VERSION ""

NS_ :

BS_:
BU_: Turbocharger OnBoardDataLogger OffBoardDiagnosticTool2 OffBoardDiagnosticTool1 FileServer ParkingBrakeController SeatControl2 FanDriveController SteeringColumnUnit CommunicationUnitRadio CommunicationUnitSatellite CommunicationUnitCellular PropulsionBatteryCharger ChassisController2 ChassisController1 EngineValveControl AuxiliaryHeater2 AuxiliaryHeater1 ClutchUnit RampControl InformationSystem1 SuspensionSystemController2 OilSensor VehicleDynamicStability ExhaustEmissionController TransmissionDisplay2 TransmissionDisplay1 ClimateControl2 WaterPumpController RearAxleSteeringController LightingOperatorControl SeatController1 IgnitionController2 IgnitionController1 TirePressureController CabController2 CabController1 PneumaticSystemController SuspensionSystemController1 HydraulicPumpController EnduranceBrakingSystem RetarderExhaustEngine2 OnBoardDiagnosticUnit HeadwayController RetarderExhaustEngine1 CabDisplay1 ManagementComputer VirtualTerminal OffVehicleGateway PowerTakeOffFront HitchControl AuxiliaryValveControl BodyController TractorTrailerBridge1 StarterSystem ElectricalSystem VehicleSecurity VehicleNavigation AerodynamicControl ElectricalChargingSystem ClimateControl1 TripRecorder InstrumentCluster SuspensionDriveAxle2 SuspensionDriveAxle1 SuspensionSteerAxle SteeringController FuelSystem CruiseControl RetarderDriveline RetarderEngine BrakesDriveAxle2 BrakesDriveAxle1 BrakesSystemController BrakesSteerAxle AxleDrive2 AxleDrive1 AxleSteering PowerTakeOff ShiftConsoleSecondary ShiftConsolePrimary Transmission2 Transmission1 Engine2 Engine1 Guidance Unnamed9933

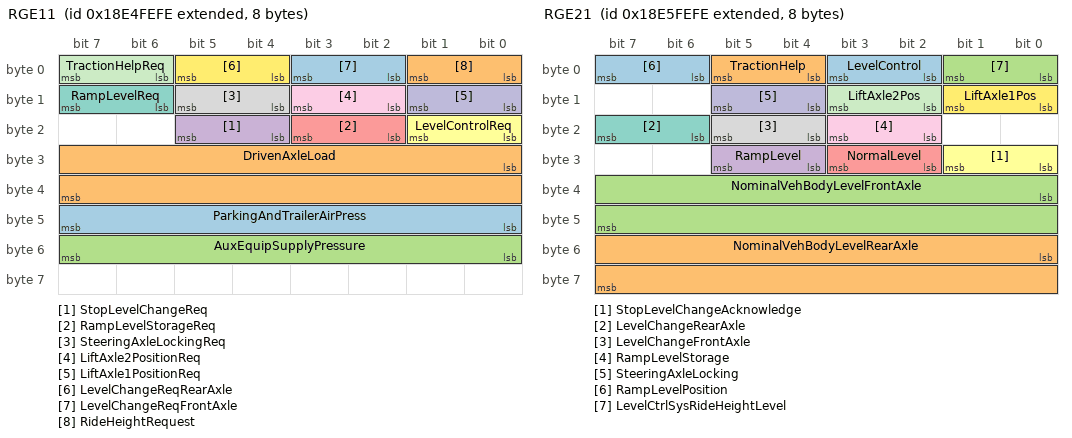
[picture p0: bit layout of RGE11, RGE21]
BO_ 2565144318 RGE11: 8 Vector__XXX
   SG_ ParkingAndTrailerAirPress : 40|8@1+ (8,0) [0|2000] "kPa" Vector__XXX
   SG_ DrivenAxleLoad : 24|16@1+ (2,0) [0|128510] "kg" Vector__XXX
   SG_ AuxEquipSupplyPressure : 48|8@1+ (8,0) [0|2000] "kPa" Vector__XXX
   SG_ StopLevelChangeReq : 20|2@1+ (1,0) [0|3] "" Vector__XXX
   SG_ RampLevelStorageReq : 18|2@1+ (1,0) [0|3] "" Vector__XXX
   SG_ LevelControlReq : 16|2@1+ (1,0) [0|3] "" Vector__XXX
   SG_ RampLevelReq : 14|2@1+ (1,0) [0|3] "" Vector__XXX
   SG_ SteeringAxleLockingReq : 12|2@1+ (1,0) [0|3] "" Vector__XXX
   SG_ LiftAxle2PositionReq : 10|2@1+ (1,0) [0|3] "" Vector__XXX
   SG_ LiftAxle1PositionReq : 8|2@1+ (1,0) [0|3] "" Vector__XXX
   SG_ TractionHelpReq : 6|2@1+ (1,0) [0|3] "" Vector__XXX
   SG_ LevelChangeReqRearAxle : 4|2@1+ (1,0) [0|3] "" Vector__XXX
   SG_ LevelChangeReqFrontAxle : 2|2@1+ (1,0) [0|3] "" Vector__XXX
   SG_ RideHeightRequest : 0|2@1+ (1,0) [0|3] "" Vector__XXX

BO_ 2565209854 RGE21: 8 Vector__XXX
   SG_ LevelControl : 2|2@1+ (1,0) [0|1] "" Vector__XXX
   SG_ NominalVehBodyLevelRearAxle : 48|16@1+ (1,0) [0|64255] "mm" Vector__XXX
   SG_ NominalVehBodyLevelFrontAxle : 32|16@1+ (1,0) [0|64255] "mm" Vector__XXX
   SG_ RampLevel : 28|2@1+ (1,0) [0|1] "" Vector__XXX
   SG_ NormalLevel : 26|2@1+ (1,0) [0|3] "" Vector__XXX
   SG_ StopLevelChangeAcknowledge : 24|2@1+ (1,0) [0|1] "" Vector__XXX
   SG_ LevelChangeRearAxle : 22|2@1+ (1,0) [0|1] "" Vector__XXX
   SG_ LevelChangeFrontAxle : 20|2@1+ (1,0) [0|1] "" Vector__XXX
   SG_ RampLevelStorage : 18|2@1+ (1,0) [0|1] "" Vector__XXX
   SG_ SteeringAxleLocking : 12|2@1+ (1,0) [0|3] "" Vector__XXX
   SG_ LiftAxle2Pos : 10|2@1+ (1,0) [0|3] "" Vector__XXX
   SG_ LiftAxle1Pos : 8|2@1+ (1,0) [0|3] "" Vector__XXX
   SG_ RampLevelPosition : 6|2@1+ (1,0) [0|3] "" Vector__XXX
   SG_ TractionHelp : 4|2@1+ (1,0) [0|1] "" Vector__XXX
   SG_ LevelCtrlSysRideHeightLevel : 0|2@1+ (1,0) [0|1] "" Vector__XXX

BO_ 2566806782 RGE22: 8 Vector__XXX
   SG_ RelVehBodyLevelRearAxle : 16|16@1+ (1,0) [0|64255] "mm" Vector__XXX
   SG_ RelVehBodyLevelFrontAxle : 0|16@1+ (1,-32000) [-32000|32255] "mm" Vector__XXX

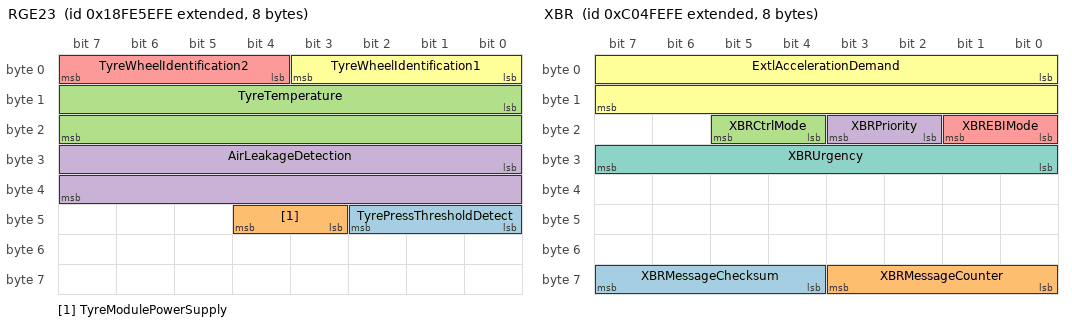
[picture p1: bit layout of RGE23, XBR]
BO_ 2566807294 RGE23: 8 Vector__XXX
   SG_ TyrePressThresholdDetect : 40|3@1+ (1,0) [0|7] "" Vector__XXX
   SG_ TyreModulePowerSupply : 43|2@1+ (1,0) [0|1] "" Vector__XXX
   SG_ TyreTemperature : 8|16@1+ (0.03125,-273) [-273|1735] "deg C" Vector__XXX
   SG_ AirLeakageDetection : 24|16@1+ (0.1,0) [0|6425.5] "Pa/s" Vector__XXX
   SG_ TyreWheelIdentification2 : 4|4@1+ (1,0) [0|15] "" Vector__XXX
   SG_ TyreWheelIdentification1 : 0|4@1+ (1,0) [0|15] "" Vector__XXX

BO_ 2566764798 DM26: 8 Vector__XXX
   SG_ NMHCConvertingCatalystCompleted : 60|1@1+ (1,0) [0|1] "" Vector__XXX
   SG_ NMHCConvertingCatalystEnabled : 44|1@1+ (1,0) [0|1] "" Vector__XXX
   SG_ NOxConvertingCatalystAdsorberCom : 59|1@1+ (1,0) [0|1] "" Vector__XXX
   SG_ NOxConvertingCatalystAdsorberEna : 43|1@1+ (1,0) [0|1] "" Vector__XXX
   SG_ DieselParticulateFilterCompleted : 58|1@1+ (1,0) [0|1] "" Vector__XXX
   SG_ DieselParticulateFilterEnabled : 42|1@1+ (1,0) [0|1] "" Vector__XXX
   SG_ BoostPressureControlSystemComple : 57|1@1+ (1,0) [0|1] "" Vector__XXX
   SG_ BoostPressureCtrlSystemEnabled : 41|1@1+ (1,0) [0|1] "" Vector__XXX
   SG_ MisfireMonitoringComplete : 28|1@1+ (1,0) [0|1] "" Vector__XXX
   SG_ MisfireMonitoringEnabled : 24|1@1+ (1,0) [0|0] "" Vector__XXX
   SG_ FuelSystemMonitoringEnabled : 25|1@1+ (1,0) [0|1] "" Vector__XXX
   SG_ ComprehensiveComptMonComplete : 30|1@1+ (1,0) [0|1] "" Vector__XXX
   SG_ ComprehensiveCompMonEnabled : 26|1@1+ (1,0) [0|1] "" Vector__XXX
   SG_ SecondAirSystemMonComplete : 51|1@1+ (1,0) [0|1] "" Vector__XXX
   SG_ SecondAirSystemMonEnabled : 35|1@1+ (1,0) [0|1] "" Vector__XXX
   SG_ OxygenSensorMonComplete : 53|1@1+ (1,0) [0|1] "" Vector__XXX
   SG_ OxygenSensorMonEnabled : 37|1@1+ (1,0) [0|1] "" Vector__XXX
   SG_ OxygenSensorHeaterMonComplete : 54|1@1+ (1,0) [0|1] "" Vector__XXX
   SG_ OxygenSensorHeaterMonEnabled : 38|1@1+ (1,0) [0|1] "" Vector__XXX
   SG_ HeatedCatalystMonComplete : 49|1@1+ (1,0) [0|1] "" Vector__XXX
   SG_ HeatedCatalystMonEnabled : 33|1@1+ (1,0) [0|1] "" Vector__XXX
   SG_ EvaporativeSystemMonComplete : 50|1@1+ (1,0) [0|1] "" Vector__XXX
   SG_ EvaporativeSystemMonEnabled : 34|1@1+ (1,0) [0|1] "" Vector__XXX
   SG_ EGRSystemMonitoringComplete : 55|1@1+ (1,0) [0|1] "" Vector__XXX
   SG_ EGRSystemMonitoringEnabled : 39|1@1+ (1,0) [0|1] "" Vector__XXX
   SG_ ColdStartAidSystemMonComplete : 56|1@1+ (1,0) [0|1] "" Vector__XXX
   SG_ ColdStartAidSystemMonEnabled : 40|1@1+ (1,0) [0|1] "" Vector__XXX
   SG_ CatalystMonComplete : 48|1@1+ (1,0) [0|1] "" Vector__XXX
   SG_ CatalystMonEnabled : 32|1@1+ (1,0) [0|1] "" Vector__XXX
   SG_ ACSystemRefrigerantMonComplete : 52|1@1+ (1,0) [0|1] "" Vector__XXX
   SG_ ACSystemRefrigerantMonEnabled : 36|1@1+ (1,0) [0|1] "" Vector__XXX
   SG_ FuelSystemMonitoringComplete : 29|1@1+ (1,0) [0|1] "" Vector__XXX
   SG_ NumOfWarmUpsSinceDTCsCleared : 16|8@1+ (1,0) [0|250] "" Vector__XXX
   SG_ TimeSinceEngineStart : 0|16@1+ (1,0) [0|64255] "sec" Vector__XXX

BO_ 2564095742 DM18: 8 Vector__XXX
   SG_ SecurityEntityLengthHigh : 12|4@1+ (1,0) [0|255] "Byte" Vector__XXX
   SG_ SecurityEntityType : 8|4@1+ (1,0) [0|15] "" Vector__XXX
   SG_ SecurityEntityLength : 0|8@1+ (1,0) [0|1785] "Byte" Vector__XXX

BO_ 2349137662 XBR: 8 Vector__XXX
   SG_ XBRMessageChecksum : 60|4@1+ (1,0) [0|15] "" Vector__XXX
   SG_ XBRMessageCounter : 56|4@1+ (1,0) [0|15] "" Vector__XXX
   SG_ XBRCtrlMode : 20|2@1+ (1,0) [0|3] "" Vector__XXX
   SG_ XBRPriority : 18|2@1+ (1,0) [0|3] "" Vector__XXX
   SG_ XBREBIMode : 16|2@1+ (1,0) [0|3] "" Vector__XXX
   SG_ ExtlAccelerationDemand : 0|16@1+ (0.000488281,-15.687) [-15.687|15.687] "m/s/s" Vector__XXX
   SG_ XBRUrgency : 24|8@1+ (0.4,0) [0|100] "%" Vector__XXX

BO_ 2566848510 WFI: 8 Vector__XXX
   SG_ WaterInFuelIndicator : 0|2@1+ (1,0) [0|3] "" Vector__XXX

BO_ 2566843134 VW: 8 Vector__XXX
   SG_ AxleLocation M : 0|8@1+ (1,0) [0|255] "" Vector__XXX
   SG_ CargoWeight_30 m48 : 40|16@1+ (2,0) [0|128510] "kg" Vector__XXX
   SG_ CargoWeight_20 m32 : 40|16@1+ (2,0) [0|128510] "kg" Vector__XXX
   SG_ CargoWeight_10 m16 : 40|16@1+ (2,0) [0|128510] "kg" Vector__XXX
   SG_ CargoWeight_00 m0 : 40|16@1+ (2,0) [0|128510] "kg" Vector__XXX
   SG_ TrailerWeight_30 m48 : 24|16@1+ (2,0) [0|128510] "kg" Vector__XXX
   SG_ TrailerWeight_20 m32 : 24|16@1+ (2,0) [0|128510] "kg" Vector__XXX
   SG_ TrailerWeight_10 m16 : 24|16@1+ (2,0) [0|128510] "kg" Vector__XXX
   SG_ TrailerWeight_00 m0 : 24|16@1+ (2,0) [0|128510] "kg" Vector__XXX
   SG_ AxleWeight_30 m48 : 8|16@1+ (0.5,0) [0|32127.5] "kg" Vector__XXX
   SG_ AxleWeight_20 m32 : 8|16@1+ (0.5,0) [0|32127.5] "kg" Vector__XXX
   SG_ AxleWeight_10 m16 : 8|16@1+ (0.5,0) [0|32127.5] "kg" Vector__XXX
   SG_ AxleWeight_00 m0 : 8|16@1+ (0.5,0) [0|32127.5] "kg" Vector__XXX

BO_ 2566804222 VEP3: 8 Vector__XXX
   SG_ NetBatteryCurrentHiRes : 16|16@1+ (0.05,-1600) [-1600|1612.75] "A" Vector__XXX
   SG_ AltCurrentHiRes : 0|16@1+ (0.05,-1600) [-1600|1676.75] "A" Vector__XXX

BO_ 2633928190 VEP2: 8 Vector__XXX
   SG_ ECUPowerOutputSupplyVoltage3 : 48|16@1+ (0.05,0) [0|3212.75] "V" Vector__XXX
   SG_ ECUPowerOutputSupplyVoltage2 : 32|16@1+ (0.05,0) [0|3212.75] "V" Vector__XXX
   SG_ ECUPowerOutputSupplyVoltage1 : 16|16@1+ (0.05,0) [0|3212.75] "V" Vector__XXX
   SG_ BatteryPotential_PowerInput2 : 0|16@1+ (0.05,0) [0|3212.75] "V" Vector__XXX

BO_ 2566845438 VP: 8 Vector__XXX
   SG_ Longitude : 32|32@1+ (10,-210) [-210|211.101] "deg" Vector__XXX
   SG_ Latitude : 0|32@1+ (10,-210) [-210|211.101] "deg" Vector__XXX

BO_ 2566843646 VI: 8 Vector__XXX
   SG_ VehicleIdentificationNumber : 0|8@1+ (1,0) [0|255] "" Vector__XXX

BO_ 2566842366 VH: 8 Vector__XXX
   SG_ TotalPowerTakeoffHours : 32|32@1+ (0.05,0) [0|2.10554e+08] "hr" Vector__XXX
   SG_ TotalVehicleHours : 0|32@1+ (0.05,0) [0|2.10554e+08] "hr" Vector__XXX

BO_ 2566809854 VF: 8 Vector__XXX
   SG_ WinchOilPressSwitch : 10|2@1+ (1,0) [0|3] "" Vector__XXX
   SG_ HydOilLevel : 16|8@1+ (0.4,0) [0|100] "%" Vector__XXX
   SG_ HydOilFilterRestrictionSwitch : 8|2@1+ (1,0) [0|3] "" Vector__XXX
   SG_ HydTemp : 0|8@1+ (1,-40) [-40|210] "deg C" Vector__XXX

BO_ 2566842622 VDS: 8 Vector__XXX
   SG_ Altitude : 48|16@1+ (0.125,-2500) [-2500|5531.88] "m" Vector__XXX
   SG_ Pitch : 32|16@1+ (0.0078125,-200) [-200|301.99] "deg" Vector__XXX
   SG_ NavigationBasedVehicleSpeed : 16|16@1+ (0.00390625,0) [0|250.996] "km/h" Vector__XXX
   SG_ CompassBearing : 0|16@1+ (0.0078125,0) [0|501.99] "deg" Vector__XXX

BO_ 2566832638 VDHR: 8 Vector__XXX
   SG_ HighResolutionTripDistance : 32|32@1+ (5,0) [0|2.10554e+07] "km" Vector__XXX
   SG_ HghRslutionTotalVehicleDistance : 0|32@1+ (5,0) [0|2.10554e+07] "km" Vector__XXX

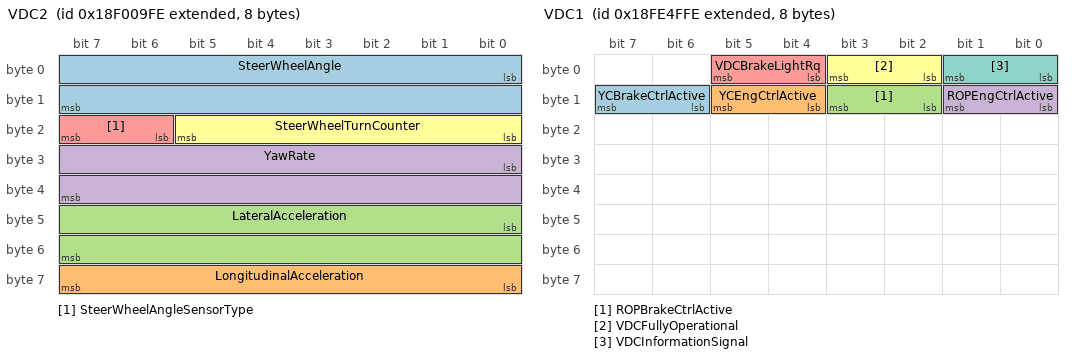
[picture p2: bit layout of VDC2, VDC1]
BO_ 2565868030 VDC2: 8 Vector__XXX
   SG_ SteerWheelAngle : 0|16@1+ (0.000976563,-31.374) [-31.374|31.374] "rad" Vector__XXX
   SG_ LongitudinalAcceleration : 56|8@1+ (0.1,-12.5) [-12.5|12.5] "m/s/s" Vector__XXX
   SG_ LateralAcceleration : 40|16@1+ (0.000488281,-15.687) [-15.687|15.687] "m/s/s" Vector__XXX
   SG_ YawRate : 24|16@1+ (0.00012207,-3.92) [-3.92|3.92] "rad/s" Vector__XXX
   SG_ SteerWheelAngleSensorType : 22|2@1+ (1,0) [0|3] "" Vector__XXX
   SG_ SteerWheelTurnCounter : 16|6@1+ (1,-32) [-32|29] "turns" Vector__XXX

BO_ 2566803454 VDC1: 8 Vector__XXX
   SG_ YCBrakeCtrlActive : 14|2@1+ (1,0) [0|3] "" Vector__XXX
   SG_ YCEngCtrlActive : 12|2@1+ (1,0) [0|3] "" Vector__XXX
   SG_ ROPBrakeCtrlActive : 10|2@1+ (1,0) [0|3] "" Vector__XXX
   SG_ ROPEngCtrlActive : 8|2@1+ (1,0) [0|3] "" Vector__XXX
   SG_ VDCBrakeLightRq : 4|2@1+ (1,0) [0|3] "" Vector__XXX
   SG_ VDCFullyOperational : 2|2@1+ (1,0) [0|3] "" Vector__XXX
   SG_ VDCInformationSignal : 0|2@1+ (1,0) [0|3] "" Vector__XXX

BO_ 2566840574 VD: 8 Vector__XXX
   SG_ TotalVehicleDistance : 32|32@1+ (0.125,0) [0|5.26385e+08] "km" Vector__XXX
   SG_ TripDistance : 0|32@1+ (0.125,0) [0|5.26385e+08] "km" Vector__XXX

BO_ 2633938686 TVI: 8 Vector__XXX
   SG_ TripCruiseDistance : 16|32@1+ (0.125,0) [0|5.26385e+08] "km" Vector__XXX
   SG_ TripMaxVehicleSpeed : 0|16@1+ (0.00390625,0) [0|250.996] "km/h" Vector__XXX

BO_ 2633937150 TTI2: 20 Vector__XXX
   SG_ TripAirCompressorOnTime : 128|32@1+ (0.05,0) [0|2.10554e+08] "hr" Vector__XXX
   SG_ TripIdleTime : 96|32@1+ (0.05,0) [0|2.10554e+08] "hr" Vector__XXX
   SG_ TripEngRunningTime : 64|32@1+ (0.05,0) [0|2.10554e+08] "hr" Vector__XXX
   SG_ TripCruiseTime : 0|32@1+ (0.05,0) [0|2.10554e+08] "hr" Vector__XXX
   SG_ TripPTOGovernorTime : 32|32@1+ (0.05,0) [0|2.10554e+08] "hr" Vector__XXX

BO_ 2633938174 TTI1: 16 Vector__XXX
   SG_ TripTimeInDerateByEng : 96|32@1+ (0.05,0) [0|2.10554e+08] "hr" Vector__XXX
   SG_ TripTimeInGearDown : 64|32@1+ (0.05,0) [0|2.10554e+08] "hr" Vector__XXX
   SG_ TripTimeInTopGear : 32|32@1+ (0.05,0) [0|2.10554e+08] "hr" Vector__XXX
   SG_ TripTimeInVSL : 0|32@1+ (0.05,0) [0|2.10554e+08] "hr" Vector__XXX

BO_ 2633938430 TSI: 8 Vector__XXX
   SG_ TripSuddenDecelerations : 48|16@1+ (1,0) [0|64255] "counts" Vector__XXX
   SG_ TrpNmberOfIdleShutdownOverrides : 32|16@1+ (1,0) [0|64255] "counts" Vector__XXX
   SG_ TripNumberOfIdleShutdowns : 16|16@1+ (1,0) [0|64255] "counts" Vector__XXX
   SG_ TripNumberOfHotShutdowns : 0|16@1+ (1,0) [0|64255] "counts" Vector__XXX

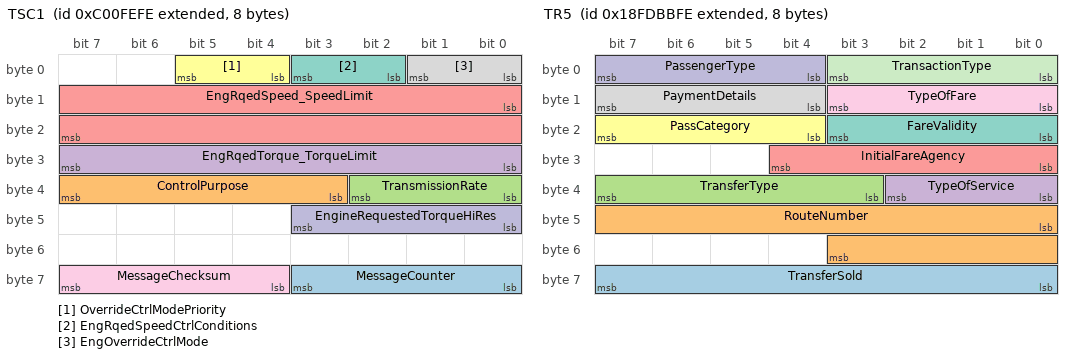
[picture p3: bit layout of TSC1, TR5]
BO_ 2348875518 TSC1: 8 Vector__XXX
   SG_ MessageCounter : 56|4@1+ (1,0) [0|15] "" Vector__XXX
   SG_ ControlPurpose : 35|5@1+ (1,0) [0|31] "" Vector__XXX
   SG_ TransmissionRate : 32|3@1+ (1,0) [0|7] "" Vector__XXX
   SG_ EngRqedTorque_TorqueLimit : 24|8@1+ (1,-125) [-125|125] "%" Vector__XXX
   SG_ EngRqedSpeed_SpeedLimit : 8|16@1+ (0.125,0) [0|8031.88] "rpm" Vector__XXX
   SG_ OverrideCtrlModePriority : 4|2@1+ (1,0) [0|3] "" Vector__XXX
   SG_ EngRqedSpeedCtrlConditions : 2|2@1+ (1,0) [0|3] "" Vector__XXX
   SG_ EngOverrideCtrlMode : 0|2@1+ (1,0) [0|3] "" Vector__XXX
   SG_ MessageChecksum : 60|4@1+ (1,0) [0|15] "" Vector__XXX
   SG_ EngineRequestedTorqueHiRes : 40|4@1+ (0.125,0) [0|0.875] "%" Vector__XXX

BO_ 2566766846 TR7: 8 Vector__XXX
   SG_ TransitRunStatus : 20|2@1+ (1,0) [0|3] "" Vector__XXX
   SG_ VehicleUseStatus : 18|2@1+ (1,0) [0|3] "" Vector__XXX
   SG_ SilentAlarmStatus : 16|2@1+ (1,0) [0|3] "" Vector__XXX
   SG_ PatronCount : 8|8@1+ (1,0) [0|250] "" Vector__XXX
   SG_ TypeOfPassengerCount : 0|8@1+ (1,0) [0|255] "" Vector__XXX

BO_ 2566765310 TR6: 8 Vector__XXX
   SG_ FareboxAlarmIdentifier : 8|7@1+ (1,0) [0|127] "" Vector__XXX
   SG_ FareboxEmergencyStatus : 0|2@1+ (1,0) [0|3] "" Vector__XXX

BO_ 2566765566 TR5: 8 Vector__XXX
   SG_ TransferSold : 56|8@1+ (1,0) [0|255] "" Vector__XXX
   SG_ RouteNumber : 40|12@1+ (1,0) [0|4095] "" Vector__XXX
   SG_ TransferType : 35|5@1+ (1,0) [0|31] "" Vector__XXX
   SG_ TypeOfService : 32|3@1+ (1,0) [0|7] "" Vector__XXX
   SG_ InitialFareAgency : 24|5@1+ (1,0) [0|31] "" Vector__XXX
   SG_ PassCategory : 20|4@1+ (1,0) [0|15] "" Vector__XXX
   SG_ FareValidity : 16|4@1+ (1,0) [0|15] "" Vector__XXX
   SG_ PaymentDetails : 12|4@1+ (1,0) [0|15] "" Vector__XXX
   SG_ TypeOfFare : 8|4@1+ (1,0) [0|15] "" Vector__XXX
   SG_ PassengerType : 4|4@1+ (1,0) [0|15] "" Vector__XXX
   SG_ TransactionType : 0|4@1+ (1,0) [0|15] "" Vector__XXX

BO_ 2566765822 TR4: 15 Vector__XXX
   SG_ DriversFareboxSecurityCode : 104|16@1+ (1,0) [0|65535] "counts" Vector__XXX
   SG_ AssignedBlock : 88|16@1+ (1,0) [0|65535] "counts" Vector__XXX
   SG_ AssignedRun : 72|16@1+ (1,0) [0|65535] "counts" Vector__XXX
   SG_ AssignedRoute : 56|16@1+ (1,0) [0|65535] "counts" Vector__XXX
   SG_ PatternNumber : 40|16@1+ (1,0) [0|65535] "counts" Vector__XXX
   SG_ TripNumber : 24|16@1+ (1,0) [0|65535] "counts" Vector__XXX
   SG_ FarePresets : 16|8@1+ (1,0) [0|255] "" Vector__XXX
   SG_ TripDirection : 8|4@1+ (1,0) [0|15] "" Vector__XXX
   SG_ TripStatus : 2|3@1+ (1,0) [0|7] "" Vector__XXX
   SG_ FareboxServiceStatus : 0|2@1+ (1,0) [0|3] "" Vector__XXX

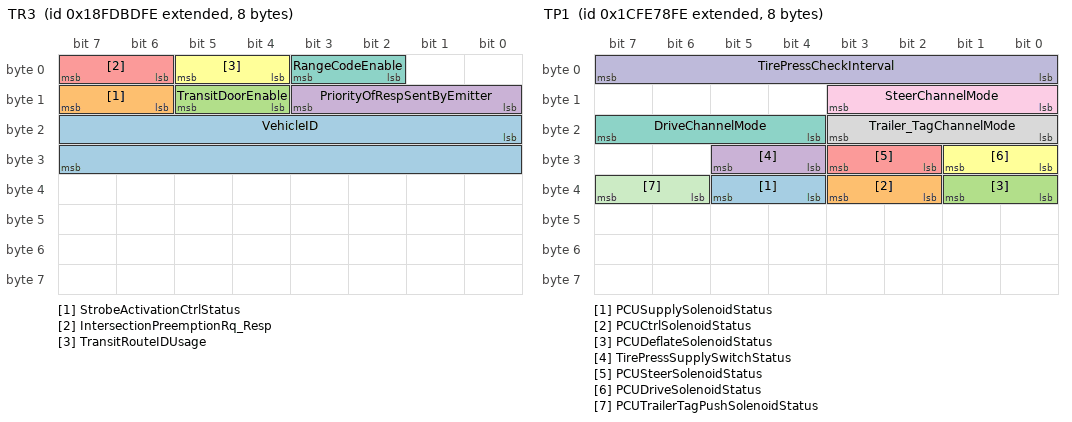
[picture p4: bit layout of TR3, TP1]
BO_ 2566766078 TR3: 8 Vector__XXX
   SG_ VehicleID : 16|16@1+ (1,0) [0|65535] "counts" Vector__XXX
   SG_ StrobeActivationCtrlStatus : 14|2@1+ (1,0) [0|3] "" Vector__XXX
   SG_ TransitDoorEnable : 12|2@1+ (1,0) [0|3] "" Vector__XXX
   SG_ PriorityOfRespSentByEmitter : 8|4@1+ (1,0) [0|15] "" Vector__XXX
   SG_ IntersectionPreemptionRq_Resp : 6|2@1+ (1,0) [0|3] "" Vector__XXX
   SG_ TransitRouteIDUsage : 4|2@1+ (1,0) [0|3] "" Vector__XXX
   SG_ RangeCodeEnable : 2|2@1+ (1,0) [0|3] "" Vector__XXX

BO_ 2566766590 TR2: 8 Vector__XXX
   SG_ NmbrOfBytsInMlpstIdentification : 0|8@1+ (1,0) [0|250] "" Vector__XXX

BO_ 2566766334 TR1: 4 Vector__XXX
   SG_ Agency : 0|8@1+ (1,0) [0|255] "" Vector__XXX
   SG_ NmbrOfBytsInTrnstAssgndBlckIdntt : 24|8@1+ (1,0) [0|250] "" Vector__XXX
   SG_ NmbrOfBytsInTrnstAssgndRnIdntty : 16|8@1+ (1,0) [0|250] "" Vector__XXX
   SG_ NmbrOfBytsInTrnstAssgndRtIdntty : 8|8@1+ (1,0) [0|250] "" Vector__XXX

BO_ 2561605374 TPRS: 8 Vector__XXX
   SG_ ReferenceTirePressSetting_33 m51 : 8|8@1+ (8,0) [0|2000] "kPa" Vector__XXX
   SG_ ReferenceTirePressSetting_32 m50 : 8|8@1+ (8,0) [0|2000] "kPa" Vector__XXX
   SG_ ReferenceTirePressSetting_31 m49 : 8|8@1+ (8,0) [0|2000] "kPa" Vector__XXX
   SG_ ReferenceTirePressSetting_30 m48 : 8|8@1+ (8,0) [0|2000] "kPa" Vector__XXX
   SG_ ReferenceTirePressSetting_23 m35 : 8|8@1+ (8,0) [0|2000] "kPa" Vector__XXX
   SG_ ReferenceTirePressSetting_22 m34 : 8|8@1+ (8,0) [0|2000] "kPa" Vector__XXX
   SG_ ReferenceTirePressSetting_21 m33 : 8|8@1+ (8,0) [0|2000] "kPa" Vector__XXX
   SG_ ReferenceTirePressSetting_20 m32 : 8|8@1+ (8,0) [0|2000] "kPa" Vector__XXX
   SG_ ReferenceTirePressSetting_13 m19 : 8|8@1+ (8,0) [0|2000] "kPa" Vector__XXX
   SG_ ReferenceTirePressSetting_12 m18 : 8|8@1+ (8,0) [0|2000] "kPa" Vector__XXX
   SG_ ReferenceTirePressSetting_11 m17 : 8|8@1+ (8,0) [0|2000] "kPa" Vector__XXX
   SG_ ReferenceTirePressSetting_10 m16 : 8|8@1+ (8,0) [0|2000] "kPa" Vector__XXX
   SG_ ReferenceTirePressSetting_01 m1 : 8|8@1+ (8,0) [0|2000] "kPa" Vector__XXX
   SG_ ReferenceTirePressSetting_00 m0 : 8|8@1+ (8,0) [0|2000] "kPa" Vector__XXX
   SG_ TireLocation M : 0|8@1+ (1,0) [0|255] "" Vector__XXX

BO_ 2566765054 TPRI: 8 Vector__XXX
   SG_ ReferenceTirePress_33 m51 : 8|8@1+ (8,0) [0|2000] "kPa" Vector__XXX
   SG_ ReferenceTirePress_32 m50 : 8|8@1+ (8,0) [0|2000] "kPa" Vector__XXX
   SG_ ReferenceTirePress_31 m49 : 8|8@1+ (8,0) [0|2000] "kPa" Vector__XXX
   SG_ ReferenceTirePress_30 m48 : 8|8@1+ (8,0) [0|2000] "kPa" Vector__XXX
   SG_ ReferenceTirePress_23 m35 : 8|8@1+ (8,0) [0|2000] "kPa" Vector__XXX
   SG_ ReferenceTirePress_22 m34 : 8|8@1+ (8,0) [0|2000] "kPa" Vector__XXX
   SG_ ReferenceTirePress_21 m33 : 8|8@1+ (8,0) [0|2000] "kPa" Vector__XXX
   SG_ ReferenceTirePress_20 m32 : 8|8@1+ (8,0) [0|2000] "kPa" Vector__XXX
   SG_ ReferenceTirePress_13 m19 : 8|8@1+ (8,0) [0|2000] "kPa" Vector__XXX
   SG_ ReferenceTirePress_12 m18 : 8|8@1+ (8,0) [0|2000] "kPa" Vector__XXX
   SG_ ReferenceTirePress_11 m17 : 8|8@1+ (8,0) [0|2000] "kPa" Vector__XXX
   SG_ ReferenceTirePress_10 m16 : 8|8@1+ (8,0) [0|2000] "kPa" Vector__XXX
   SG_ ReferenceTirePress_01 m1 : 8|8@1+ (8,0) [0|2000] "kPa" Vector__XXX
   SG_ ReferenceTirePress_00 m0 : 8|8@1+ (8,0) [0|2000] "kPa" Vector__XXX
   SG_ TireLocation M : 0|8@1+ (1,0) [0|255] "" Vector__XXX

BO_ 2633923326 TP3: 8 Vector__XXX
   SG_ SteerChannelTirePress : 32|16@1+ (0.5,0) [0|32127.5] "kPa" Vector__XXX
   SG_ DriveChannelTirePress : 16|16@1+ (0.5,0) [0|32127.5] "kPa" Vector__XXX
   SG_ TrailerTagPushChannelTirePress : 0|16@1+ (0.5,0) [0|32127.5] "kPa" Vector__XXX

BO_ 2633923070 TP2: 8 Vector__XXX
   SG_ SteerChannelTirePressTarget : 32|16@1+ (0.5,0) [0|32127.5] "kPa" Vector__XXX
   SG_ DriveChannelTirePressTarget : 16|16@1+ (0.5,0) [0|32127.5] "kPa" Vector__XXX
   SG_ TrlrTgPshChannelTirePressTarget : 0|16@1+ (0.5,0) [0|32127.5] "kPa" Vector__XXX

BO_ 2633922814 TP1: 8 Vector__XXX
   SG_ PCUSupplySolenoidStatus : 36|2@1+ (1,0) [0|3] "" Vector__XXX
   SG_ PCUCtrlSolenoidStatus : 34|2@1+ (1,0) [0|3] "" Vector__XXX
   SG_ PCUDeflateSolenoidStatus : 32|2@1+ (1,0) [0|3] "" Vector__XXX
   SG_ TirePressSupplySwitchStatus : 28|2@1+ (1,0) [0|3] "" Vector__XXX
   SG_ PCUSteerSolenoidStatus : 26|2@1+ (1,0) [0|3] "" Vector__XXX
   SG_ PCUDriveSolenoidStatus : 24|2@1+ (1,0) [0|3] "" Vector__XXX
   SG_ DriveChannelMode : 20|4@1+ (1,0) [0|15] "" Vector__XXX
   SG_ Trailer_TagChannelMode : 16|4@1+ (1,0) [0|15] "" Vector__XXX
   SG_ SteerChannelMode : 8|4@1+ (1,0) [0|15] "" Vector__XXX
   SG_ TirePressCheckInterval : 0|8@1+ (1,0) [0|250] "mins" Vector__XXX
   SG_ PCUTrailerTagPushSolenoidStatus : 38|2@1+ (1,0) [0|3] "" Vector__XXX

BO_ 2566845694 TIRE: 8 Vector__XXX
   SG_ TirePressThresholdDetection_13 m19 : 61|3@1+ (1,0) [0|7] "" Vector__XXX
   SG_ TirePressThresholdDetection_12 m18 : 61|3@1+ (1,0) [0|7] "" Vector__XXX
   SG_ TirePressThresholdDetection_11 m17 : 61|3@1+ (1,0) [0|7] "" Vector__XXX
   SG_ TirePressThresholdDetection_10 m16 : 61|3@1+ (1,0) [0|7] "" Vector__XXX
   SG_ TirePressThresholdDetection_01 m1 : 61|3@1+ (1,0) [0|7] "" Vector__XXX
   SG_ TirePress_33 m51 : 8|8@1+ (4,0) [0|1000] "kPa" Vector__XXX
   SG_ TirePress_32 m50 : 8|8@1+ (4,0) [0|1000] "kPa" Vector__XXX
   SG_ TirePress_31 m49 : 8|8@1+ (4,0) [0|1000] "kPa" Vector__XXX
   SG_ TirePress_30 m48 : 8|8@1+ (4,0) [0|1000] "kPa" Vector__XXX
   SG_ TirePress_23 m35 : 8|8@1+ (4,0) [0|1000] "kPa" Vector__XXX
   SG_ TirePress_22 m34 : 8|8@1+ (4,0) [0|1000] "kPa" Vector__XXX
   SG_ TirePress_21 m33 : 8|8@1+ (4,0) [0|1000] "kPa" Vector__XXX
   SG_ TirePress_20 m32 : 8|8@1+ (4,0) [0|1000] "kPa" Vector__XXX
   SG_ TirePress_13 m19 : 8|8@1+ (4,0) [0|1000] "kPa" Vector__XXX
   SG_ TirePress_12 m18 : 8|8@1+ (4,0) [0|1000] "kPa" Vector__XXX
   SG_ TirePress_11 m17 : 8|8@1+ (4,0) [0|1000] "kPa" Vector__XXX
   SG_ TirePress_10 m16 : 8|8@1+ (4,0) [0|1000] "kPa" Vector__XXX
   SG_ TireAirLeakageRate_33 m51 : 40|16@1+ (0.1,0) [0|6425.5] "Pa/s" Vector__XXX
   SG_ TireAirLeakageRate_32 m50 : 40|16@1+ (0.1,0) [0|6425.5] "Pa/s" Vector__XXX
   SG_ TireAirLeakageRate_31 m49 : 40|16@1+ (0.1,0) [0|6425.5] "Pa/s" Vector__XXX
   SG_ TireAirLeakageRate_30 m48 : 40|16@1+ (0.1,0) [0|6425.5] "Pa/s" Vector__XXX
   SG_ TireAirLeakageRate_23 m35 : 40|16@1+ (0.1,0) [0|6425.5] "Pa/s" Vector__XXX
   SG_ TireAirLeakageRate_22 m34 : 40|16@1+ (0.1,0) [0|6425.5] "Pa/s" Vector__XXX
   SG_ TireAirLeakageRate_21 m33 : 40|16@1+ (0.1,0) [0|6425.5] "Pa/s" Vector__XXX
   SG_ TireAirLeakageRate_20 m32 : 40|16@1+ (0.1,0) [0|6425.5] "Pa/s" Vector__XXX
   SG_ TireAirLeakageRate_13 m19 : 40|16@1+ (0.1,0) [0|6425.5] "Pa/s" Vector__XXX
   SG_ TireAirLeakageRate_12 m18 : 40|16@1+ (0.1,0) [0|6425.5] "Pa/s" Vector__XXX
   SG_ TireAirLeakageRate_11 m17 : 40|16@1+ (0.1,0) [0|6425.5] "Pa/s" Vector__XXX
   SG_ TireAirLeakageRate_10 m16 : 40|16@1+ (0.1,0) [0|6425.5] "Pa/s" Vector__XXX
   SG_ TireAirLeakageRate_01 m1 : 40|16@1+ (0.1,0) [0|6425.5] "Pa/s" Vector__XXX
   SG_ TireAirLeakageRate_00 m0 : 40|16@1+ (0.1,0) [0|6425.5] "Pa/s" Vector__XXX
   SG_ CTIWheelSensorStatus_33 m51 : 32|2@1+ (1,0) [0|3] "" Vector__XXX
   SG_ CTIWheelSensorStatus_32 m50 : 32|2@1+ (1,0) [0|3] "" Vector__XXX
   SG_ CTIWheelSensorStatus_31 m49 : 32|2@1+ (1,0) [0|3] "" Vector__XXX
   SG_ CTIWheelSensorStatus_30 m48 : 32|2@1+ (1,0) [0|3] "" Vector__XXX
   SG_ CTIWheelSensorStatus_23 m35 : 32|2@1+ (1,0) [0|3] "" Vector__XXX
   SG_ CTIWheelSensorStatus_22 m34 : 32|2@1+ (1,0) [0|3] "" Vector__XXX
   SG_ CTIWheelSensorStatus_21 m33 : 32|2@1+ (1,0) [0|3] "" Vector__XXX
   SG_ CTIWheelSensorStatus_20 m32 : 32|2@1+ (1,0) [0|3] "" Vector__XXX
   SG_ CTIWheelSensorStatus_13 m19 : 32|2@1+ (1,0) [0|3] "" Vector__XXX
   SG_ CTIWheelSensorStatus_12 m18 : 32|2@1+ (1,0) [0|3] "" Vector__XXX
   SG_ CTIWheelSensorStatus_11 m17 : 32|2@1+ (1,0) [0|3] "" Vector__XXX
   SG_ CTIWheelSensorStatus_10 m16 : 32|2@1+ (1,0) [0|3] "" Vector__XXX
   SG_ CTIWheelSensorStatus_01 m1 : 32|2@1+ (1,0) [0|3] "" Vector__XXX
   SG_ CTIWheelEndElectricalFault_33 m51 : 36|2@1+ (1,0) [0|3] "" Vector__XXX
   SG_ CTIWheelEndElectricalFault_32 m50 : 36|2@1+ (1,0) [0|3] "" Vector__XXX
   SG_ CTIWheelEndElectricalFault_31 m49 : 36|2@1+ (1,0) [0|3] "" Vector__XXX
   SG_ CTIWheelEndElectricalFault_30 m48 : 36|2@1+ (1,0) [0|3] "" Vector__XXX
   SG_ CTIWheelEndElectricalFault_23 m35 : 36|2@1+ (1,0) [0|3] "" Vector__XXX
   SG_ CTIWheelEndElectricalFault_22 m34 : 36|2@1+ (1,0) [0|3] "" Vector__XXX
   SG_ CTIWheelEndElectricalFault_21 m33 : 36|2@1+ (1,0) [0|3] "" Vector__XXX
   SG_ CTIWheelEndElectricalFault_20 m32 : 36|2@1+ (1,0) [0|3] "" Vector__XXX
   SG_ CTIWheelEndElectricalFault_13 m19 : 36|2@1+ (1,0) [0|3] "" Vector__XXX
   SG_ CTIWheelEndElectricalFault_12 m18 : 36|2@1+ (1,0) [0|3] "" Vector__XXX
   SG_ CTIWheelEndElectricalFault_11 m17 : 36|2@1+ (1,0) [0|3] "" Vector__XXX
   SG_ CTIWheelEndElectricalFault_10 m16 : 36|2@1+ (1,0) [0|3] "" Vector__XXX
   SG_ CTIWheelEndElectricalFault_01 m1 : 36|2@1+ (1,0) [0|3] "" Vector__XXX
   SG_ CTITireStatus_33 m51 : 34|2@1+ (1,0) [0|3] "" Vector__XXX
   SG_ CTITireStatus_32 m50 : 34|2@1+ (1,0) [0|3] "" Vector__XXX
   SG_ CTITireStatus_31 m49 : 34|2@1+ (1,0) [0|3] "" Vector__XXX
   SG_ CTITireStatus_30 m48 : 34|2@1+ (1,0) [0|3] "" Vector__XXX
   SG_ CTITireStatus_23 m35 : 34|2@1+ (1,0) [0|3] "" Vector__XXX
   SG_ CTITireStatus_22 m34 : 34|2@1+ (1,0) [0|3] "" Vector__XXX
   SG_ CTITireStatus_21 m33 : 34|2@1+ (1,0) [0|3] "" Vector__XXX
   SG_ CTITireStatus_20 m32 : 34|2@1+ (1,0) [0|3] "" Vector__XXX
   SG_ CTITireStatus_13 m19 : 34|2@1+ (1,0) [0|3] "" Vector__XXX
   SG_ CTITireStatus_12 m18 : 34|2@1+ (1,0) [0|3] "" Vector__XXX
   SG_ CTITireStatus_11 m17 : 34|2@1+ (1,0) [0|3] "" Vector__XXX
   SG_ CTITireStatus_10 m16 : 34|2@1+ (1,0) [0|3] "" Vector__XXX
   SG_ CTITireStatus_01 m1 : 34|2@1+ (1,0) [0|3] "" Vector__XXX
   SG_ TireTemp_11 m17 : 16|16@1+ (0.03125,-273) [-273|1735] "deg C" Vector__XXX
   SG_ TireTemp_33 m51 : 16|16@1+ (0.03125,-273) [-273|1735] "deg C" Vector__XXX
   SG_ TireTemp_32 m50 : 16|16@1+ (0.03125,-273) [-273|1735] "deg C" Vector__XXX
   SG_ TireTemp_31 m49 : 16|16@1+ (0.03125,-273) [-273|1735] "deg C" Vector__XXX
   SG_ TireTemp_30 m48 : 16|16@1+ (0.03125,-273) [-273|1735] "deg C" Vector__XXX
   SG_ TireTemp_23 m35 : 16|16@1+ (0.03125,-273) [-273|1735] "deg C" Vector__XXX
   SG_ TireTemp_22 m34 : 16|16@1+ (0.03125,-273) [-273|1735] "deg C" Vector__XXX
   SG_ TireTemp_21 m33 : 16|16@1+ (0.03125,-273) [-273|1735] "deg C" Vector__XXX
   SG_ TireTemp_20 m32 : 16|16@1+ (0.03125,-273) [-273|1735] "deg C" Vector__XXX
   SG_ TireTemp_13 m19 : 16|16@1+ (0.03125,-273) [-273|1735] "deg C" Vector__XXX
   SG_ TireTemp_12 m18 : 16|16@1+ (0.03125,-273) [-273|1735] "deg C" Vector__XXX
   SG_ TireTemp_10 m16 : 16|16@1+ (0.03125,-273) [-273|1735] "deg C" Vector__XXX
   SG_ TireTemp_01 m1 : 16|16@1+ (0.03125,-273) [-273|1735] "deg C" Vector__XXX
   SG_ TireTemp_00 m0 : 16|16@1+ (0.03125,-273) [-273|1735] "deg C" Vector__XXX
   SG_ TirePressThresholdDetection_33 m51 : 61|3@1+ (1,0) [0|7] "" Vector__XXX
   SG_ TirePressThresholdDetection_32 m50 : 61|3@1+ (1,0) [0|7] "" Vector__XXX
   SG_ TirePressThresholdDetection_31 m49 : 61|3@1+ (1,0) [0|7] "" Vector__XXX
   SG_ TirePressThresholdDetection_30 m48 : 61|3@1+ (1,0) [0|7] "" Vector__XXX
   SG_ TirePressThresholdDetection_23 m35 : 61|3@1+ (1,0) [0|7] "" Vector__XXX
   SG_ TirePressThresholdDetection_22 m34 : 61|3@1+ (1,0) [0|7] "" Vector__XXX
   SG_ TirePressThresholdDetection_21 m33 : 61|3@1+ (1,0) [0|7] "" Vector__XXX
   SG_ TirePressThresholdDetection_20 m32 : 61|3@1+ (1,0) [0|7] "" Vector__XXX
   SG_ TirePressThresholdDetection_00 m0 : 61|3@1+ (1,0) [0|7] "" Vector__XXX
   SG_ TirePress_01 m1 : 8|8@1+ (4,0) [0|1000] "kPa" Vector__XXX
   SG_ TirePress_00 m0 : 8|8@1+ (4,0) [0|1000] "kPa" Vector__XXX
   SG_ CTIWheelSensorStatus_00 m0 : 32|2@1+ (1,0) [0|3] "" Vector__XXX
   SG_ CTIWheelEndElectricalFault_00 m0 : 36|2@1+ (1,0) [0|3] "" Vector__XXX
   SG_ CTITireStatus_00 m0 : 34|2@1+ (1,0) [0|3] "" Vector__XXX
   SG_ TireLocation M : 0|8@1+ (1,0) [0|255] "" Vector__XXX

BO_ 2633939966 TFI: 16 Vector__XXX
   SG_ TripFanOnTimeDueToAManualSwitch : 64|32@1+ (0.05,0) [0|2.10554e+08] "hr" Vector__XXX
   SG_ TripFanOnTime : 0|32@1+ (0.05,0) [0|2.10554e+08] "hr" Vector__XXX
   SG_ TripFanOnTimeDueToA_CSystem : 96|32@1+ (0.05,0) [0|2.10554e+08] "hr" Vector__XXX
   SG_ TripFanOnTimeDueToEngSystem : 32|32@1+ (0.05,0) [0|2.10554e+08] "hr" Vector__XXX

BO_ 2633939710 TDI: 12 Vector__XXX
   SG_ TripDistanceInTopGear : 64|32@1+ (0.125,0) [0|5.26385e+08] "km" Vector__XXX
   SG_ TripGearDownDistance : 32|32@1+ (0.125,0) [0|5.26385e+08] "km" Vector__XXX
   SG_ TripDistanceOnVSL : 0|32@1+ (0.125,0) [0|5.26385e+08] "km" Vector__XXX

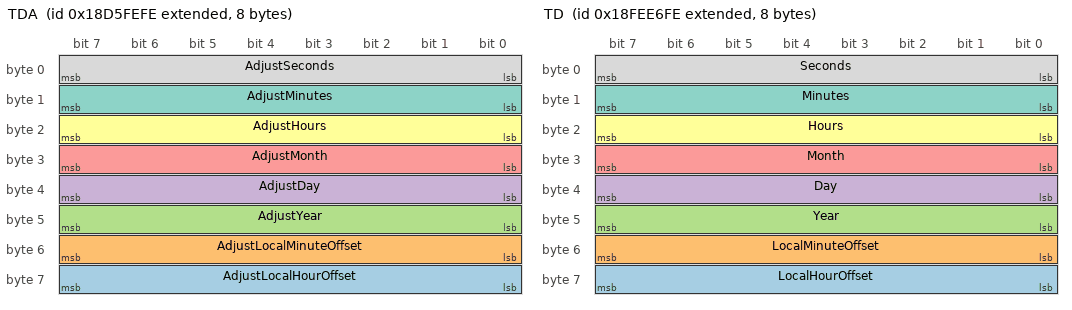
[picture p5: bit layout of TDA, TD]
BO_ 2564161278 TDA: 8 Vector__XXX
   SG_ AdjustLocalHourOffset : 56|8@1+ (1,-125) [-125|125] "hr" Vector__XXX
   SG_ AdjustLocalMinuteOffset : 48|8@1+ (1,-125) [-125|125] "mins" Vector__XXX
   SG_ AdjustYear : 40|8@1+ (1,1985) [1985|2235] "years" Vector__XXX
   SG_ AdjustDay : 32|8@1+ (0.25,0) [0|62.5] "days" Vector__XXX
   SG_ AdjustMonth : 24|8@1+ (1,0) [0|250] "months" Vector__XXX
   SG_ AdjustHours : 16|8@1+ (1,0) [0|250] "hr" Vector__XXX
   SG_ AdjustMinutes : 8|8@1+ (1,0) [0|250] "mins" Vector__XXX
   SG_ AdjustSeconds : 0|8@1+ (0.25,0) [0|62.5] "s" Vector__XXX

BO_ 2566842110 TD: 8 Vector__XXX
   SG_ LocalHourOffset : 56|8@1+ (1,-125) [-125|125] "hr" Vector__XXX
   SG_ LocalMinuteOffset : 48|8@1+ (1,-125) [-125|125] "mins" Vector__XXX
   SG_ Year : 40|8@1+ (1,1985) [1985|2235] "years" Vector__XXX
   SG_ Day : 32|8@1+ (0.25,0) [0|62.5] "days" Vector__XXX
   SG_ Month : 24|8@1+ (1,0) [0|250] "months" Vector__XXX
   SG_ Hours : 16|8@1+ (1,0) [0|250] "hr" Vector__XXX
   SG_ Minutes : 8|8@1+ (1,0) [0|250] "mins" Vector__XXX
   SG_ Seconds : 0|8@1+ (0.25,0) [0|62.5] "s" Vector__XXX

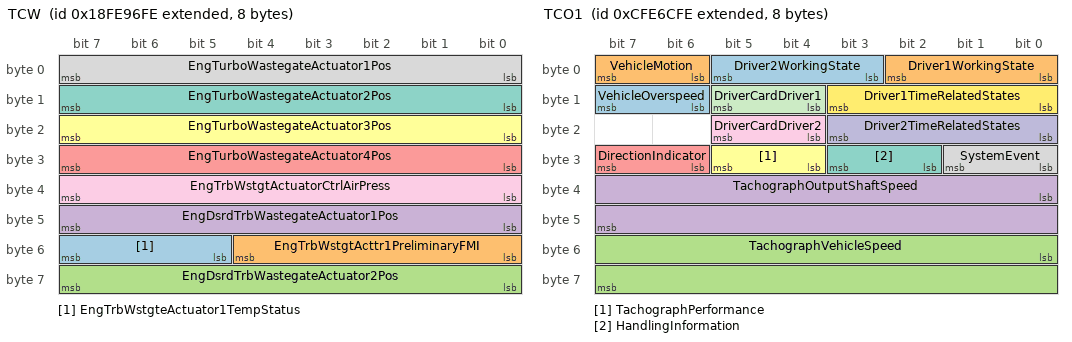
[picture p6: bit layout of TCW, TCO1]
BO_ 2566821630 TCW: 8 Vector__XXX
   SG_ EngTrbWstgteActuator1TempStatus : 53|3@1+ (1,0) [0|7] "" Vector__XXX
   SG_ EngTrbWstgtActtr1PreliminaryFMI : 48|5@1+ (1,0) [0|31] "" Vector__XXX
   SG_ EngDsrdTrbWastegateActuator2Pos : 56|8@1+ (0.4,0) [0|100] "%" Vector__XXX
   SG_ EngDsrdTrbWastegateActuator1Pos : 40|8@1+ (0.4,0) [0|100] "%" Vector__XXX
   SG_ EngTurboWastegateActuator4Pos : 24|8@1+ (0.4,0) [0|100] "%" Vector__XXX
   SG_ EngTurboWastegateActuator3Pos : 16|8@1+ (0.4,0) [0|100] "%" Vector__XXX
   SG_ EngTurboWastegateActuator2Pos : 8|8@1+ (0.4,0) [0|100] "%" Vector__XXX
   SG_ EngTurboWastegateActuator1Pos : 0|8@1+ (0.4,0) [0|100] "%" Vector__XXX
   SG_ EngTrbWstgtActuatorCtrlAirPress : 32|8@1+ (4,0) [0|1000] "kPa" Vector__XXX

BO_ 2365484286 TCO1: 8 Vector__XXX
   SG_ VehicleOverspeed : 14|2@1+ (1,0) [0|3] "" Vector__XXX
   SG_ VehicleMotion : 6|2@1+ (1,0) [0|3] "" Vector__XXX
   SG_ TachographVehicleSpeed : 48|16@1+ (0.00390625,0) [0|250.996] "km/h" Vector__XXX
   SG_ TachographOutputShaftSpeed : 32|16@1+ (0.125,0) [0|8031.88] "rpm" Vector__XXX
   SG_ DirectionIndicator : 30|2@1+ (1,0) [0|3] "" Vector__XXX
   SG_ TachographPerformance : 28|2@1+ (1,0) [0|3] "" Vector__XXX
   SG_ HandlingInformation : 26|2@1+ (1,0) [0|3] "" Vector__XXX
   SG_ SystemEvent : 24|2@1+ (1,0) [0|3] "" Vector__XXX
   SG_ DriverCardDriver2 : 20|2@1+ (1,0) [0|3] "" Vector__XXX
   SG_ Driver2TimeRelatedStates : 16|4@1+ (1,0) [0|15] "" Vector__XXX
   SG_ DriverCardDriver1 : 12|2@1+ (1,0) [0|3] "" Vector__XXX
   SG_ Driver1TimeRelatedStates : 8|4@1+ (1,0) [0|15] "" Vector__XXX
   SG_ Driver2WorkingState : 3|3@1+ (1,0) [0|7] "" Vector__XXX
   SG_ Driver1WorkingState : 0|3@1+ (1,0) [0|7] "" Vector__XXX

BO_ 2566771710 TCI6: 8 Vector__XXX
   SG_ EngTurbo4CompressorOutletTemp : 48|16@1+ (0.03125,-273) [-273|1734.97] "deg C" Vector__XXX
   SG_ EngTurbo3CompressorOutletTemp : 32|16@1+ (0.03125,-273) [-273|1734.97] "deg C" Vector__XXX
   SG_ EngTurbo2CompressorOutletTemp : 16|16@1+ (0.03125,-273) [-273|1734.97] "deg C" Vector__XXX
   SG_ EngTurbo1CompressorOutletTemp : 0|16@1+ (0.03125,-273) [-273|1734.97] "deg C" Vector__XXX

BO_ 2566821886 TCI5: 8 Vector__XXX
   SG_ EngTurbo4TurbineOutletTemp : 48|16@1+ (0.03125,-273) [-273|1734.97] "deg C" Vector__XXX
   SG_ EngTurbo3TurbineOutletTemp : 32|16@1+ (0.03125,-273) [-273|1734.97] "deg C" Vector__XXX
   SG_ EngTurbo2TurbineOutletTemp : 16|16@1+ (0.03125,-273) [-273|1734.97] "deg C" Vector__XXX
   SG_ EngTurbo1TurbineOutletTemp : 0|16@1+ (0.03125,-273) [-273|1734.97] "deg C" Vector__XXX

BO_ 2566822142 TCI4: 8 Vector__XXX
   SG_ EngTurbo4TurbineIntakeTemp : 48|16@1+ (0.03125,-273) [-273|1734.97] "deg C" Vector__XXX
   SG_ EngTurbo3TurbineIntakeTemp : 32|16@1+ (0.03125,-273) [-273|1734.97] "deg C" Vector__XXX
   SG_ EngTurbo2TurbineIntakeTemp : 16|16@1+ (0.03125,-273) [-273|1734.97] "deg C" Vector__XXX
   SG_ EngTurbo1TurbineIntakeTemp : 0|16@1+ (0.03125,-273) [-273|1734.97] "deg C" Vector__XXX

BO_ 2566822398 TCI3: 8 Vector__XXX
   SG_ EngTurbo4CompressorIntakePress : 48|16@1+ (0.0078125,-250) [-250|251.99] "kPa" Vector__XXX
   SG_ EngTurbo3CompressorIntakePress : 32|16@1+ (0.0078125,-250) [-250|251.99] "kPa" Vector__XXX
   SG_ EngTurbo2CompressorIntakePress : 16|16@1+ (0.0078125,-250) [-250|251.99] "kPa" Vector__XXX
   SG_ EngTurbo1CompressorIntakePress : 0|16@1+ (0.0078125,-250) [-250|251.99] "kPa" Vector__XXX

BO_ 2566822654 TCI2: 8 Vector__XXX
   SG_ EngTurbo4CompressorIntakeTemp : 48|16@1+ (0.03125,-273) [-273|1734.97] "deg C" Vector__XXX
   SG_ EngTurbo3CompressorIntakeTemp : 32|16@1+ (0.03125,-273) [-273|1734.97] "deg C" Vector__XXX
   SG_ EngTurbo2CompressorIntakeTemp : 16|16@1+ (0.03125,-273) [-273|1734.97] "deg C" Vector__XXX
   SG_ EngTurbo1CompressorIntakeTemp : 0|16@1+ (0.03125,-273) [-273|1734.97] "deg C" Vector__XXX

BO_ 2633931774 TCI1: 8 Vector__XXX
   SG_ EngTurbo4Speed : 40|16@1+ (4,0) [0|257020] "rpm" Vector__XXX
   SG_ EngTurbo3Speed : 24|16@1+ (4,0) [0|257020] "rpm" Vector__XXX
   SG_ EngTurbo2Speed : 8|16@1+ (4,0) [0|257020] "rpm" Vector__XXX
   SG_ EngTurboLubeOilPress2 : 0|8@1+ (4,0) [0|1000] "kPa" Vector__XXX

BO_ 2566802430 TCFG2: 8 Vector__XXX
   SG_ TransTorqueLimit : 0|16@1+ (1,0) [0|64255] "Nm" Vector__XXX

BO_ 2566841086 TCFG: 8 Vector__XXX
   SG_ TransGearRatio : 16|16@1+ (0.001,0) [0|64.255] "" Vector__XXX
   SG_ NumberOfForwardGearRatios : 8|8@1+ (1,0) [0|250] "" Vector__XXX
   SG_ NumberOfReverseGearRatios : 0|8@1+ (1,0) [0|250] "" Vector__XXX

BO_ 2348941054 TC1: 8 Vector__XXX
   SG_ TrnsShftSlctorDisplayModeSwitch : 54|2@1+ (1,0) [0|3] "" Vector__XXX
   SG_ TransMode4 : 46|2@1+ (1,0) [0|3] "" Vector__XXX
   SG_ TransMode3 : 44|2@1+ (1,0) [0|3] "" Vector__XXX
   SG_ TransMode2 : 42|2@1+ (1,0) [0|3] "" Vector__XXX
   SG_ TransMode1 : 40|2@1+ (1,0) [0|3] "" Vector__XXX
   SG_ DisengageDiffLockRqCentralRear : 36|2@1+ (1,0) [0|3] "" Vector__XXX
   SG_ DisengageDiffLockRqCentralFront : 34|2@1+ (1,0) [0|3] "" Vector__XXX
   SG_ DisengageDiffLockRqCentral : 32|2@1+ (1,0) [0|3] "" Vector__XXX
   SG_ DisengageDiffLockRqRearAxle2 : 30|2@1+ (1,0) [0|3] "" Vector__XXX
   SG_ DisengageDiffLockRqRearAxle1 : 28|2@1+ (1,0) [0|3] "" Vector__XXX
   SG_ DisengageDiffLockRqFrontAxle2 : 26|2@1+ (1,0) [0|3] "" Vector__XXX
   SG_ DisengageDiffLockRqFrontAxle1 : 24|2@1+ (1,0) [0|3] "" Vector__XXX
   SG_ TransRqedGear : 16|8@1+ (1,-125) [-125|125] "" Vector__XXX
   SG_ RqedPercentClutchSlip : 8|8@1+ (0.4,0) [0|100] "%" Vector__XXX
   SG_ DisengageDrivelineRq : 4|2@1+ (1,0) [0|3] "" Vector__XXX
   SG_ TransGearShiftInhibitRq : 0|2@1+ (1,0) [0|3] "" Vector__XXX
   SG_ TrnsTrqConverterLockupDisableRq : 2|2@1+ (1,0) [0|3] "" Vector__XXX
   SG_ TransRqedLaunchGear : 50|4@1+ (1,0) [0|15] "" Vector__XXX
   SG_ TransReverseGearShiftInhibitRq : 6|2@1+ (1,0) [0|3] "" Vector__XXX
   SG_ TransMode8 : 62|2@1+ (1,0) [0|3] "" Vector__XXX
   SG_ TransMode7 : 60|2@1+ (1,0) [0|3] "" Vector__XXX
   SG_ TransMode6 : 58|2@1+ (1,0) [0|3] "" Vector__XXX
   SG_ TransMode5 : 56|2@1+ (1,0) [0|3] "" Vector__XXX

BO_ 2566839806 TC: 8 Vector__XXX
   SG_ EngTurboOilLevelSwitch : 30|2@1+ (1,0) [0|3] "" Vector__XXX
   SG_ EngTurbo1Speed : 8|16@1+ (4,0) [0|257020] "rpm" Vector__XXX
   SG_ EngTurboLubeOilPress1 : 0|8@1+ (4,0) [0|1000] "kPa" Vector__XXX

BO_ 2633911806 TAVG: 8 Vector__XXX
   SG_ EngTotalAverageFuelEconomy : 16|16@1+ (0.00195313,0) [0|125.5] "km/L" Vector__XXX
   SG_ EngTotalAverageFuelRate : 0|16@1+ (0.05,0) [0|3212.75] "L/h" Vector__XXX

BO_ 2566775550 SPR: 8 Vector__XXX
   SG_ AirSuspensionSupplyPressRq : 40|8@1+ (8,0) [0|2000] "kPa" Vector__XXX
   SG_ AuxEquipmentSupplyPressRq : 32|8@1+ (8,0) [0|2000] "kPa" Vector__XXX
   SG_ ServiceBrakeAirPressRqCircuit2 : 24|8@1+ (8,0) [0|2000] "kPa" Vector__XXX
   SG_ ServiceBrakeAirPressRqCircuit1 : 16|8@1+ (8,0) [0|2000] "kPa" Vector__XXX
   SG_ ParkingAnd_OrTrailerAirPressRq : 8|8@1+ (8,0) [0|2000] "kPa" Vector__XXX
   SG_ PneumaticSupplyPressRq : 0|8@1+ (8,0) [0|2000] "kPa" Vector__XXX

BO_ 2566819838 SP2: 8 Vector__XXX
   SG_ EngExtlShutdownAirSupplyPress : 0|16@1+ (0.5,0) [0|32127.5] "kPa" Vector__XXX

BO_ 2566839038 SOFT: 8 Vector__XXX
   SG_ NmbrOfSftwrIdentificationFields : 0|8@1+ (1,0) [0|250] "steps" Vector__XXX
   SG_ SoftwareID3 : 24|8@1+ (1,0) [0|255] "" Vector__XXX
   SG_ SoftwareID2 : 16|8@1+ (1,0) [0|255] "" Vector__XXX
   SG_ SoftwareID1 : 8|8@1+ (1,0) [0|255] "" Vector__XXX

BO_ 2566841598 SHUTDN: 8 Vector__XXX
   SG_ EngOverspeedTest : 54|2@1+ (1,0) [0|3] "" Vector__XXX
   SG_ EngAirShutoffCmdStatus : 52|2@1+ (1,0) [0|3] "" Vector__XXX
   SG_ EngAlarmOutputCmdStatus : 50|2@1+ (1,0) [0|3] "" Vector__XXX
   SG_ EngAlarmAcknowledge : 48|2@1+ (1,0) [0|3] "" Vector__XXX
   SG_ EngProtectionSystemConfig : 46|2@1+ (1,0) [0|3] "" Vector__XXX
   SG_ EngProtectionSystemTimerState : 38|2@1+ (1,0) [0|3] "" Vector__XXX
   SG_ EngPrtectionSystemTimerOverride : 36|2@1+ (1,0) [0|3] "" Vector__XXX
   SG_ EngPrtctnSystmApprchingShutdown : 34|2@1+ (1,0) [0|3] "" Vector__XXX
   SG_ EngWaitToStartLamp : 24|2@1+ (1,0) [0|3] "" Vector__XXX
   SG_ RefrigerantHighPressSwitch : 20|2@1+ (1,0) [0|3] "" Vector__XXX
   SG_ RefrigerantLowPressSwitch : 18|2@1+ (1,0) [0|3] "" Vector__XXX
   SG_ A_CHighPressFanSwitch : 16|2@1+ (1,0) [0|3] "" Vector__XXX
   SG_ EngIdleShutdownTimerFunction : 14|2@1+ (1,0) [0|3] "" Vector__XXX
   SG_ EngIdleShutdownTimerState : 6|2@1+ (1,0) [0|3] "" Vector__XXX
   SG_ EngIdleShutdownTimerOverride : 4|2@1+ (1,0) [0|3] "" Vector__XXX
   SG_ EngIdleShutdownDriverAlertMode : 2|2@1+ (1,0) [0|3] "" Vector__XXX
   SG_ PTOShutdownHasShutdownEng : 58|2@1+ (1,0) [0|3] "" Vector__XXX
   SG_ EngPrtctnSystmHasShutdownEngine : 32|2@1+ (1,0) [0|3] "" Vector__XXX
   SG_ EngIdlShutdownHasShutdownEngine : 0|2@1+ (1,0) [0|3] "" Vector__XXX
   SG_ EngAirShutoffStatus : 56|2@1+ (1,0) [0|3] "" Vector__XXX

BO_ 2566832382 SERV: 8 Vector__XXX
   SG_ ServiceComponentIdentificationB : 24|8@1+ (1,0) [0|250] "ID" Vector__XXX
   SG_ ServiceComponentIdentificationA : 0|8@1+ (1,0) [0|250] "ID" Vector__XXX
   SG_ SrvceDelay_OperationalTimeBased : 48|16@1+ (1,-32127) [-32127|32128] "hr" Vector__XXX
   SG_ ServiceDelay_CalendarTimeBased : 32|8@1+ (1,-125) [-125|125] "weeks" Vector__XXX
   SG_ ServiceDistance : 8|16@1+ (5,-160635) [-160635|160640] "km" Vector__XXX
   SG_ ServiceComponentIdentification : 40|8@1+ (1,0) [0|250] "ID" Vector__XXX

BO_ 2633928446 S2: 8 Vector__XXX
   SG_ TimeSinceLastService : 8|16@1+ (1,-32127) [-32127|32128] "hr" Vector__XXX
   SG_ ServiceComponentIdentification : 0|8@1+ (1,0) [0|250] "ID" Vector__XXX

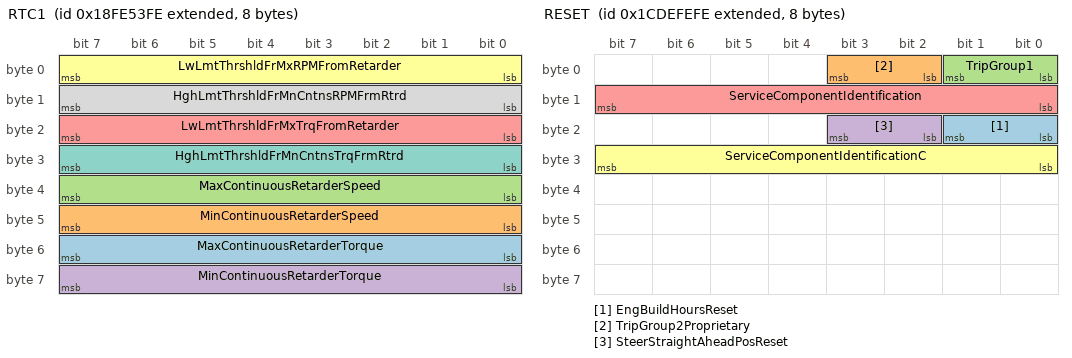
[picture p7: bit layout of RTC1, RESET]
BO_ 2566804478 RTC1: 8 Vector__XXX
   SG_ MaxContinuousRetarderTorque : 48|8@1+ (1,-125) [-125|125] "%" Vector__XXX
   SG_ MinContinuousRetarderSpeed : 40|8@1+ (32,0) [0|8000] "rpm" Vector__XXX
   SG_ MaxContinuousRetarderSpeed : 32|8@1+ (32,0) [0|8000] "rpm" Vector__XXX
   SG_ MinContinuousRetarderTorque : 56|8@1+ (1,-125) [-125|125] "%" Vector__XXX
   SG_ LwLmtThrshldFrMxTrqFromRetarder : 16|8@1+ (1,-125) [-125|125] "%" Vector__XXX
   SG_ LwLmtThrshldFrMxRPMFromRetarder : 0|8@1+ (32,0) [0|8000] "rpm" Vector__XXX
   SG_ HghLmtThrshldFrMnCntnsTrqFrmRtrd : 24|8@1+ (1,-125) [-125|125] "%" Vector__XXX
   SG_ HghLmtThrshldFrMnCntnsRPMFrmRtrd : 8|8@1+ (32,0) [0|8000] "rpm" Vector__XXX

BO_ 2566847486 RF: 8 Vector__XXX
   SG_ DrvlneRetarderOverheatIndicator : 16|2@1+ (1,0) [0|3] "" Vector__XXX
   SG_ HydRetarderOilTemp : 8|8@1+ (1,-40) [-40|210] "deg C" Vector__XXX
   SG_ HydRetarderPress : 0|8@1+ (16,0) [0|4000] "kPa" Vector__XXX

BO_ 2631859966 RESET: 8 Vector__XXX
   SG_ EngBuildHoursReset : 16|2@1+ (1,0) [0|3] "" Vector__XXX
   SG_ TripGroup2Proprietary : 2|2@1+ (1,0) [0|3] "" Vector__XXX
   SG_ TripGroup1 : 0|2@1+ (1,0) [0|3] "" Vector__XXX
   SG_ SteerStraightAheadPosReset : 18|2@1+ (1,0) [0|3] "" Vector__XXX
   SG_ ServiceComponentIdentification : 8|8@1+ (1,0) [0|250] "ID" Vector__XXX
   SG_ ServiceComponentIdentificationC : 24|8@1+ (1,0) [0|250] "ID" Vector__XXX

BO_ 2566840830 RC: 19 Vector__XXX
   SG_ PercentTorqueAtPeakTorquePoint5 : 144|8@1+ (1,-125) [-125|125] "%" Vector__XXX
   SG_ ReferenceRetarderTorque : 128|16@1+ (1,0) [0|64255] "Nm" Vector__XXX
   SG_ RetarderSpeedAtPeakTorquePoint5 : 112|16@1+ (0.125,0) [0|8031.88] "rpm" Vector__XXX
   SG_ PercentTorqueAtPoint4 : 104|8@1+ (1,-125) [-125|125] "%" Vector__XXX
   SG_ RetarderSpeedAtPoint4 : 88|16@1+ (0.125,0) [0|8031.88] "rpm" Vector__XXX
   SG_ PercentTorqueAtPoint3 : 80|8@1+ (1,-125) [-125|125] "%" Vector__XXX
   SG_ RetarderSpeedAtPoint3 : 64|16@1+ (0.125,0) [0|8031.88] "rpm" Vector__XXX
   SG_ PercentTorqueAtMaxSpeedPoint2 : 56|8@1+ (1,-125) [-125|125] "%" Vector__XXX
   SG_ MaxRetarderSpeedPoint2 : 40|16@1+ (0.125,0) [0|8031.88] "rpm" Vector__XXX
   SG_ PercentTorqueAtIdlePoint1 : 32|8@1+ (1,-125) [-125|125] "%" Vector__XXX
   SG_ RetarderSpeedAtIdlePoint1 : 16|16@1+ (0.125,0) [0|8031.88] "rpm" Vector__XXX
   SG_ RetarderCtrlMethod : 8|8@1+ (1,0) [0|250] "steps" Vector__XXX
   SG_ RetarderLocation : 4|4@1+ (1,0) [0|15] "" Vector__XXX
   SG_ RetarderType : 0|4@1+ (1,0) [0|15] "" Vector__XXX

BO_ 2633930238 RBI: 8 Vector__XXX
   SG_ EngOperationTimeSinceRebuild : 0|32@1+ (1,0) [0|4.21108e+09] "s" Vector__XXX

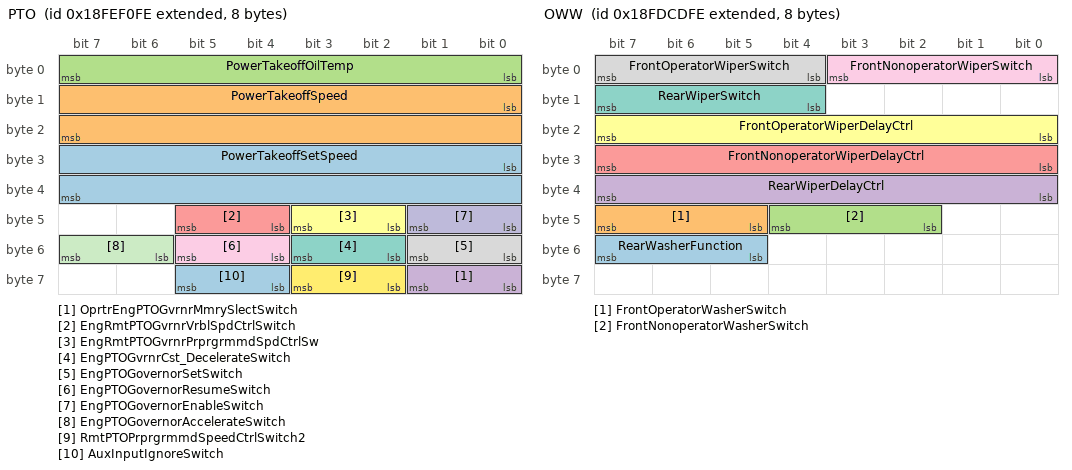
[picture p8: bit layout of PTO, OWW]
BO_ 2566844670 PTO: 8 Vector__XXX
   SG_ PowerTakeoffSetSpeed : 24|16@1+ (0.125,0) [0|8031.88] "rpm" Vector__XXX
   SG_ PowerTakeoffSpeed : 8|16@1+ (0.125,0) [0|8031.88] "rpm" Vector__XXX
   SG_ PowerTakeoffOilTemp : 0|8@1+ (1,-40) [-40|210] "deg C" Vector__XXX
   SG_ OprtrEngPTOGvrnrMmrySlectSwitch : 56|2@1+ (1,0) [0|3] "" Vector__XXX
   SG_ EngRmtPTOGvrnrVrblSpdCtrlSwitch : 44|2@1+ (1,0) [0|3] "" Vector__XXX
   SG_ EngRmtPTOGvrnrPrprgrmmdSpdCtrlSw : 42|2@1+ (1,0) [0|3] "" Vector__XXX
   SG_ EngPTOGvrnrCst_DecelerateSwitch : 50|2@1+ (1,0) [0|3] "" Vector__XXX
   SG_ EngPTOGovernorSetSwitch : 48|2@1+ (1,0) [0|3] "" Vector__XXX
   SG_ EngPTOGovernorResumeSwitch : 52|2@1+ (1,0) [0|3] "" Vector__XXX
   SG_ EngPTOGovernorEnableSwitch : 40|2@1+ (1,0) [0|3] "" Vector__XXX
   SG_ EngPTOGovernorAccelerateSwitch : 54|2@1+ (1,0) [0|3] "" Vector__XXX
   SG_ RmtPTOPrprgrmmdSpeedCtrlSwitch2 : 58|2@1+ (1,0) [0|3] "" Vector__XXX
   SG_ AuxInputIgnoreSwitch : 60|2@1+ (1,0) [0|3] "" Vector__XXX

BO_ 2566770174 OWW: 8 Vector__XXX
   SG_ RearWasherFunction : 53|3@1+ (1,0) [0|7] "" Vector__XXX
   SG_ FrontOperatorWasherSwitch : 45|3@1+ (1,0) [0|7] "" Vector__XXX
   SG_ FrontNonoperatorWasherSwitch : 42|3@1+ (1,0) [0|7] "" Vector__XXX
   SG_ RearWiperDelayCtrl : 32|8@1+ (0.4,0) [0|100] "%" Vector__XXX
   SG_ FrontNonoperatorWiperDelayCtrl : 24|8@1+ (0.4,0) [0|100] "%" Vector__XXX
   SG_ FrontOperatorWiperDelayCtrl : 16|8@1+ (0.4,0) [0|100] "%" Vector__XXX
   SG_ RearWiperSwitch : 12|4@1+ (1,0) [0|15] "" Vector__XXX
   SG_ FrontOperatorWiperSwitch : 4|4@1+ (1,0) [0|15] "" Vector__XXX
   SG_ FrontNonoperatorWiperSwitch : 0|4@1+ (1,0) [0|15] "" Vector__XXX

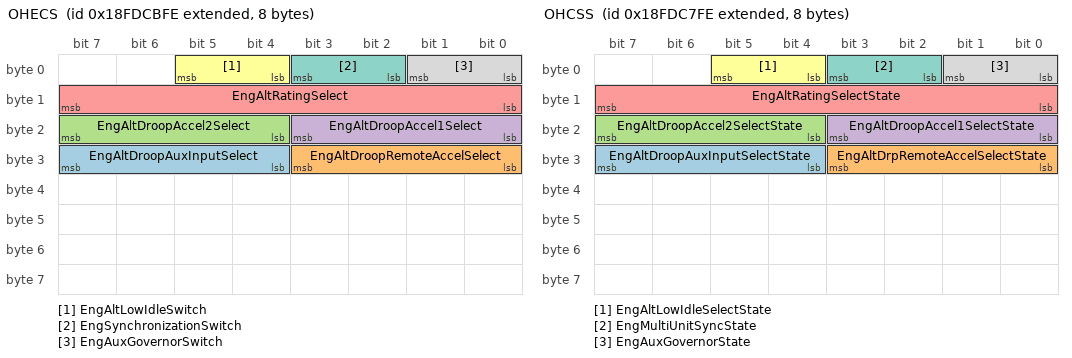
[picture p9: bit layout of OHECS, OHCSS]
BO_ 2566769662 OHECS: 8 Vector__XXX
   SG_ EngAltDroopAuxInputSelect : 28|4@1+ (1,0) [0|15] "" Vector__XXX
   SG_ EngAltDroopRemoteAccelSelect : 24|4@1+ (1,0) [0|15] "" Vector__XXX
   SG_ EngAltDroopAccel2Select : 20|4@1+ (1,0) [0|15] "" Vector__XXX
   SG_ EngAltDroopAccel1Select : 16|4@1+ (1,0) [0|15] "" Vector__XXX
   SG_ EngAltRatingSelect : 8|8@1+ (1,0) [0|255] "" Vector__XXX
   SG_ EngAltLowIdleSwitch : 4|2@1+ (1,0) [0|3] "" Vector__XXX
   SG_ EngSynchronizationSwitch : 2|2@1+ (1,0) [0|3] "" Vector__XXX
   SG_ EngAuxGovernorSwitch : 0|2@1+ (1,0) [0|3] "" Vector__XXX

BO_ 2566768638 OHCSS: 8 Vector__XXX
   SG_ EngAltDroopAuxInputSelectState : 28|4@1+ (1,0) [0|15] "" Vector__XXX
   SG_ EngAltDrpRemoteAccelSelectState : 24|4@1+ (1,0) [0|15] "" Vector__XXX
   SG_ EngAltDroopAccel2SelectState : 20|4@1+ (1,0) [0|15] "" Vector__XXX
   SG_ EngAltDroopAccel1SelectState : 16|4@1+ (1,0) [0|15] "" Vector__XXX
   SG_ EngAltRatingSelectState : 8|8@1+ (1,0) [0|255] "" Vector__XXX
   SG_ EngAltLowIdleSelectState : 4|2@1+ (1,0) [0|3] "" Vector__XXX
   SG_ EngMultiUnitSyncState : 2|2@1+ (1,0) [0|3] "" Vector__XXX
   SG_ EngAuxGovernorState : 0|2@1+ (1,0) [0|3] "" Vector__XXX

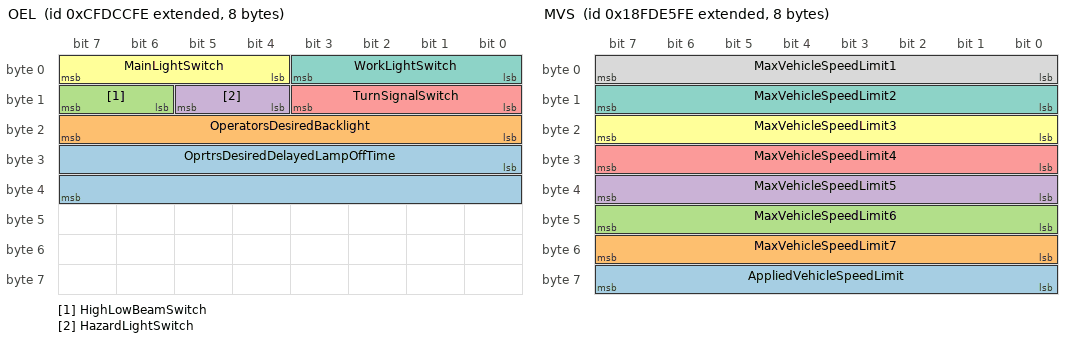
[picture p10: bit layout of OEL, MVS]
BO_ 2365443326 OEL: 8 Vector__XXX
   SG_ OprtrsDesiredDelayedLampOffTime : 24|16@1+ (1,0) [0|64255] "s" Vector__XXX
   SG_ OperatorsDesiredBacklight : 16|8@1+ (0.4,0) [0|100] "%" Vector__XXX
   SG_ HighLowBeamSwitch : 14|2@1+ (1,0) [0|3] "" Vector__XXX
   SG_ HazardLightSwitch : 12|2@1+ (1,0) [0|3] "" Vector__XXX
   SG_ TurnSignalSwitch : 8|4@1+ (1,0) [0|15] "" Vector__XXX
   SG_ MainLightSwitch : 4|4@1+ (1,0) [0|15] "" Vector__XXX
   SG_ WorkLightSwitch : 0|4@1+ (1,0) [0|15] "" Vector__XXX

BO_ 2566776318 MVS: 8 Vector__XXX
   SG_ AppliedVehicleSpeedLimit : 56|8@1+ (1,0) [0|250] "km/h" Vector__XXX
   SG_ MaxVehicleSpeedLimit7 : 48|8@1+ (1,0) [0|250] "km/h" Vector__XXX
   SG_ MaxVehicleSpeedLimit6 : 40|8@1+ (1,0) [0|250] "km/h" Vector__XXX
   SG_ MaxVehicleSpeedLimit5 : 32|8@1+ (1,0) [0|250] "km/h" Vector__XXX
   SG_ MaxVehicleSpeedLimit4 : 24|8@1+ (1,0) [0|250] "km/h" Vector__XXX
   SG_ MaxVehicleSpeedLimit3 : 16|8@1+ (1,0) [0|250] "km/h" Vector__XXX
   SG_ MaxVehicleSpeedLimit2 : 8|8@1+ (1,0) [0|250] "km/h" Vector__XXX
   SG_ MaxVehicleSpeedLimit1 : 0|8@1+ (1,0) [0|250] "km/h" Vector__XXX

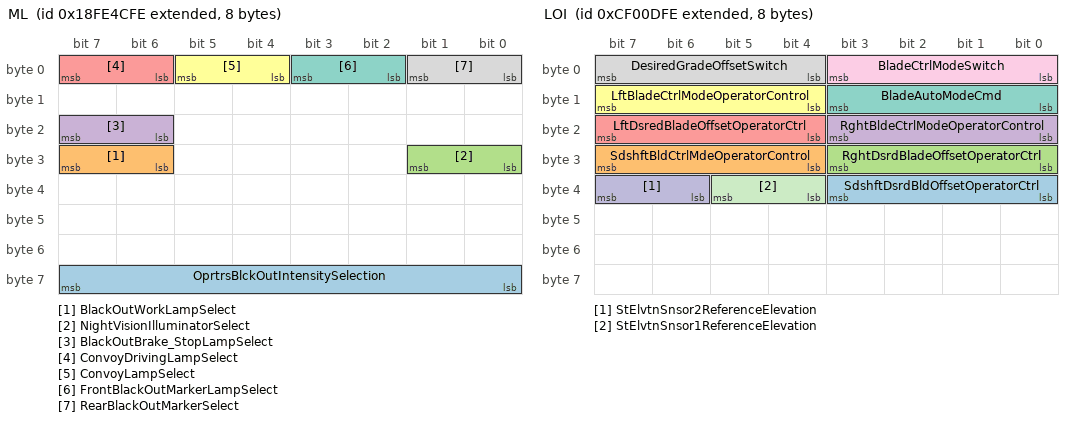
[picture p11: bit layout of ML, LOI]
BO_ 2566802686 ML: 8 Vector__XXX
   SG_ OprtrsBlckOutIntensitySelection : 56|8@1+ (0.4,0) [0|100] "%" Vector__XXX
   SG_ BlackOutWorkLampSelect : 30|2@1+ (1,0) [0|3] "" Vector__XXX
   SG_ NightVisionIlluminatorSelect : 24|2@1+ (1,0) [0|3] "" Vector__XXX
   SG_ BlackOutBrake_StopLampSelect : 22|2@1+ (1,0) [0|3] "" Vector__XXX
   SG_ ConvoyDrivingLampSelect : 6|2@1+ (1,0) [0|3] "" Vector__XXX
   SG_ ConvoyLampSelect : 4|2@1+ (1,0) [0|3] "" Vector__XXX
   SG_ FrontBlackOutMarkerLampSelect : 2|2@1+ (1,0) [0|3] "" Vector__XXX
   SG_ RearBlackOutMarkerSelect : 0|2@1+ (1,0) [0|3] "" Vector__XXX

BO_ 2566774014 MCI: 8 Vector__XXX
   SG_ SlowVesselModeStatus : 6|2@1+ (1,0) [0|3] "" Vector__XXX
   SG_ TrollingModeStatus : 4|2@1+ (1,0) [0|3] "" Vector__XXX
   SG_ EngThrttlSynchrnztionModeStatus : 0|4@1+ (1,0) [0|15] "" Vector__XXX

BO_ 2566823166 MBT3: 8 Vector__XXX
   SG_ EngMainBearing11Temp : 32|16@1+ (0.03125,-273) [-273|1734.97] "deg C" Vector__XXX
   SG_ EngMainBearing10Temp : 16|16@1+ (0.03125,-273) [-273|1734.97] "deg C" Vector__XXX
   SG_ EngMainBearing9Temp : 0|16@1+ (0.03125,-273) [-273|1734.97] "deg C" Vector__XXX

BO_ 2566823422 MBT2: 8 Vector__XXX
   SG_ EngMainBearing8Temp : 48|16@1+ (0.03125,-273) [-273|1734.97] "deg C" Vector__XXX
   SG_ EngMainBearing7Temp : 32|16@1+ (0.03125,-273) [-273|1734.97] "deg C" Vector__XXX
   SG_ EngMainBearing6Temp : 16|16@1+ (0.03125,-273) [-273|1734.97] "deg C" Vector__XXX
   SG_ EngMainBearing5Temp : 0|16@1+ (0.03125,-273) [-273|1734.97] "deg C" Vector__XXX

BO_ 2566823678 MBT1: 8 Vector__XXX
   SG_ EngMainBearing4Temp : 48|16@1+ (0.03125,-273) [-273|1734.97] "deg C" Vector__XXX
   SG_ EngMainBearing3Temp : 32|16@1+ (0.03125,-273) [-273|1734.97] "deg C" Vector__XXX
   SG_ EngMainBearing2Temp : 16|16@1+ (0.03125,-273) [-273|1734.97] "deg C" Vector__XXX
   SG_ EngMainBearing1Temp : 0|16@1+ (0.03125,-273) [-273|1734.97] "deg C" Vector__XXX

BO_ 2432595710 LVDD: 8 Vector__XXX
   SG_ DisplayDeadbands : 20|4@1+ (1,0) [0|15] "" Vector__XXX
   SG_ LEDPatternCtrl : 16|4@1+ (1,0) [0|15] "" Vector__XXX
   SG_ LEDDisplayDeadbandCtrl : 12|4@1+ (1,0) [0|15] "" Vector__XXX
   SG_ LEDDisplayModeCtrl : 8|4@1+ (1,0) [0|15] "" Vector__XXX
   SG_ LEDDisplayData1 : 0|8@1+ (1,0) [0|255] "" Vector__XXX

BO_ 2365486590 LVD: 8 Vector__XXX
   SG_ LaserStrikeDataLatency : 24|16@1+ (51.2,0) [0|3.28986] "s" Vector__XXX
   SG_ LaserReceiverType : 16|8@1+ (1,0) [0|250] "" Vector__XXX
   SG_ LaserStrikeVerticalDeviation : 0|16@1+ (0.1,-3200) [-3200|3225.5] "mm" Vector__XXX
   SG_ AbsLaserStrikePos : 40|16@1+ (0.1,0) [0|6425.5] "mm" Vector__XXX

BO_ 2365485566 LTP: 8 Vector__XXX
   SG_ LaserTracerInformation : 48|8@1+ (1,0) [0|255] "" Vector__XXX
   SG_ LEDDisplayData2 : 40|8@1+ (1,0) [0|255] "" Vector__XXX
   SG_ LaserTracerHorizontalDeviation : 32|8@1+ (1,0) [0|250] "%" Vector__XXX
   SG_ LaserTracerVerticalDistance : 16|16@1+ (0.1,0) [0|6425.5] "mm" Vector__XXX
   SG_ LaserTracerTargetDeviation : 0|16@1+ (0.1,-3200) [-3200|3225.5] "mm" Vector__XXX

BO_ 2633939454 LTFI: 22 Vector__XXX
   SG_ TripCruiseFuelUsed : 128|32@1+ (0.5,0) [0|2.10554e+09] "L" Vector__XXX
   SG_ TripVehicleIdleFuelUsed : 96|32@1+ (0.5,0) [0|2.10554e+09] "L" Vector__XXX
   SG_ TripDriveFuelUsed : 0|32@1+ (0.5,0) [0|2.10554e+09] "L" Vector__XXX
   SG_ TrpPTOGovernorNonmovingFuelUsed : 64|32@1+ (0.5,0) [0|2.10554e+09] "L" Vector__XXX
   SG_ TripPTOGovernorMovingFuelUsed : 32|32@1+ (0.5,0) [0|2.10554e+09] "L" Vector__XXX
   SG_ TripDriveFuelEconomy : 160|16@1+ (0.00195313,0) [0|125.5] "km/L" Vector__XXX

BO_ 2365486334 LSP: 8 Vector__XXX
   SG_ BldHeightSetPointHighResolution : 16|32@1+ (100,-209.715) [-209.715|211.393] "m" Vector__XXX
   SG_ ModifyLevelingSystemSetPoint : 0|16@1+ (0.1,-3200) [-3200|3225.5] "mm" Vector__XXX

BO_ 2364542462 LOI: 8 Vector__XXX
   SG_ SdshftDsrdBldOffsetOperatorCtrl : 32|4@1+ (1,0) [0|15] "" Vector__XXX
   SG_ SdshftBldCtrlMdeOperatorControl : 28|4@1+ (1,0) [0|15] "" Vector__XXX
   SG_ RghtDsrdBladeOffsetOperatorCtrl : 24|4@1+ (1,0) [0|15] "" Vector__XXX
   SG_ RghtBldeCtrlModeOperatorControl : 16|4@1+ (1,0) [0|15] "" Vector__XXX
   SG_ LftDsredBladeOffsetOperatorCtrl : 20|4@1+ (1,0) [0|15] "" Vector__XXX
   SG_ LftBladeCtrlModeOperatorControl : 12|4@1+ (1,0) [0|15] "" Vector__XXX
   SG_ BladeAutoModeCmd : 8|4@1+ (1,0) [0|15] "" Vector__XXX
   SG_ DesiredGradeOffsetSwitch : 4|4@1+ (1,0) [0|15] "" Vector__XXX
   SG_ BladeCtrlModeSwitch : 0|4@1+ (1,0) [0|15] "" Vector__XXX
   SG_ StElvtnSnsor2ReferenceElevation : 38|2@1+ (1,0) [0|3] "" Vector__XXX
   SG_ StElvtnSnsor1ReferenceElevation : 36|2@1+ (1,0) [0|3] "" Vector__XXX

BO_ 2365486078 LMP: 8 Vector__XXX
   SG_ MastPos : 0|16@1+ (0.1,-3200) [-3200|3225.5] "mm" Vector__XXX

BO_ 2633937918 LFI: 8 Vector__XXX
   SG_ TotalEngPTOGovernorFuelUsed : 0|32@1+ (0.5,0) [0|2.10554e+09] "L" Vector__XXX
   SG_ TripAverageFuelRate : 32|16@1+ (0.05,0) [0|3212.75] "L/h" Vector__XXX
   SG_ FlexibleFuelPercentage : 48|10@1+ (0.1,0) [0|102] "%" Vector__XXX

BO_ 2566845182 LFE: 8 Vector__XXX
   SG_ EngAverageFuelEconomy : 32|16@1+ (0.00195313,0) [0|125.5] "km/L" Vector__XXX
   SG_ EngInstantaneousFuelEconomy : 16|16@1+ (0.00195313,0) [0|125.5] "km/L" Vector__XXX
   SG_ EngFuelRate : 0|16@1+ (0.05,0) [0|3212.75] "L/h" Vector__XXX
   SG_ EngThrottleValve2Pos : 56|8@1+ (0.4,0) [0|100] "%" Vector__XXX
   SG_ EngThrottleValve1Pos : 48|8@1+ (0.4,0) [0|100] "%" Vector__XXX

BO_ 2566842878 LFC: 8 Vector__XXX
   SG_ EngTotalFuelUsed : 32|32@1+ (0.5,0) [0|2.10554e+09] "L" Vector__XXX
   SG_ EngTripFuel : 0|32@1+ (0.5,0) [0|2.10554e+09] "L" Vector__XXX

BO_ 2633883646 FWD: 8 Vector__XXX
   SG_ FrontWheelDriveActuatorStatus : 0|2@1+ (1,0) [0|3] "" Vector__XXX

BO_ 2633880062 FMS: 8 Vector__XXX
   SG_ FMSstandardSWversionSupported : 8|32@1+ (1,0) [0|255] "per" Vector__XXX
   SG_ FMSstandardRqsSupported : 2|2@1+ (1,0) [0|3] "" Vector__XXX
   SG_ FMSstandardDiagnosticsSupported : 0|2@1+ (1,0) [0|3] "" Vector__XXX

BO_ 2566806526 FLI2: 8 Vector__XXX
   SG_ LnDprtureIndicationEnableStatus : 6|2@1+ (1,0) [0|3] "" Vector__XXX
   SG_ LaneTrackingStatusLeftSide : 4|2@1+ (1,0) [0|3] "" Vector__XXX
   SG_ LaneTrackingStatusRightSide : 2|2@1+ (1,0) [0|3] "" Vector__XXX

BO_ 2431649790 FLI1: 8 Vector__XXX
   SG_ LaneDepartureImminentLeftSide : 6|2@1+ (1,0) [0|3] "" Vector__XXX
   SG_ LaneDepartureImminentRightSide : 4|2@1+ (1,0) [0|3] "" Vector__XXX
   SG_ LaneDepartureRight : 2|2@1+ (1,0) [0|3] "" Vector__XXX
   SG_ LaneDepartureLeft : 0|2@1+ (1,0) [0|3] "" Vector__XXX

BO_ 2633929214 FL: 8 Vector__XXX
   SG_ EngFuelLeakage2 : 2|2@1+ (1,0) [0|3] "" Vector__XXX
   SG_ EngFuelLeakage1 : 0|2@1+ (1,0) [0|3] "" Vector__XXX

BO_ 2566831614 FD: 8 Vector__XXX
   SG_ FanSpeed : 16|16@1+ (0.125,0) [0|8031.88] "rpm" Vector__XXX
   SG_ FanDriveState : 8|4@1+ (1,0) [0|15] "" Vector__XXX
   SG_ EstPercentFanSpeed : 0|8@1+ (0.4,0) [0|100] "%" Vector__XXX
   SG_ HydFanMotorPress : 32|16@1+ (0.5,0) [0|32127.5] "kPa" Vector__XXX
   SG_ FanDriveBypassCmdStatus : 48|8@1+ (0.4,0) [0|100] "%" Vector__XXX

BO_ 2566820094 ETH: 33 Vector__XXX
   SG_ EngTorqueLimit6AxleInput : 248|16@1+ (2,0) [0|128510] "Nm" Vector__XXX
   SG_ EngTorqueLimit5Switch : 232|16@1+ (1,0) [0|64255] "Nm" Vector__XXX
   SG_ EngTorqueLimit4Trans : 216|16@1+ (1,0) [0|64255] "Nm" Vector__XXX
   SG_ EngTorqueLimit3Trans : 200|16@1+ (1,0) [0|64255] "Nm" Vector__XXX
   SG_ TransGearRatio3 : 184|16@1+ (0.01,0) [0|642.55] "" Vector__XXX
   SG_ EngTorqueLimit2Trans : 168|16@1+ (1,0) [0|64255] "Nm" Vector__XXX
   SG_ TransGearRatio2 : 152|16@1+ (0.01,0) [0|642.55] "" Vector__XXX
   SG_ EngTorqueLimit1Trans : 136|16@1+ (1,0) [0|64255] "Nm" Vector__XXX
   SG_ TransGearRatio1 : 120|16@1+ (0.01,0) [0|642.55] "" Vector__XXX
   SG_ EngTorqueLimitFeature : 114|3@1+ (1,0) [0|7] "" Vector__XXX
   SG_ TorqueLimitingFeatureStatus : 112|2@1+ (1,0) [0|3] "" Vector__XXX
   SG_ CalibRecordDurationTime : 80|32@1+ (0.05,0) [0|2.10554e+08] "hr" Vector__XXX
   SG_ CalibRecordStartYear : 72|8@1+ (1,1985) [1985|2235] "years" Vector__XXX
   SG_ CalibRecordStartDay : 64|8@1+ (0.25,0) [0|62.5] "days" Vector__XXX
   SG_ CalibRecordStartMonth : 56|8@1+ (1,0) [0|250] "months" Vector__XXX
   SG_ EngPeakTorque2 : 40|16@1+ (1,0) [0|64255] "Nm" Vector__XXX
   SG_ EngPeakTorque1 : 24|16@1+ (1,0) [0|64255] "Nm" Vector__XXX
   SG_ EngPower : 8|16@1+ (0.5,0) [0|32127.5] "kW" Vector__XXX
   SG_ NumberOfEngTorqueHistoryRecords : 0|8@1+ (1,0) [0|250] "records" Vector__XXX

BO_ 2364542206 ETC8: 8 Vector__XXX
   SG_ TransClutch_ConverterInputSpeed : 16|16@1+ (0.125,0) [0|8031.88] "rpm" Vector__XXX
   SG_ TransTorqueConverterRatio : 0|16@1+ (0.001,0) [0|64.255] "" Vector__XXX

BO_ 2566802174 ETC7: 8 Vector__XXX
   SG_ TrnsRvrseGearShiftInhibitStatus : 40|2@1+ (1,0) [0|3] "" Vector__XXX
   SG_ TrnsCrrntRangeDisplayBlankState : 0|2@1+ (1,0) [0|3] "" Vector__XXX
   SG_ TransWarningIndicator : 42|2@1+ (1,0) [0|3] "" Vector__XXX
   SG_ TransMode8Indicator : 38|2@1+ (1,0) [0|3] "" Vector__XXX
   SG_ TransMode7Indicator : 36|2@1+ (1,0) [0|3] "" Vector__XXX
   SG_ TransMode6Indicator : 34|2@1+ (1,0) [0|3] "" Vector__XXX
   SG_ TransMode5Indicator : 32|2@1+ (1,0) [0|3] "" Vector__XXX
   SG_ TransRqedGearFeedback : 24|8@1+ (1,-125) [-125|125] "" Vector__XXX
   SG_ TransMode1Indicator : 22|2@1+ (1,0) [0|3] "" Vector__XXX
   SG_ TransMode2Indicator : 20|2@1+ (1,0) [0|3] "" Vector__XXX
   SG_ TransMode3Indicator : 18|2@1+ (1,0) [0|3] "" Vector__XXX
   SG_ TransMode4Indicator : 16|2@1+ (1,0) [0|3] "" Vector__XXX
   SG_ TransShiftInhibitIndicator : 14|2@1+ (1,0) [0|3] "" Vector__XXX
   SG_ TransEngCrankEnable : 12|2@1+ (1,0) [0|3] "" Vector__XXX
   SG_ ActiveShiftConsoleIndicator : 10|2@1+ (1,0) [0|3] "" Vector__XXX
   SG_ TransReadyForBrakeRelease : 8|2@1+ (1,0) [0|3] "" Vector__XXX
   SG_ TransRqedRangeDisplayFlashState : 6|2@1+ (1,0) [0|3] "" Vector__XXX
   SG_ TransRqedRangeDisplayBlankState : 4|2@1+ (1,0) [0|3] "" Vector__XXX
   SG_ TransServiceIndicator : 2|2@1+ (1,0) [0|3] "" Vector__XXX

BO_ 2633935870 ETC6: 8 Vector__XXX
   SG_ ClutchLifeRemaining : 24|8@1+ (0.4,0) [0|100] "%" Vector__XXX
   SG_ LowestPossibleGear : 16|8@1+ (1,-125) [-125|125] "" Vector__XXX
   SG_ HighestPossibleGear : 8|8@1+ (1,-125) [-125|125] "" Vector__XXX
   SG_ RecommendedGear : 0|8@1+ (1,-125) [-125|125] "" Vector__XXX

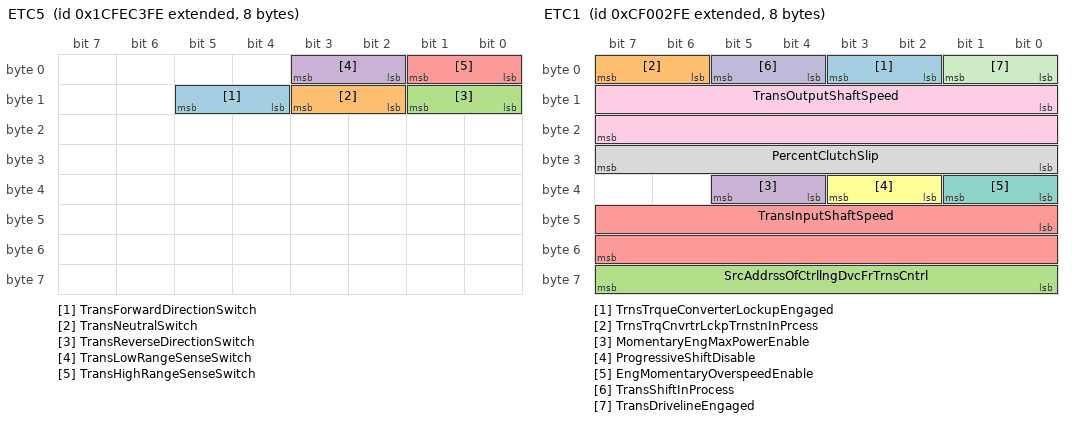
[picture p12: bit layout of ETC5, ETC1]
BO_ 2633942014 ETC5: 8 Vector__XXX
   SG_ TransForwardDirectionSwitch : 12|2@1+ (1,0) [0|3] "" Vector__XXX
   SG_ TransNeutralSwitch : 10|2@1+ (1,0) [0|3] "" Vector__XXX
   SG_ TransReverseDirectionSwitch : 8|2@1+ (1,0) [0|3] "" Vector__XXX
   SG_ TransLowRangeSenseSwitch : 2|2@1+ (1,0) [0|3] "" Vector__XXX
   SG_ TransHighRangeSenseSwitch : 0|2@1+ (1,0) [0|3] "" Vector__XXX

BO_ 2633942526 ETC4: 8 Vector__XXX
   SG_ TransSynchronizerBrakeValue : 8|8@1+ (0.4,0) [0|100] "%" Vector__XXX
   SG_ TransSynchronizerClutchValue : 0|8@1+ (0.4,0) [0|100] "%" Vector__XXX

BO_ 2633943038 ETC3: 8 Vector__XXX
   SG_ TransInertiaBrakeActuator : 46|2@1+ (1,0) [0|3] "" Vector__XXX
   SG_ TransDefuelActuator : 44|2@1+ (1,0) [0|3] "" Vector__XXX
   SG_ TransLockupClutchActuator : 42|2@1+ (1,0) [0|3] "" Vector__XXX
   SG_ TransClutchActuator : 40|2@1+ (1,0) [0|3] "" Vector__XXX
   SG_ TransSplitterIndirectActuator : 38|2@1+ (1,0) [0|3] "" Vector__XXX
   SG_ TransSplitterDirectActuator : 36|2@1+ (1,0) [0|3] "" Vector__XXX
   SG_ TransRangeLowActuator : 34|2@1+ (1,0) [0|3] "" Vector__XXX
   SG_ TransRangeHighActuator : 32|2@1+ (1,0) [0|3] "" Vector__XXX
   SG_ TransShiftFingerGearActuator2 : 30|2@1+ (1,0) [0|3] "" Vector__XXX
   SG_ TransShiftFingerRailActuator2 : 28|2@1+ (1,0) [0|3] "" Vector__XXX
   SG_ TransShiftFingerGearActuator1 : 26|2@1+ (1,0) [0|3] "" Vector__XXX
   SG_ TransShiftFingerRailActuator1 : 24|2@1+ (1,0) [0|3] "" Vector__XXX
   SG_ TrnsShftFngrCenterRailIndicator : 20|2@1+ (1,0) [0|3] "" Vector__XXX
   SG_ TrnsShftFngrEngagementIndicator : 18|2@1+ (1,0) [0|3] "" Vector__XXX
   SG_ TrnsShiftFingerNeutralIndicator : 16|2@1+ (1,0) [0|3] "" Vector__XXX
   SG_ TransShiftFingerRailPos : 8|8@1+ (0.4,0) [0|100] "%" Vector__XXX
   SG_ TransShiftFingerGearPos : 0|8@1+ (0.4,0) [0|100] "%" Vector__XXX

BO_ 2565867006 ETC2: 8 Vector__XXX
   SG_ TransCurrentRange : 48|16@1+ (1,0) [0|255] "" Vector__XXX
   SG_ TransRqedRange : 32|16@1+ (1,0) [0|255] "per" Vector__XXX
   SG_ TransCurrentGear : 24|8@1+ (1,-125) [-125|125] "" Vector__XXX
   SG_ TransActualGearRatio : 8|16@1+ (0.001,0) [0|64.255] "" Vector__XXX
   SG_ TransSelectedGear : 0|8@1+ (1,-125) [-125|125] "" Vector__XXX

BO_ 2364539646 ETC1: 8 Vector__XXX
   SG_ TrnsTrqueConverterLockupEngaged : 2|2@1+ (1,0) [0|3] "" Vector__XXX
   SG_ TrnsTrqCnvrtrLckpTrnstnInPrcess : 6|2@1+ (1,0) [0|3] "" Vector__XXX
   SG_ SrcAddrssOfCtrllngDvcFrTrnsCntrl : 56|8@1+ (1,0) [0|255] "" Vector__XXX
   SG_ MomentaryEngMaxPowerEnable : 36|2@1+ (1,0) [0|3] "" Vector__XXX
   SG_ TransInputShaftSpeed : 40|16@1+ (0.125,0) [0|8031.88] "rpm" Vector__XXX
   SG_ ProgressiveShiftDisable : 34|2@1+ (1,0) [0|3] "" Vector__XXX
   SG_ EngMomentaryOverspeedEnable : 32|2@1+ (1,0) [0|3] "" Vector__XXX
   SG_ PercentClutchSlip : 24|8@1+ (0.4,0) [0|100] "%" Vector__XXX
   SG_ TransOutputShaftSpeed : 8|16@1+ (0.125,0) [0|8031.88] "rpm" Vector__XXX
   SG_ TransShiftInProcess : 4|2@1+ (1,0) [0|3] "" Vector__XXX
   SG_ TransDrivelineEngaged : 0|2@1+ (1,0) [0|3] "" Vector__XXX

BO_ 2566810110 ET3: 8 Vector__XXX
   SG_ EngChargeAirCooler1OutletTemp : 48|16@1+ (0.03125,-273) [-273|1734.97] "deg C" Vector__XXX
   SG_ EngIntkVlvActationSystemOilTemp : 32|16@1+ (0.03125,-273) [-273|1734.97] "deg C" Vector__XXX
   SG_ EngIntakeManifold1AirTemp : 0|16@1+ (0.03125,-273) [-273|1734.97] "deg C" Vector__XXX
   SG_ EngCoolantTempHiRes : 16|16@1+ (0.03125,-273) [-273|1734.97] "deg C" Vector__XXX

BO_ 2566825214 ET2: 8 Vector__XXX
   SG_ EngExhstGsRcrculation1DiffPress : 32|16@1+ (0.0078125,-250) [-250|251.99] "kPa" Vector__XXX
   SG_ EngExhaustGasRecirculation1Temp : 48|16@1+ (0.03125,-273) [-273|1734.97] "deg C" Vector__XXX
   SG_ EngECUTemp : 16|16@1+ (0.03125,-273) [-273|1734.97] "deg C" Vector__XXX
   SG_ EngOilTemp2 : 0|16@1+ (0.03125,-273) [-273|1734.97] "deg C" Vector__XXX

BO_ 2566844158 ET1: 8 Vector__XXX
   SG_ EngFuelTemp1 : 8|8@1+ (1,-40) [-40|210] "deg C" Vector__XXX
   SG_ EngIntercoolerThermostatOpening : 56|8@1+ (0.4,0) [0|100] "%" Vector__XXX
   SG_ EngIntercoolerTemp : 48|8@1+ (1,-40) [-40|210] "deg C" Vector__XXX
   SG_ EngTurboOilTemp : 32|16@1+ (0.03125,-273) [-273|1734.97] "deg C" Vector__XXX
   SG_ EngOilTemp1 : 16|16@1+ (0.03125,-273) [-273|1734.97] "deg C" Vector__XXX
   SG_ EngCoolantTemp : 0|8@1+ (0.03125,-273) [-273|-265.031] "deg C" Vector__XXX

BO_ 2566785022 ET: 8 Vector__XXX
   SG_ EngExhaustGasTempRightManifold : 0|16@1+ (0.03125,-273) [-273|1734.97] "deg C" Vector__XXX
   SG_ EngExhaustGasTempLeftManifold : 16|16@1+ (0.03125,-273) [-273|1734.97] "deg C" Vector__XXX

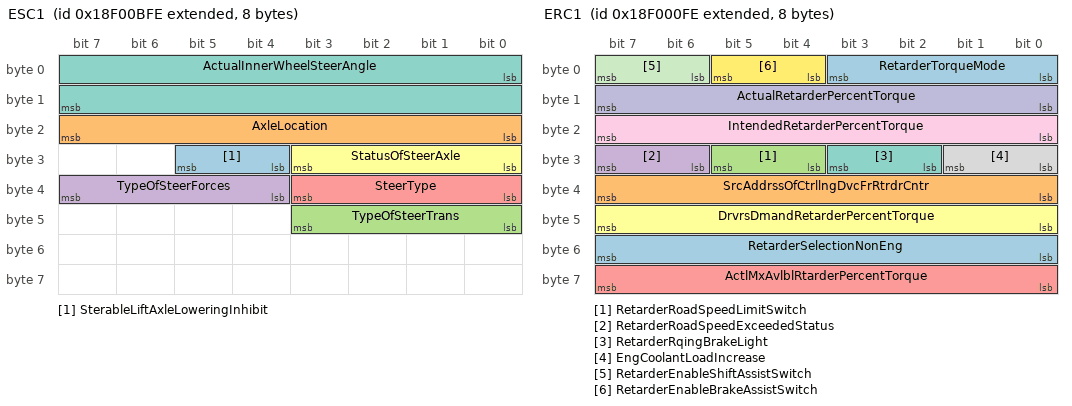
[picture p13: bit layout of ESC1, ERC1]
BO_ 2565868542 ESC1: 8 Vector__XXX
   SG_ SterableLiftAxleLoweringInhibit : 28|2@1+ (1,0) [0|3] "" Vector__XXX
   SG_ AxleLocation : 16|8@1+ (1,0) [0|255] "" Vector__XXX
   SG_ TypeOfSteerTrans : 40|4@1+ (1,0) [0|15] "" Vector__XXX
   SG_ TypeOfSteerForces : 36|4@1+ (1,0) [0|15] "" Vector__XXX
   SG_ SteerType : 32|4@1+ (1,0) [0|15] "" Vector__XXX
   SG_ StatusOfSteerAxle : 24|4@1+ (1,0) [0|15] "" Vector__XXX
   SG_ ActualInnerWheelSteerAngle : 0|16@1+ (0.00390625,-125) [-125|125] "deg" Vector__XXX

BO_ 2633941758 ERC2: 8 Vector__XXX
   SG_ TransOutputRetarder : 0|2@1+ (1,0) [0|3] "" Vector__XXX

BO_ 2565865726 ERC1: 8 Vector__XXX
   SG_ RetarderSelectionNonEng : 48|8@1+ (0.4,0) [0|100] "%" Vector__XXX
   SG_ SrcAddrssOfCtrllngDvcFrRtrdrCntr : 32|8@1+ (1,0) [0|255] "" Vector__XXX
   SG_ RetarderRoadSpeedLimitSwitch : 28|2@1+ (1,0) [0|3] "" Vector__XXX
   SG_ RetarderRoadSpeedExceededStatus : 30|2@1+ (1,0) [0|3] "" Vector__XXX
   SG_ ActlMxAvlblRtarderPercentTorque : 56|8@1+ (1,-125) [-125|125] "%" Vector__XXX
   SG_ DrvrsDmandRetarderPercentTorque : 40|8@1+ (1,-125) [-125|125] "%" Vector__XXX
   SG_ RetarderRqingBrakeLight : 26|2@1+ (1,0) [0|3] "" Vector__XXX
   SG_ EngCoolantLoadIncrease : 24|2@1+ (1,0) [0|3] "" Vector__XXX
   SG_ IntendedRetarderPercentTorque : 16|8@1+ (1,-125) [-125|125] "%" Vector__XXX
   SG_ ActualRetarderPercentTorque : 8|8@1+ (1,-125) [-125|125] "%" Vector__XXX
   SG_ RetarderEnableShiftAssistSwitch : 6|2@1+ (1,0) [0|3] "" Vector__XXX
   SG_ RetarderEnableBrakeAssistSwitch : 4|2@1+ (1,0) [0|3] "" Vector__XXX
   SG_ RetarderTorqueMode : 0|4@1+ (1,0) [0|15] "" Vector__XXX

BO_ 2633932798 EPT5: 8 Vector__XXX
   SG_ EngExhaustGasPort20Temp : 48|16@1+ (0.03125,-273) [-273|1734.97] "deg C" Vector__XXX
   SG_ EngExhaustGasPort19Temp : 32|16@1+ (0.03125,-273) [-273|1734.97] "deg C" Vector__XXX
   SG_ EngExhaustGasPort18Temp : 16|16@1+ (0.03125,-273) [-273|1734.97] "deg C" Vector__XXX
   SG_ EngExhaustGasPort17Temp : 0|16@1+ (0.03125,-273) [-273|1734.97] "deg C" Vector__XXX

BO_ 2566824190 EPT4: 8 Vector__XXX
   SG_ EngExhaustGasPort16Temp : 48|16@1+ (0.03125,-273) [-273|1734.97] "deg C" Vector__XXX
   SG_ EngExhaustGasPort15Temp : 32|16@1+ (0.03125,-273) [-273|1734.97] "deg C" Vector__XXX
   SG_ EngExhaustGasPort14Temp : 16|16@1+ (0.03125,-273) [-273|1734.97] "deg C" Vector__XXX
   SG_ EngExhaustGasPort13Temp : 0|16@1+ (0.03125,-273) [-273|1734.97] "deg C" Vector__XXX

BO_ 2633933310 EPT3: 8 Vector__XXX
   SG_ EngExhaustGasPort12Temp : 48|16@1+ (0.03125,-273) [-273|1734.97] "deg C" Vector__XXX
   SG_ EngExhaustGasPort11Temp : 32|16@1+ (0.03125,-273) [-273|1734.97] "deg C" Vector__XXX
   SG_ EngExhaustGasPort10Temp : 16|16@1+ (0.03125,-273) [-273|1734.97] "deg C" Vector__XXX
   SG_ EngExhaustGasPort9Temp : 0|16@1+ (0.03125,-273) [-273|1734.97] "deg C" Vector__XXX

BO_ 2633933566 EPT2: 8 Vector__XXX
   SG_ EngExhaustGasPort8Temp : 48|16@1+ (0.03125,-273) [-273|1734.97] "deg C" Vector__XXX
   SG_ EngExhaustGasPort7Temp : 32|16@1+ (0.03125,-273) [-273|1734.97] "deg C" Vector__XXX
   SG_ EngExhaustGasPort6Temp : 16|16@1+ (0.03125,-273) [-273|1734.97] "deg C" Vector__XXX
   SG_ EngExhaustGasPort5Temp : 0|16@1+ (0.03125,-273) [-273|1734.97] "deg C" Vector__XXX

BO_ 2633933822 EPT1: 8 Vector__XXX
   SG_ EngExhaustGasPort4Temp : 48|16@1+ (0.03125,-273) [-273|1734.97] "deg C" Vector__XXX
   SG_ EngExhaustGasPort3Temp : 32|16@1+ (0.03125,-273) [-273|1734.97] "deg C" Vector__XXX
   SG_ EngExhaustGasPort2Temp : 16|16@1+ (0.03125,-273) [-273|1734.97] "deg C" Vector__XXX
   SG_ EngExhaustGasPort1Temp : 0|16@1+ (0.03125,-273) [-273|1734.97] "deg C" Vector__XXX

BO_ 2566776062 EPD: 8 Vector__XXX
   SG_ PayloadPercentage : 0|8@1+ (1,0) [0|250] "%" Vector__XXX

BO_ 2566771454 EP: 8 Vector__XXX
   SG_ DataMemoryUsage : 16|8@1+ (0.4,0) [0|100] "%" Vector__XXX
   SG_ KeepAliveBatteryConsumption : 0|16@1+ (1,0) [0|64255] "mAhr" Vector__XXX

BO_ 2566775806 EOAC: 8 Vector__XXX
   SG_ TravelVelocityCtrlPos : 0|8@1+ (1,-125) [-125|125] "%" Vector__XXX

BO_ 2633935358 EO1: 8 Vector__XXX
   SG_ EngExhstGsOxygnSnsrClsdLpOprton : 62|2@1+ (1,0) [0|3] "" Vector__XXX
   SG_ EngExhstGsOxygnSnsrFlngCrrction : 48|8@1+ (1,-125) [-125|125] "%" Vector__XXX
   SG_ EngActualExhaustOxygen : 32|16@1+ (0.0025,0) [0|160.637] "%" Vector__XXX
   SG_ EngDesiredExhaustOxygen : 16|16@1+ (0.0025,0) [0|160.637] "%" Vector__XXX
   SG_ EngDesiredRatedExhaustOxygen : 0|16@1+ (0.0025,0) [0|160.637] "%" Vector__XXX

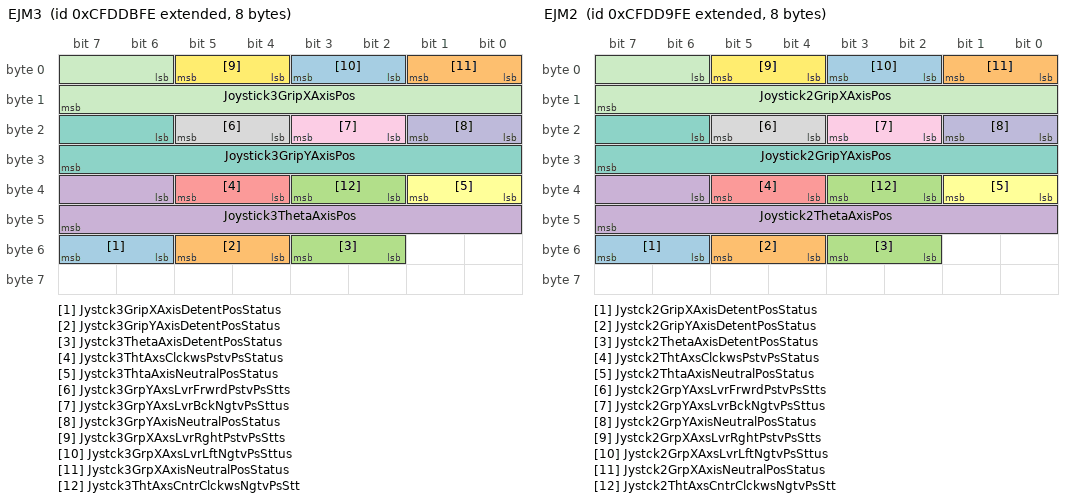
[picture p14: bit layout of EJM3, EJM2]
BO_ 2365447166 EJM3: 8 Vector__XXX
   SG_ Jystck3GripXAxisDetentPosStatus : 54|2@1+ (1,0) [0|3] "" Vector__XXX
   SG_ Jystck3GripYAxisDetentPosStatus : 52|2@1+ (1,0) [0|3] "" Vector__XXX
   SG_ Jystck3ThetaAxisDetentPosStatus : 50|2@1+ (1,0) [0|3] "" Vector__XXX
   SG_ Joystick3ThetaAxisPos : 38|10@1+ (0.1,0) [0|102] "%" Vector__XXX
   SG_ Jystck3ThtAxsClckwsPstvPsStatus : 36|2@1+ (1,0) [0|3] "" Vector__XXX
   SG_ Jystck3ThtaAxisNeutralPosStatus : 32|2@1+ (1,0) [0|3] "" Vector__XXX
   SG_ Joystick3GripYAxisPos : 22|10@1+ (0.1,0) [0|102] "%" Vector__XXX
   SG_ Jystck3GrpYAxsLvrFrwrdPstvPsStts : 20|2@1+ (1,0) [0|3] "" Vector__XXX
   SG_ Jystck3GrpYAxsLvrBckNgtvPsSttus : 18|2@1+ (1,0) [0|3] "" Vector__XXX
   SG_ Jystck3GrpYAxisNeutralPosStatus : 16|2@1+ (1,0) [0|3] "" Vector__XXX
   SG_ Joystick3GripXAxisPos : 6|10@1+ (0.1,0) [0|102] "%" Vector__XXX
   SG_ Jystck3GrpXAxsLvrRghtPstvPsStts : 4|2@1+ (1,0) [0|3] "" Vector__XXX
   SG_ Jystck3GrpXAxsLvrLftNgtvPsSttus : 2|2@1+ (1,0) [0|3] "" Vector__XXX
   SG_ Jystck3GrpXAxisNeutralPosStatus : 0|2@1+ (1,0) [0|3] "" Vector__XXX
   SG_ Jystck3ThtAxsCntrClckwsNgtvPsStt : 34|2@1+ (1,0) [0|3] "" Vector__XXX

BO_ 2365446654 EJM2: 8 Vector__XXX
   SG_ Jystck2GripXAxisDetentPosStatus : 54|2@1+ (1,0) [0|3] "" Vector__XXX
   SG_ Jystck2GripYAxisDetentPosStatus : 52|2@1+ (1,0) [0|3] "" Vector__XXX
   SG_ Jystck2ThetaAxisDetentPosStatus : 50|2@1+ (1,0) [0|3] "" Vector__XXX
   SG_ Joystick2ThetaAxisPos : 38|10@1+ (0.1,0) [0|102] "%" Vector__XXX
   SG_ Jystck2ThtAxsClckwsPstvPsStatus : 36|2@1+ (1,0) [0|3] "" Vector__XXX
   SG_ Jystck2ThtaAxisNeutralPosStatus : 32|2@1+ (1,0) [0|3] "" Vector__XXX
   SG_ Joystick2GripYAxisPos : 22|10@1+ (0.1,0) [0|102] "%" Vector__XXX
   SG_ Jystck2GrpYAxsLvrFrwrdPstvPsStts : 20|2@1+ (1,0) [0|3] "" Vector__XXX
   SG_ Jystck2GrpYAxsLvrBckNgtvPsSttus : 18|2@1+ (1,0) [0|3] "" Vector__XXX
   SG_ Jystck2GrpYAxisNeutralPosStatus : 16|2@1+ (1,0) [0|3] "" Vector__XXX
   SG_ Joystick2GripXAxisPos : 6|10@1+ (0.1,0) [0|102] "%" Vector__XXX
   SG_ Jystck2GrpXAxsLvrRghtPstvPsStts : 4|2@1+ (1,0) [0|3] "" Vector__XXX
   SG_ Jystck2GrpXAxsLvrLftNgtvPsSttus : 2|2@1+ (1,0) [0|3] "" Vector__XXX
   SG_ Jystck2GrpXAxisNeutralPosStatus : 0|2@1+ (1,0) [0|3] "" Vector__XXX
   SG_ Jystck2ThtAxsCntrClckwsNgtvPsStt : 34|2@1+ (1,0) [0|3] "" Vector__XXX

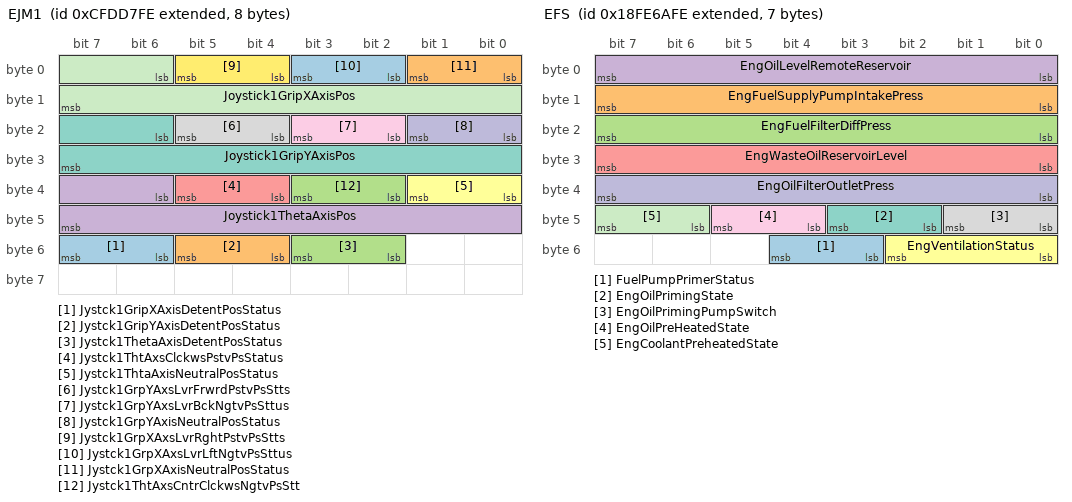
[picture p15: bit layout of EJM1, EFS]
BO_ 2365446142 EJM1: 8 Vector__XXX
   SG_ Jystck1GripXAxisDetentPosStatus : 54|2@1+ (1,0) [0|3] "" Vector__XXX
   SG_ Jystck1GripYAxisDetentPosStatus : 52|2@1+ (1,0) [0|3] "" Vector__XXX
   SG_ Jystck1ThetaAxisDetentPosStatus : 50|2@1+ (1,0) [0|3] "" Vector__XXX
   SG_ Joystick1ThetaAxisPos : 38|10@1+ (0.1,0) [0|102] "%" Vector__XXX
   SG_ Jystck1ThtAxsClckwsPstvPsStatus : 36|2@1+ (1,0) [0|3] "" Vector__XXX
   SG_ Jystck1ThtaAxisNeutralPosStatus : 32|2@1+ (1,0) [0|3] "" Vector__XXX
   SG_ Joystick1GripYAxisPos : 22|10@1+ (0.1,0) [0|102] "%" Vector__XXX
   SG_ Jystck1GrpYAxsLvrFrwrdPstvPsStts : 20|2@1+ (1,0) [0|3] "" Vector__XXX
   SG_ Jystck1GrpYAxsLvrBckNgtvPsSttus : 18|2@1+ (1,0) [0|3] "" Vector__XXX
   SG_ Jystck1GrpYAxisNeutralPosStatus : 16|2@1+ (1,0) [0|3] "" Vector__XXX
   SG_ Joystick1GripXAxisPos : 6|10@1+ (0.1,0) [0|102] "%" Vector__XXX
   SG_ Jystck1GrpXAxsLvrRghtPstvPsStts : 4|2@1+ (1,0) [0|3] "" Vector__XXX
   SG_ Jystck1GrpXAxsLvrLftNgtvPsSttus : 2|2@1+ (1,0) [0|3] "" Vector__XXX
   SG_ Jystck1GrpXAxisNeutralPosStatus : 0|2@1+ (1,0) [0|3] "" Vector__XXX
   SG_ Jystck1ThtAxsCntrClckwsNgtvPsStt : 34|2@1+ (1,0) [0|3] "" Vector__XXX

BO_ 2633929470 EI: 8 Vector__XXX
   SG_ EngFuelRackPos : 24|8@1+ (0.4,0) [0|100] "%" Vector__XXX
   SG_ EngGasMassFlowRate1 : 32|16@1+ (0.05,0) [0|3212.75] "kg/h" Vector__XXX
   SG_ InstantaneousEstBrakePower : 48|16@1+ (0.5,0) [0|32127.5] "kW" Vector__XXX
   SG_ EngExhaustGasPress : 8|16@1+ (0.0078125,-250) [-250|251.99] "kPa" Vector__XXX
   SG_ EngPrefilterOilPress : 0|8@1+ (4,0) [0|1000] "kPa" Vector__XXX

BO_ 2633937406 EH: 8 Vector__XXX
   SG_ TotalECURunTime : 32|32@1+ (0.05,0) [0|2.10554e+08] "hr" Vector__XXX
   SG_ TotalECUDistance : 0|32@1+ (0.125,0) [0|5.26385e+08] "km" Vector__XXX

BO_ 2364541694 EGF1: 8 Vector__XXX
   SG_ EngIntakeAirMassFlowRate : 16|16@1+ (0.05,0) [0|3212.75] "kg/h" Vector__XXX
   SG_ EngExhstGsRcrclton2MassFlowRate : 32|16@1+ (0.05,0) [0|3212.75] "kg/h" Vector__XXX
   SG_ EngExhstGsRcrclton1MassFlowRate : 0|16@1+ (0.05,0) [0|3212.75] "kg/h" Vector__XXX

BO_ 2566810366 EFS: 7 Vector__XXX
   SG_ FuelPumpPrimerStatus : 51|2@1+ (1,0) [0|3] "" Vector__XXX
   SG_ EngFuelSupplyPumpIntakePress : 8|8@1+ (2,0) [0|500] "kPa" Vector__XXX
   SG_ EngFuelFilterDiffPress : 16|8@1+ (2,0) [0|500] "kPa" Vector__XXX
   SG_ EngOilLevelRemoteReservoir : 0|8@1+ (0.4,0) [0|100] "%" Vector__XXX
   SG_ EngWasteOilReservoirLevel : 24|8@1+ (0.4,0) [0|100] "%" Vector__XXX
   SG_ EngVentilationStatus : 48|3@1+ (1,0) [0|7] "" Vector__XXX
   SG_ EngOilPrimingState : 42|2@1+ (1,0) [0|3] "" Vector__XXX
   SG_ EngOilPrimingPumpSwitch : 40|2@1+ (1,0) [0|3] "" Vector__XXX
   SG_ EngOilPreHeatedState : 44|2@1+ (1,0) [0|3] "" Vector__XXX
   SG_ EngOilFilterOutletPress : 32|8@1+ (4,0) [0|1000] "kPa" Vector__XXX
   SG_ EngCoolantPreheatedState : 46|2@1+ (1,0) [0|3] "" Vector__XXX

BO_ 2566767102 EFL_P3: 8 Vector__XXX
   SG_ EngExhstVlvActtonSystemOilPress : 24|16@1+ (0.00390625,0) [0|251] "MPa" Vector__XXX
   SG_ EngExhstGsRcrcltion1OutletPress : 40|8@1+ (2,0) [0|500] "kPa" Vector__XXX
   SG_ EngExhstGsRcrcltion1IntakePress : 16|8@1+ (2,0) [0|500] "kPa" Vector__XXX
   SG_ EngIntkVlvActtionSystemOilPress : 0|16@1+ (0.00390625,0) [0|251] "MPa" Vector__XXX

BO_ 2566839294 EFL_P2: 8 Vector__XXX
   SG_ EngInjectorMeteringRail2Press : 48|16@1+ (0.00390625,0) [0|251] "MPa" Vector__XXX
   SG_ EngInjectorTimingRail1Press : 32|16@1+ (0.00390625,0) [0|251] "MPa" Vector__XXX
   SG_ EngInjectorMeteringRail1Press : 16|16@1+ (0.00390625,0) [0|251] "MPa" Vector__XXX
   SG_ EngInjectionCtrlPress : 0|16@1+ (0.00390625,0) [0|251] "MPa" Vector__XXX

BO_ 2566844414 EFL_P1: 8 Vector__XXX
   SG_ EngCoolantLevel : 56|8@1+ (0.4,0) [0|100] "%" Vector__XXX
   SG_ EngCoolantPress : 48|8@1+ (2,0) [0|500] "kPa" Vector__XXX
   SG_ EngCrankcasePress : 32|16@1+ (0.0078125,-250) [-250|251.99] "kPa" Vector__XXX
   SG_ EngOilPress : 24|8@1+ (4,0) [0|1000] "kPa" Vector__XXX
   SG_ EngOilLevel : 16|8@1+ (0.4,0) [0|100] "%" Vector__XXX
   SG_ EngExCrankcaseBlowbyPress : 8|8@1+ (0.05,0) [0|12.5] "kPa" Vector__XXX
   SG_ EngFuelDeliveryPress : 0|8@1+ (4,0) [0|1000] "kPa" Vector__XXX

BO_ 2633929726 EES: 8 Vector__XXX
   SG_ TurningGearEngaged : 18|2@1+ (1,0) [0|3] "" Vector__XXX
   SG_ SafetyWireStatus : 16|2@1+ (1,0) [0|3] "" Vector__XXX
   SG_ ElectricalLoad : 0|16@1+ (0.5,0) [0|32127.5] "kW" Vector__XXX

BO_ 2566772222 EEC5: 8 Vector__XXX
   SG_ EngVrableGeometryTurbo1CtrlMode : 52|2@1+ (1,0) [0|3] "" Vector__XXX
   SG_ EngTrb1ClcltedTurbineIntakeTemp : 0|16@1+ (0.03125,-273) [-273|1734.97] "deg C" Vector__XXX
   SG_ EngExhstGsRcrculation1ValveCtrl : 32|16@1+ (0.0025,0) [0|160.637] "%" Vector__XXX
   SG_ EngVrblGometryTurbo1ActuatorPos : 56|8@1+ (0.4,0) [0|100] "%" Vector__XXX
   SG_ EngVrblGmtryTrbArCtrlShtffValve : 48|2@1+ (1,0) [0|3] "" Vector__XXX
   SG_ EngTrb1ClcltedTurbineOutletTemp : 16|16@1+ (0.03125,-273) [-273|1734.97] "deg C" Vector__XXX

BO_ 2633940734 EEC4: 8 Vector__XXX
   SG_ EngRotationDirection : 32|2@1+ (1,0) [0|3] "" Vector__XXX
   SG_ CrnkAttmptCntOnPrsntStrtAttempt : 40|8@1+ (1,0) [0|250] "" Vector__XXX
   SG_ EngIntakeManifoldPressCtrlMode : 34|2@1+ (1,0) [0|3] "" Vector__XXX
   SG_ EngRatedSpeed : 16|16@1+ (0.125,0) [0|8031.88] "rpm" Vector__XXX
   SG_ EngRatedPower : 0|16@1+ (0.5,0) [0|32127.5] "kW" Vector__XXX

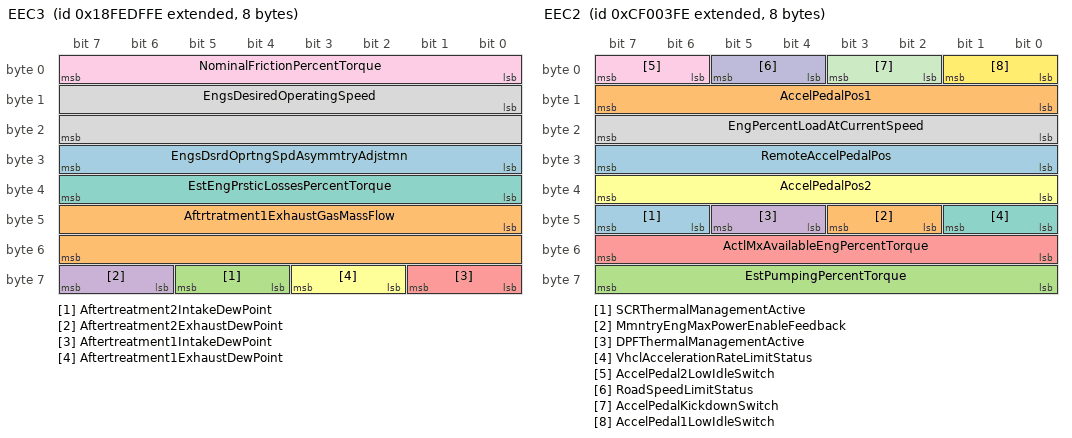
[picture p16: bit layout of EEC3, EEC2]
BO_ 2566840318 EEC3: 8 Vector__XXX
   SG_ EngsDsrdOprtngSpdAsymmtryAdjstmn : 24|8@1+ (1,0) [0|250] "" Vector__XXX
   SG_ Aftrtratment1ExhaustGasMassFlow : 40|16@1+ (0.2,0) [0|12851] "kg/h" Vector__XXX
   SG_ Aftertreatment2IntakeDewPoint : 60|2@1+ (1,0) [0|3] "" Vector__XXX
   SG_ Aftertreatment2ExhaustDewPoint : 62|2@1+ (1,0) [0|3] "" Vector__XXX
   SG_ Aftertreatment1IntakeDewPoint : 56|2@1+ (1,0) [0|3] "" Vector__XXX
   SG_ Aftertreatment1ExhaustDewPoint : 58|2@1+ (1,0) [0|3] "" Vector__XXX
   SG_ EstEngPrsticLossesPercentTorque : 32|8@1+ (1,-125) [-125|125] "%" Vector__XXX
   SG_ EngsDesiredOperatingSpeed : 8|16@1+ (0.125,0) [0|8031.88] "rpm" Vector__XXX
   SG_ NominalFrictionPercentTorque : 0|8@1+ (1,-125) [-125|125] "%" Vector__XXX

BO_ 2364539902 EEC2: 8 Vector__XXX
   SG_ SCRThermalManagementActive : 46|2@1+ (1,0) [0|3] "" Vector__XXX
   SG_ MmntryEngMaxPowerEnableFeedback : 42|2@1+ (1,0) [0|3] "" Vector__XXX
   SG_ EstPumpingPercentTorque : 56|8@1+ (1,-125) [-125|125] "%" Vector__XXX
   SG_ DPFThermalManagementActive : 44|2@1+ (1,0) [0|3] "" Vector__XXX
   SG_ ActlMxAvailableEngPercentTorque : 48|8@1+ (0.4,0) [0|100] "%" Vector__XXX
   SG_ AccelPedalPos2 : 32|8@1+ (0.4,0) [0|100] "%" Vector__XXX
   SG_ VhclAccelerationRateLimitStatus : 40|2@1+ (1,0) [0|3] "" Vector__XXX
   SG_ EngPercentLoadAtCurrentSpeed : 16|8@1+ (1,0) [0|250] "%" Vector__XXX
   SG_ AccelPedal2LowIdleSwitch : 6|2@1+ (1,0) [0|3] "" Vector__XXX
   SG_ RoadSpeedLimitStatus : 4|2@1+ (1,0) [0|3] "" Vector__XXX
   SG_ AccelPedalKickdownSwitch : 2|2@1+ (1,0) [0|3] "" Vector__XXX
   SG_ AccelPedal1LowIdleSwitch : 0|2@1+ (1,0) [0|3] "" Vector__XXX
   SG_ RemoteAccelPedalPos : 24|8@1+ (0.4,0) [0|100] "%" Vector__XXX
   SG_ AccelPedalPos1 : 8|8@1+ (0.4,0) [0|100] "%" Vector__XXX

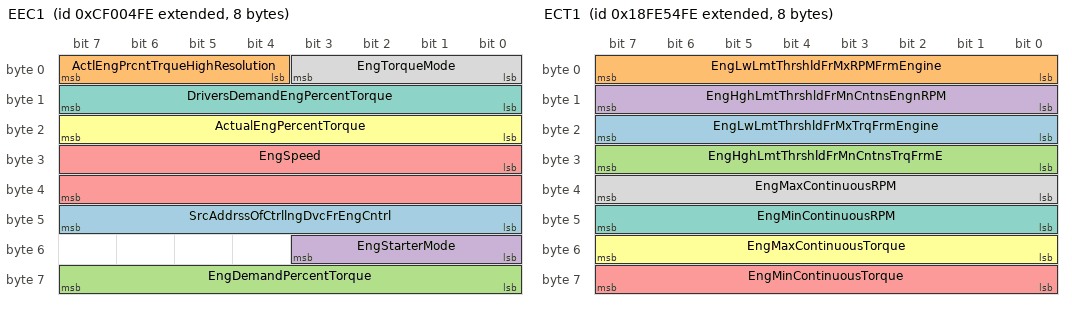
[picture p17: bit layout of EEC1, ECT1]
BO_ 2364540158 EEC1: 8 Vector__XXX
   SG_ SrcAddrssOfCtrllngDvcFrEngCntrl : 40|8@1+ (1,0) [0|255] "" Vector__XXX
   SG_ ActlEngPrcntTrqueHighResolution : 4|4@1+ (0.125,0) [0|0.875] "%" Vector__XXX
   SG_ EngDemandPercentTorque : 56|8@1+ (1,-125) [-125|125] "%" Vector__XXX
   SG_ EngStarterMode : 48|4@1+ (1,0) [0|15] "" Vector__XXX
   SG_ EngSpeed : 24|16@1+ (0.125,0) [0|8031.88] "rpm" Vector__XXX
   SG_ ActualEngPercentTorque : 16|8@1+ (1,-125) [-125|125] "%" Vector__XXX
   SG_ DriversDemandEngPercentTorque : 8|8@1+ (1,-125) [-125|125] "%" Vector__XXX
   SG_ EngTorqueMode : 0|4@1+ (1,0) [0|15] "" Vector__XXX

BO_ 2566768126 ECUID: 8 Vector__XXX
   SG_ ECUType : 24|8@1+ (1,0) [0|255] "" Vector__XXX
   SG_ ECULocation : 16|8@1+ (1,0) [0|255] "" Vector__XXX
   SG_ ECUSerialNumber : 8|8@1+ (1,0) [0|255] "" Vector__XXX
   SG_ ECUPartNumber : 0|8@1+ (1,0) [0|255] "" Vector__XXX

BO_ 2566804734 ECT1: 8 Vector__XXX
   SG_ EngLwLmtThrshldFrMxTrqFrmEngine : 16|8@1+ (1,-125) [-125|125] "%" Vector__XXX
   SG_ EngLwLmtThrshldFrMxRPMFrmEngine : 0|8@1+ (32,0) [0|8000] "rpm" Vector__XXX
   SG_ EngHghLmtThrshldFrMnCntnsTrqFrmE : 24|8@1+ (1,-125) [-125|125] "%" Vector__XXX
   SG_ EngHghLmtThrshldFrMnCntnsEngnRPM : 8|8@1+ (32,0) [0|8000] "rpm" Vector__XXX
   SG_ EngMinContinuousTorque : 56|8@1+ (1,-125) [-125|125] "%" Vector__XXX
   SG_ EngMaxContinuousTorque : 48|8@1+ (1,-125) [-125|125] "%" Vector__XXX
   SG_ EngMinContinuousRPM : 40|8@1+ (32,0) [0|8000] "rpm" Vector__XXX
   SG_ EngMaxContinuousRPM : 32|8@1+ (32,0) [0|8000] "rpm" Vector__XXX

BO_ 2566841342 EC1: 39 Vector__XXX
   SG_ SupportTSC1CtrlPurposeGroup4 : 304|8@1+ (1,0) [0|255] "" Vector__XXX
   SG_ SupportTSC1CtrlPurposeGroup3 : 296|8@1+ (1,0) [0|255] "" Vector__XXX
   SG_ SupportTSC1CtrlPurposeGroup2 : 288|8@1+ (1,0) [0|255] "" Vector__XXX
   SG_ SupportTSC1CtrlPurposeGroup1 : 280|8@1+ (1,0) [0|255] "" Vector__XXX
   SG_ SupportVariableRateTSC1Message : 272|8@1+ (1,0) [0|255] "" Vector__XXX
   SG_ EngDefaultTorqueLimit : 256|16@1+ (1,0) [0|64255] "Nm" Vector__XXX
   SG_ EngMomentOfInertia : 240|16@1+ (0.004,0) [0|257.02] "kg*m*m" Vector__XXX
   SG_ EngExRngRqdSpdCtrlRngUpperLimit : 224|16@1+ (0.125,0) [0|8031.88] "rpm" Vector__XXX
   SG_ EngRqdTorqueCtrlRangeUpperLimit : 216|8@1+ (1,-125) [-125|125] "%" Vector__XXX
   SG_ EngRqdTorqueCtrlRangeLowerLimit : 208|8@1+ (1,-125) [-125|125] "%" Vector__XXX
   SG_ EngRqedSpeedCtrlRangeUpperLimit : 200|8@1+ (10,0) [0|2500] "rpm" Vector__XXX
   SG_ EngRqedSpeedCtrlRangeLowerLimit : 192|8@1+ (10,0) [0|2500] "rpm" Vector__XXX
   SG_ EngMxMomentaryOverrideTimeLimit : 184|8@1+ (0.1,0) [0|25] "s" Vector__XXX
   SG_ EngMxMmntaryOverrideSpeedPoint7 : 168|16@1+ (0.125,0) [0|8031.88] "rpm" Vector__XXX
   SG_ EngReferenceTorque : 152|16@1+ (1,0) [0|64255] "Nm" Vector__XXX
   SG_ EngSpeedAtHighIdlePoint6 : 120|16@1+ (0.125,0) [0|8031.88] "rpm" Vector__XXX
   SG_ EngGainOfEndspeedGovernor : 136|16@1+ (0.00078125,0) [0|50.2] "%/rpm" Vector__XXX
   SG_ EngPercentTorqueAtPoint5 : 112|8@1+ (1,-125) [-125|125] "%" Vector__XXX
   SG_ EngSpeedAtPoint5 : 96|16@1+ (0.125,0) [0|8031.88] "rpm" Vector__XXX
   SG_ EngPercentTorqueAtPoint4 : 88|8@1+ (1,-125) [-125|125] "%" Vector__XXX
   SG_ EngSpeedAtPoint4 : 72|16@1+ (0.125,0) [0|8031.88] "rpm" Vector__XXX
   SG_ EngPercentTorqueAtPoint3 : 64|8@1+ (1,-125) [-125|125] "%" Vector__XXX
   SG_ EngSpeedAtPoint3 : 48|16@1+ (0.125,0) [0|8031.88] "rpm" Vector__XXX
   SG_ EngPercentTorqueAtPoint2 : 40|8@1+ (1,-125) [-125|125] "%" Vector__XXX
   SG_ EngSpeedAtPoint2 : 24|16@1+ (0.125,0) [0|8031.88] "rpm" Vector__XXX
   SG_ EngPercentTorqueAtIdlePoint1 : 16|8@1+ (1,-125) [-125|125] "%" Vector__XXX
   SG_ EngSpeedAtIdlePoint1 : 0|16@1+ (0.125,0) [0|8031.88] "rpm" Vector__XXX

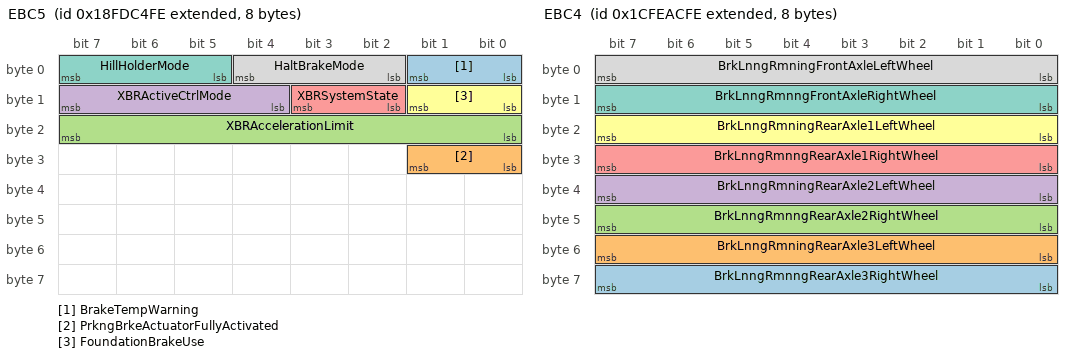
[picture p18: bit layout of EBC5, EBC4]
BO_ 2566767870 EBC5: 8 Vector__XXX
   SG_ BrakeTempWarning : 0|2@1+ (1,0) [0|3] "" Vector__XXX
   SG_ PrkngBrkeActuatorFullyActivated : 24|2@1+ (1,0) [0|3] "" Vector__XXX
   SG_ XBRAccelerationLimit : 16|8@1+ (0.1,-12.5) [-12.5|12.5] "m/s/s" Vector__XXX
   SG_ XBRActiveCtrlMode : 12|4@1+ (1,0) [0|15] "" Vector__XXX
   SG_ XBRSystemState : 10|2@1+ (1,0) [0|3] "" Vector__XXX
   SG_ FoundationBrakeUse : 8|2@1+ (1,0) [0|3] "" Vector__XXX
   SG_ HillHolderMode : 5|3@1+ (1,0) [0|7] "" Vector__XXX
   SG_ HaltBrakeMode : 2|3@1+ (1,0) [0|7] "" Vector__XXX

BO_ 2633936126 EBC4: 8 Vector__XXX
   SG_ BrkLnngRmnngRearAxle3RightWheel : 56|8@1+ (0.4,0) [0|100] "%" Vector__XXX
   SG_ BrkLnngRmningRearAxle3LeftWheel : 48|8@1+ (0.4,0) [0|100] "%" Vector__XXX
   SG_ BrkLnngRmnngRearAxle2RightWheel : 40|8@1+ (0.4,0) [0|100] "%" Vector__XXX
   SG_ BrkLnngRmningRearAxle2LeftWheel : 32|8@1+ (0.4,0) [0|100] "%" Vector__XXX
   SG_ BrkLnngRmnngRearAxle1RightWheel : 24|8@1+ (0.4,0) [0|100] "%" Vector__XXX
   SG_ BrkLnngRmningRearAxle1LeftWheel : 16|8@1+ (0.4,0) [0|100] "%" Vector__XXX
   SG_ BrkLnngRmnngFrontAxleRightWheel : 8|8@1+ (0.4,0) [0|100] "%" Vector__XXX
   SG_ BrkLnngRmningFrontAxleLeftWheel : 0|8@1+ (0.4,0) [0|100] "%" Vector__XXX

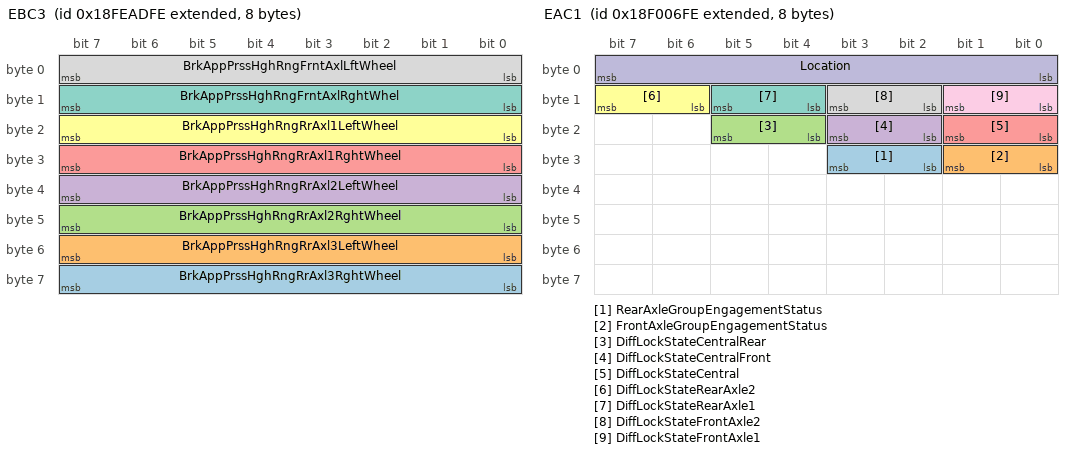
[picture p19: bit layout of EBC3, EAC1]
BO_ 2566827518 EBC3: 8 Vector__XXX
   SG_ BrkAppPrssHghRngRrAxl3RghtWheel : 56|8@1+ (5,0) [0|1250] "kPa" Vector__XXX
   SG_ BrkAppPrssHghRngRrAxl3LeftWheel : 48|8@1+ (5,0) [0|1250] "kPa" Vector__XXX
   SG_ BrkAppPrssHghRngRrAxl2RghtWheel : 40|8@1+ (5,0) [0|1250] "kPa" Vector__XXX
   SG_ BrkAppPrssHghRngRrAxl2LeftWheel : 32|8@1+ (5,0) [0|1250] "kPa" Vector__XXX
   SG_ BrkAppPrssHghRngRrAxl1RghtWheel : 24|8@1+ (5,0) [0|1250] "kPa" Vector__XXX
   SG_ BrkAppPrssHghRngRrAxl1LeftWheel : 16|8@1+ (5,0) [0|1250] "kPa" Vector__XXX
   SG_ BrkAppPrssHghRngFrntAxlRghtWhel : 8|8@1+ (5,0) [0|1250] "kPa" Vector__XXX
   SG_ BrkAppPrssHghRngFrntAxlLftWheel : 0|8@1+ (5,0) [0|1250] "kPa" Vector__XXX

BO_ 2566832126 EBC2: 8 Vector__XXX
   SG_ RlativeSpeedRearAxle2RightWheel : 56|8@1+ (0.0625,-7.8125) [-7.8125|7.8125] "km/h" Vector__XXX
   SG_ RelativeSpeedRearAxle2LeftWheel : 48|8@1+ (0.0625,-7.8125) [-7.8125|7.8125] "km/h" Vector__XXX
   SG_ RlativeSpeedRearAxle1RightWheel : 40|8@1+ (0.0625,-7.8125) [-7.8125|7.8125] "km/h" Vector__XXX
   SG_ RelativeSpeedRearAxle1LeftWheel : 32|8@1+ (0.0625,-7.8125) [-7.8125|7.8125] "km/h" Vector__XXX
   SG_ RlativeSpeedFrontAxleRightWheel : 24|8@1+ (0.0625,-7.8125) [-7.8125|7.8125] "km/h" Vector__XXX
   SG_ RelativeSpeedFrontAxleLeftWheel : 16|8@1+ (0.0625,-7.8125) [-7.8125|7.8125] "km/h" Vector__XXX
   SG_ FrontAxleSpeed : 0|16@1+ (0.00390625,0) [0|250.996] "km/h" Vector__XXX

BO_ 2565865982 EBC1: 8 Vector__XXX
   SG_ EngAuxShutdownSwitch : 28|2@1+ (1,0) [0|3] "" Vector__XXX
   SG_ SrcAddrssOfCtrllngDvcFrBrkCntrl : 48|8@1+ (1,0) [0|255] "" Vector__XXX
   SG_ BrakePedalPos : 8|8@1+ (0.4,0) [0|100] "%" Vector__XXX
   SG_ TrctrMntdTrilerABSWarningSignal : 62|2@1+ (1,0) [0|3] "" Vector__XXX
   SG_ TrailerABSStatus : 60|2@1+ (1,0) [0|3] "" Vector__XXX
   SG_ HaltBrakeSwitch : 58|2@1+ (1,0) [0|3] "" Vector__XXX
   SG_ ATC_ASRInformationSignal : 46|2@1+ (1,0) [0|3] "" Vector__XXX
   SG_ ABS_EBSAmberWarningSignal : 44|2@1+ (1,0) [0|3] "" Vector__XXX
   SG_ EBSRedWarningSignal : 42|2@1+ (1,0) [0|3] "" Vector__XXX
   SG_ ABSFullyOperational : 40|2@1+ (1,0) [0|3] "" Vector__XXX
   SG_ EngRetarderSelection : 32|8@1+ (0.4,0) [0|100] "%" Vector__XXX
   SG_ RemoteAccelEnableSwitch : 30|2@1+ (1,0) [0|3] "" Vector__XXX
   SG_ EngDerateSwitch : 26|2@1+ (1,0) [0|3] "" Vector__XXX
   SG_ AccelInterlockSwitch : 24|2@1+ (1,0) [0|3] "" Vector__XXX
   SG_ TractionCtrlOverrideSwitch : 22|2@1+ (1,0) [0|3] "" Vector__XXX
   SG_ ASRHillHolderSwitch : 20|2@1+ (1,0) [0|3] "" Vector__XXX
   SG_ ASROffroadSwitch : 18|2@1+ (1,0) [0|3] "" Vector__XXX
   SG_ ABSOffroadSwitch : 16|2@1+ (1,0) [0|3] "" Vector__XXX
   SG_ EBSBrakeSwitch : 6|2@1+ (1,0) [0|3] "" Vector__XXX
   SG_ AntiLockBrakingActive : 4|2@1+ (1,0) [0|3] "" Vector__XXX
   SG_ ASRBrakeCtrlActive : 2|2@1+ (1,0) [0|3] "" Vector__XXX
   SG_ ASREngCtrlActive : 0|2@1+ (1,0) [0|3] "" Vector__XXX

BO_ 2565867262 EAC1: 8 Vector__XXX
   SG_ RearAxleGroupEngagementStatus : 26|2@1+ (1,0) [0|3] "" Vector__XXX
   SG_ FrontAxleGroupEngagementStatus : 24|2@1+ (1,0) [0|3] "" Vector__XXX
   SG_ DiffLockStateCentralRear : 20|2@1+ (1,0) [0|3] "" Vector__XXX
   SG_ DiffLockStateCentralFront : 18|2@1+ (1,0) [0|3] "" Vector__XXX
   SG_ DiffLockStateCentral : 16|2@1+ (1,0) [0|3] "" Vector__XXX
   SG_ DiffLockStateRearAxle2 : 14|2@1+ (1,0) [0|3] "" Vector__XXX
   SG_ DiffLockStateRearAxle1 : 12|2@1+ (1,0) [0|3] "" Vector__XXX
   SG_ DiffLockStateFrontAxle2 : 10|2@1+ (1,0) [0|3] "" Vector__XXX
   SG_ DiffLockStateFrontAxle1 : 8|2@1+ (1,0) [0|3] "" Vector__XXX
   SG_ Location : 0|8@1+ (1,0) [0|255] "" Vector__XXX

BO_ 2566821118 EAC: 8 Vector__XXX
   SG_ SeaWaterPumpOutletPress : 16|8@1+ (2,0) [0|500] "kPa" Vector__XXX
   SG_ EngAuxCoolantTemp : 8|8@1+ (1,-40) [-40|210] "deg C" Vector__XXX
   SG_ EngAuxCoolantPress : 0|8@1+ (4,0) [0|1000] "kPa" Vector__XXX

BO_ 2566810622 DI: 8 Vector__XXX
   SG_ Driver2 : 8|8@1+ (1,0) [0|255] "" Vector__XXX
   SG_ Driver1 : 0|8@1+ (1,0) [0|255] "" Vector__XXX

BO_ 2566847742 DD: 8 Vector__XXX
   SG_ FuelLevel2 : 48|8@1+ (0.4,0) [0|100] "%" Vector__XXX
   SG_ FuelLevel1 : 8|8@1+ (0.4,0) [0|100] "%" Vector__XXX
   SG_ CargoAmbientTemp : 32|16@1+ (0.03125,-273) [-273|1734.97] "deg C" Vector__XXX
   SG_ EngOilFilterDiffPress : 24|8@1+ (0.5,0) [0|125] "kPa" Vector__XXX
   SG_ EngFuelFilterDiffPress : 16|8@1+ (2,0) [0|500] "kPa" Vector__XXX
   SG_ WasherFluidLevel : 0|8@1+ (0.4,0) [0|100] "%" Vector__XXX

BA_DEF_ SG_ "SigType" ENUM "Default","Range","RangeSigned","ASCII","Discrete","Control","ReferencePGN","DTC","StringDelimiter","StringLength","StringLengthControl";
BA_DEF_ SG_ "GenSigStartValue" INT 0 10000;
BA_DEF_ SG_ "GenSigSendType" ENUM "Default","Range","RangeSigned","ASCII","Discrete","Control","ReferencePGN","DTC","StringDelimiter","StringLength","StringLengthControl","Default","Range","RangeSigned","ASCII","Discrete","Control","ReferencePGN","DTC","StringDelimiter","StringLength","StringLengthControl","Cyclic","OnWrite","reserved","OnChange","reserved","reserved","reserved","NoSigSendType";
BA_DEF_ SG_ "GenSigILSupport" ENUM "Default","Range","RangeSigned","ASCII","Discrete","Control","ReferencePGN","DTC","StringDelimiter","StringLength","StringLengthControl","Default","Range","RangeSigned","ASCII","Discrete","Control","ReferencePGN","DTC","StringDelimiter","StringLength","StringLengthControl","Cyclic","OnWrite","reserved","OnChange","reserved","reserved","reserved","NoSigSendType","Default","Range","RangeSigned","ASCII","Discrete","Control","ReferencePGN","DTC","StringDelimiter","StringLength","StringLengthControl","Cyclic","OnWrite","reserved","OnChange","reserved","reserved","reserved","NoSigSendType","Yes","No";
BA_DEF_ SG_ "GenSigEVName" STRING ;
BA_DEF_ SG_ "SPN" INT 0 524287;
BA_DEF_ BO_ "GenMsgStartDelayTime" INT 0 100000;
BA_DEF_ BO_ "GenMsgILSupport" ENUM "Default","Range","RangeSigned","ASCII","Discrete","Control","ReferencePGN","DTC","StringDelimiter","StringLength","StringLengthControl","Default","Range","RangeSigned","ASCII","Discrete","Control","ReferencePGN","DTC","StringDelimiter","StringLength","StringLengthControl","Cyclic","OnWrite","reserved","OnChange","reserved","reserved","reserved","NoSigSendType","Default","Range","RangeSigned","ASCII","Discrete","Control","ReferencePGN","DTC","StringDelimiter","StringLength","StringLengthControl","Cyclic","OnWrite","reserved","OnChange","reserved","reserved","reserved","NoSigSendType","Yes","No","Default","Range","RangeSigned","ASCII","Discrete","Control","ReferencePGN","DTC","StringDelimiter","StringLength","StringLengthControl","Cyclic","OnWrite","reserved","OnChange","reserved","reserved","reserved","NoSigSendType","Yes","No","Yes","No";
BA_DEF_ BO_ "GenMsgRequestable" INT 0 1;
BA_DEF_ BO_ "GenMsgSendType" ENUM "Default","Range","RangeSigned","ASCII","Discrete","Control","ReferencePGN","DTC","StringDelimiter","StringLength","StringLengthControl","Default","Range","RangeSigned","ASCII","Discrete","Control","ReferencePGN","DTC","StringDelimiter","StringLength","StringLengthControl","Cyclic","OnWrite","reserved","OnChange","reserved","reserved","reserved","NoSigSendType","Default","Range","RangeSigned","ASCII","Discrete","Control","ReferencePGN","DTC","StringDelimiter","StringLength","StringLengthControl","Cyclic","OnWrite","reserved","OnChange","reserved","reserved","reserved","NoSigSendType","Yes","No","Default","Range","RangeSigned","ASCII","Discrete","Control","ReferencePGN","DTC","StringDelimiter","StringLength","StringLengthControl","Cyclic","OnWrite","reserved","OnChange","reserved","reserved","reserved","NoSigSendType","Yes","No","Yes","No","Default","Range","RangeSigned","ASCII","Discrete","Control","ReferencePGN","DTC","StringDelimiter","StringLength","StringLengthControl","Cyclic","OnWrite","reserved","OnChange","reserved","reserved","reserved","NoSigSendType","Yes","No","Yes","No","cyclic","reserved","cyclicIfActive","reserved","reserved","reserved","reserved","reserved","noMsgSendType";
BA_DEF_ BO_ "VFrameFormat" ENUM "Default","Range","RangeSigned","ASCII","Discrete","Control","ReferencePGN","DTC","StringDelimiter","StringLength","StringLengthControl","Default","Range","RangeSigned","ASCII","Discrete","Control","ReferencePGN","DTC","StringDelimiter","StringLength","StringLengthControl","Cyclic","OnWrite","reserved","OnChange","reserved","reserved","reserved","NoSigSendType","Default","Range","RangeSigned","ASCII","Discrete","Control","ReferencePGN","DTC","StringDelimiter","StringLength","StringLengthControl","Cyclic","OnWrite","reserved","OnChange","reserved","reserved","reserved","NoSigSendType","Yes","No","Default","Range","RangeSigned","ASCII","Discrete","Control","ReferencePGN","DTC","StringDelimiter","StringLength","StringLengthControl","Cyclic","OnWrite","reserved","OnChange","reserved","reserved","reserved","NoSigSendType","Yes","No","Yes","No","Default","Range","RangeSigned","ASCII","Discrete","Control","ReferencePGN","DTC","StringDelimiter","StringLength","StringLengthControl","Cyclic","OnWrite","reserved","OnChange","reserved","reserved","reserved","NoSigSendType","Yes","No","Yes","No","cyclic","reserved","cyclicIfActive","reserved","reserved","reserved","reserved","reserved","noMsgSendType","Default","Range","RangeSigned","ASCII","Discrete","Control","ReferencePGN","DTC","StringDelimiter","StringLength","StringLengthControl","Cyclic","OnWrite","reserved","OnChange","reserved","reserved","reserved","NoSigSendType","Yes","No","Yes","No","cyclic","reserved","cyclicIfActive","reserved","reserved","reserved","reserved","reserved","noMsgSendType","StandardCAN","ExtendedCAN","reserved","J1939PG";
BA_DEF_ BO_ "GenMsgCycleTime" INT 0 3;
BA_DEF_ SG_ "SystemSignalLongSymbol" STRING ;
BA_DEF_ BO_ "GenMsgBackgroundColor" STRING ;
BA_DEF_ BO_ "GenMsgForegroundColor" STRING ;
BA_DEF_ BO_ "matchingcriteria" INT 0 0;
BA_DEF_ BO_ "filterlabeling" INT 0 0;
BA_DEF_ BO_ "matchingcriteria" INT 0 0;
BA_DEF_ BO_ "filterlabeling" INT 0 0;
BA_DEF_DEF_ "SigType" "Default";
BA_DEF_DEF_ "GenSigStartValue" 0;
BA_DEF_DEF_ "GenSigSendType" "NoSigSendType";
BA_DEF_DEF_ "GenSigILSupport" "Yes";
BA_DEF_DEF_ "GenSigEVName" "Env";
BA_DEF_DEF_ "SPN" 0;
BA_DEF_DEF_ "GenMsgStartDelayTime" 0;
BA_DEF_DEF_ "GenMsgILSupport" "Yes";
BA_DEF_DEF_ "GenMsgRequestable" 1;
BA_DEF_DEF_ "GenMsgSendType" "noMsgSendType";
BA_DEF_DEF_ "VFrameFormat" "J1939PG";
BA_DEF_DEF_ "GenMsgCycleTime" 0;
BA_DEF_DEF_ "SystemSignalLongSymbol" "";
BA_DEF_DEF_ "GenMsgBackgroundColor" "#ffffff";
BA_DEF_DEF_ "GenMsgForegroundColor" "#000000";
BA_DEF_DEF_ "matchingcriteria" 1;
BA_DEF_DEF_ "filterlabeling" 0;
BA_DEF_DEF_ "matchingcriteria" 1;
BA_DEF_DEF_ "filterlabeling" 1;
BA_ "GenMsgCycleTime" BO_ 2565144318 100;
BA_ "GenMsgSendType" BO_ 2565144318 0;
BA_ "VFrameFormat" BO_ 2565144318 3;
BA_ "GenMsgCycleTime" BO_ 2565209854 100;
BA_ "GenMsgSendType" BO_ 2565209854 0;
BA_ "VFrameFormat" BO_ 2565209854 3;
BA_ "GenMsgCycleTime" BO_ 2566806782 100;
BA_ "GenMsgSendType" BO_ 2566806782 0;
BA_ "VFrameFormat" BO_ 2566806782 3;
BA_ "GenMsgCycleTime" BO_ 2566807294 1000;
BA_ "GenMsgSendType" BO_ 2566807294 0;
BA_ "VFrameFormat" BO_ 2566807294 3;
BA_ "GenMsgSendType" BO_ 2566764798 8;
BA_ "VFrameFormat" BO_ 2566764798 3;
BA_ "SystemSignalLongSymbol" SG_ 2566764798 NOxConvertingCatalystAdsorberCom "NOxConvertingCatalystAdsorberCom";
BA_ "SystemSignalLongSymbol" SG_ 2566764798 NOxConvertingCatalystAdsorberEna "NOxConvertingCatalystAdsorberEna";
BA_ "SystemSignalLongSymbol" SG_ 2566764798 BoostPressureControlSystemComple "BoostPressureControlSystemComple";
BA_ "GenMsgSendType" BO_ 2564095742 8;
BA_ "VFrameFormat" BO_ 2564095742 3;
BA_ "GenMsgCycleTime" BO_ 2349137662 20;
BA_ "GenMsgSendType" BO_ 2349137662 2;
BA_ "VFrameFormat" BO_ 2349137662 3;
BA_ "GenMsgCycleTime" BO_ 2566848510 10000;
BA_ "GenMsgSendType" BO_ 2566848510 0;
BA_ "VFrameFormat" BO_ 2566848510 3;
BA_ "GenMsgSendType" BO_ 2566843134 8;
BA_ "VFrameFormat" BO_ 2566843134 3;
BA_ "GenMsgCycleTime" BO_ 2566804222 1000;
BA_ "GenMsgSendType" BO_ 2566804222 0;
BA_ "VFrameFormat" BO_ 2566804222 3;
BA_ "GenMsgSendType" BO_ 2633928190 8;
BA_ "VFrameFormat" BO_ 2633928190 3;
BA_ "GenMsgCycleTime" BO_ 2566845438 5000;
BA_ "GenMsgSendType" BO_ 2566845438 0;
BA_ "VFrameFormat" BO_ 2566845438 3;
BA_ "GenMsgSendType" BO_ 2566843646 8;
BA_ "VFrameFormat" BO_ 2566843646 3;
BA_ "GenMsgSendType" BO_ 2566842366 8;
BA_ "VFrameFormat" BO_ 2566842366 3;
BA_ "GenMsgCycleTime" BO_ 2566809854 1000;
BA_ "GenMsgSendType" BO_ 2566809854 0;
BA_ "VFrameFormat" BO_ 2566809854 3;
BA_ "GenMsgSendType" BO_ 2566842622 8;
BA_ "VFrameFormat" BO_ 2566842622 3;
BA_ "GenMsgCycleTime" BO_ 2566832638 1000;
BA_ "GenMsgSendType" BO_ 2566832638 0;
BA_ "VFrameFormat" BO_ 2566832638 3;
BA_ "GenMsgCycleTime" BO_ 2565868030 10;
BA_ "GenMsgSendType" BO_ 2565868030 0;
BA_ "VFrameFormat" BO_ 2565868030 3;
BA_ "GenMsgCycleTime" BO_ 2566803454 100;
BA_ "GenMsgSendType" BO_ 2566803454 0;
BA_ "VFrameFormat" BO_ 2566803454 3;
BA_ "GenMsgCycleTime" BO_ 2566840574 100;
BA_ "GenMsgSendType" BO_ 2566840574 0;
BA_ "VFrameFormat" BO_ 2566840574 3;
BA_ "GenMsgSendType" BO_ 2633938686 8;
BA_ "VFrameFormat" BO_ 2633938686 3;
BA_ "GenMsgSendType" BO_ 2633937150 8;
BA_ "VFrameFormat" BO_ 2633937150 3;
BA_ "GenMsgSendType" BO_ 2633938174 8;
BA_ "VFrameFormat" BO_ 2633938174 3;
BA_ "GenMsgSendType" BO_ 2633938430 8;
BA_ "VFrameFormat" BO_ 2633938430 3;
BA_ "GenMsgSendType" BO_ 2348875518 8;
BA_ "VFrameFormat" BO_ 2348875518 3;
BA_ "GenMsgSendType" BO_ 2566766846 8;
BA_ "VFrameFormat" BO_ 2566766846 3;
BA_ "GenMsgSendType" BO_ 2566765310 8;
BA_ "VFrameFormat" BO_ 2566765310 3;
BA_ "GenMsgSendType" BO_ 2566765566 8;
BA_ "VFrameFormat" BO_ 2566765566 3;
BA_ "GenMsgSendType" BO_ 2566765822 8;
BA_ "VFrameFormat" BO_ 2566765822 3;
BA_ "GenMsgSendType" BO_ 2566766078 8;
BA_ "VFrameFormat" BO_ 2566766078 3;
BA_ "GenMsgSendType" BO_ 2566766590 8;
BA_ "VFrameFormat" BO_ 2566766590 3;
BA_ "GenMsgSendType" BO_ 2566766334 8;
BA_ "VFrameFormat" BO_ 2566766334 3;
BA_ "SystemSignalLongSymbol" SG_ 2566766334 NmbrOfBytsInTrnstAssgndBlckIdntt "NmbrOfBytsInTrnstAssgndBlckIdntt";
BA_ "GenMsgSendType" BO_ 2561605374 8;
BA_ "VFrameFormat" BO_ 2561605374 3;
BA_ "GenMsgSendType" BO_ 2566765054 8;
BA_ "VFrameFormat" BO_ 2566765054 3;
BA_ "GenMsgSendType" BO_ 2633923326 8;
BA_ "VFrameFormat" BO_ 2633923326 3;
BA_ "GenMsgSendType" BO_ 2633923070 8;
BA_ "VFrameFormat" BO_ 2633923070 3;
BA_ "GenMsgSendType" BO_ 2633922814 8;
BA_ "VFrameFormat" BO_ 2633922814 3;
BA_ "GenMsgCycleTime" BO_ 2566845694 10000;
BA_ "GenMsgSendType" BO_ 2566845694 0;
BA_ "VFrameFormat" BO_ 2566845694 3;
BA_ "GenMsgSendType" BO_ 2633939966 8;
BA_ "VFrameFormat" BO_ 2633939966 3;
BA_ "GenMsgSendType" BO_ 2633939710 8;
BA_ "VFrameFormat" BO_ 2633939710 3;
BA_ "GenMsgSendType" BO_ 2564161278 8;
BA_ "VFrameFormat" BO_ 2564161278 3;
BA_ "GenMsgSendType" BO_ 2566842110 8;
BA_ "VFrameFormat" BO_ 2566842110 3;
BA_ "GenMsgCycleTime" BO_ 2566821630 100;
BA_ "GenMsgSendType" BO_ 2566821630 0;
BA_ "VFrameFormat" BO_ 2566821630 3;
BA_ "GenMsgCycleTime" BO_ 2365484286 50;
BA_ "GenMsgSendType" BO_ 2365484286 0;
BA_ "VFrameFormat" BO_ 2365484286 3;
BA_ "GenMsgCycleTime" BO_ 2566771710 1000;
BA_ "GenMsgSendType" BO_ 2566771710 0;
BA_ "VFrameFormat" BO_ 2566771710 3;
BA_ "GenMsgCycleTime" BO_ 2566821886 1000;
BA_ "GenMsgSendType" BO_ 2566821886 0;
BA_ "VFrameFormat" BO_ 2566821886 3;
BA_ "GenMsgCycleTime" BO_ 2566822142 1000;
BA_ "GenMsgSendType" BO_ 2566822142 0;
BA_ "VFrameFormat" BO_ 2566822142 3;
BA_ "GenMsgCycleTime" BO_ 2566822398 1000;
BA_ "GenMsgSendType" BO_ 2566822398 0;
BA_ "VFrameFormat" BO_ 2566822398 3;
BA_ "GenMsgCycleTime" BO_ 2566822654 1000;
BA_ "GenMsgSendType" BO_ 2566822654 0;
BA_ "VFrameFormat" BO_ 2566822654 3;
BA_ "GenMsgCycleTime" BO_ 2633931774 1000;
BA_ "GenMsgSendType" BO_ 2633931774 0;
BA_ "VFrameFormat" BO_ 2633931774 3;
BA_ "GenMsgSendType" BO_ 2566802430 8;
BA_ "VFrameFormat" BO_ 2566802430 3;
BA_ "GenMsgSendType" BO_ 2566841086 8;
BA_ "VFrameFormat" BO_ 2566841086 3;
BA_ "GenMsgSendType" BO_ 2348941054 8;
BA_ "VFrameFormat" BO_ 2348941054 3;
BA_ "GenMsgCycleTime" BO_ 2566839806 1000;
BA_ "GenMsgSendType" BO_ 2566839806 0;
BA_ "VFrameFormat" BO_ 2566839806 3;
BA_ "GenMsgSendType" BO_ 2633911806 8;
BA_ "VFrameFormat" BO_ 2633911806 3;
BA_ "GenMsgCycleTime" BO_ 2566775550 1000;
BA_ "GenMsgSendType" BO_ 2566775550 2;
BA_ "VFrameFormat" BO_ 2566775550 3;
BA_ "GenMsgCycleTime" BO_ 2566819838 1000;
BA_ "GenMsgSendType" BO_ 2566819838 0;
BA_ "VFrameFormat" BO_ 2566819838 3;
BA_ "GenMsgSendType" BO_ 2566839038 8;
BA_ "VFrameFormat" BO_ 2566839038 3;
BA_ "GenMsgCycleTime" BO_ 2566841598 1000;
BA_ "GenMsgSendType" BO_ 2566841598 0;
BA_ "VFrameFormat" BO_ 2566841598 3;
BA_ "GenMsgSendType" BO_ 2566832382 8;
BA_ "VFrameFormat" BO_ 2566832382 3;
BA_ "GenMsgSendType" BO_ 2633928446 8;
BA_ "VFrameFormat" BO_ 2633928446 3;
BA_ "GenMsgCycleTime" BO_ 2566804478 5000;
BA_ "GenMsgSendType" BO_ 2566804478 0;
BA_ "VFrameFormat" BO_ 2566804478 3;
BA_ "SystemSignalLongSymbol" SG_ 2566804478 HghLmtThrshldFrMnCntnsTrqFrmRtrd "HghLmtThrshldFrMnCntnsTrqFrmRtrd";
BA_ "SystemSignalLongSymbol" SG_ 2566804478 HghLmtThrshldFrMnCntnsRPMFrmRtrd "HghLmtThrshldFrMnCntnsRPMFrmRtrd";
BA_ "GenMsgCycleTime" BO_ 2566847486 1000;
BA_ "GenMsgSendType" BO_ 2566847486 0;
BA_ "VFrameFormat" BO_ 2566847486 3;
BA_ "GenMsgSendType" BO_ 2631859966 8;
BA_ "VFrameFormat" BO_ 2631859966 3;
BA_ "GenMsgSendType" BO_ 2566840830 8;
BA_ "VFrameFormat" BO_ 2566840830 3;
BA_ "GenMsgSendType" BO_ 2633930238 8;
BA_ "VFrameFormat" BO_ 2633930238 3;
BA_ "GenMsgCycleTime" BO_ 2566844670 100;
BA_ "GenMsgSendType" BO_ 2566844670 0;
BA_ "VFrameFormat" BO_ 2566844670 3;
BA_ "SystemSignalLongSymbol" SG_ 2566844670 EngRmtPTOGvrnrPrprgrmmdSpdCtrlSw "EngRmtPTOGvrnrPrprgrmmdSpdCtrlSw";
BA_ "GenMsgCycleTime" BO_ 2566770174 200;
BA_ "GenMsgSendType" BO_ 2566770174 0;
BA_ "VFrameFormat" BO_ 2566770174 3;
BA_ "GenMsgCycleTime" BO_ 2566769662 500;
BA_ "GenMsgSendType" BO_ 2566769662 0;
BA_ "VFrameFormat" BO_ 2566769662 3;
BA_ "GenMsgCycleTime" BO_ 2566768638 500;
BA_ "GenMsgSendType" BO_ 2566768638 0;
BA_ "VFrameFormat" BO_ 2566768638 3;
BA_ "GenMsgSendType" BO_ 2365443326 8;
BA_ "VFrameFormat" BO_ 2365443326 3;
BA_ "GenMsgCycleTime" BO_ 2566776318 1000;
BA_ "GenMsgSendType" BO_ 2566776318 0;
BA_ "VFrameFormat" BO_ 2566776318 3;
BA_ "GenMsgCycleTime" BO_ 2566802686 500;
BA_ "GenMsgSendType" BO_ 2566802686 0;
BA_ "VFrameFormat" BO_ 2566802686 3;
BA_ "GenMsgCycleTime" BO_ 2566774014 1000;
BA_ "GenMsgSendType" BO_ 2566774014 0;
BA_ "VFrameFormat" BO_ 2566774014 3;
BA_ "GenMsgCycleTime" BO_ 2566823166 1000;
BA_ "GenMsgSendType" BO_ 2566823166 0;
BA_ "VFrameFormat" BO_ 2566823166 3;
BA_ "GenMsgCycleTime" BO_ 2566823422 1000;
BA_ "GenMsgSendType" BO_ 2566823422 0;
BA_ "VFrameFormat" BO_ 2566823422 3;
BA_ "GenMsgCycleTime" BO_ 2566823678 1000;
BA_ "GenMsgSendType" BO_ 2566823678 0;
BA_ "VFrameFormat" BO_ 2566823678 3;
BA_ "GenMsgCycleTime" BO_ 2432595710 100;
BA_ "GenMsgSendType" BO_ 2432595710 0;
BA_ "VFrameFormat" BO_ 2432595710 3;
BA_ "GenMsgCycleTime" BO_ 2365486590 50;
BA_ "GenMsgSendType" BO_ 2365486590 0;
BA_ "VFrameFormat" BO_ 2365486590 3;
BA_ "GenMsgCycleTime" BO_ 2365485566 50;
BA_ "GenMsgSendType" BO_ 2365485566 0;
BA_ "VFrameFormat" BO_ 2365485566 3;
BA_ "GenMsgSendType" BO_ 2633939454 8;
BA_ "VFrameFormat" BO_ 2633939454 3;
BA_ "GenMsgCycleTime" BO_ 2365486334 50;
BA_ "GenMsgSendType" BO_ 2365486334 0;
BA_ "VFrameFormat" BO_ 2365486334 3;
BA_ "GenMsgCycleTime" BO_ 2364542462 100;
BA_ "GenMsgSendType" BO_ 2364542462 0;
BA_ "VFrameFormat" BO_ 2364542462 3;
BA_ "GenMsgCycleTime" BO_ 2365486078 50;
BA_ "GenMsgSendType" BO_ 2365486078 0;
BA_ "VFrameFormat" BO_ 2365486078 3;
BA_ "GenMsgSendType" BO_ 2633937918 8;
BA_ "VFrameFormat" BO_ 2633937918 3;
BA_ "GenMsgCycleTime" BO_ 2566845182 100;
BA_ "GenMsgSendType" BO_ 2566845182 0;
BA_ "VFrameFormat" BO_ 2566845182 3;
BA_ "GenMsgSendType" BO_ 2566842878 8;
BA_ "VFrameFormat" BO_ 2566842878 3;
BA_ "GenMsgCycleTime" BO_ 2633883646 500;
BA_ "GenMsgSendType" BO_ 2633883646 0;
BA_ "VFrameFormat" BO_ 2633883646 3;
BA_ "GenMsgCycleTime" BO_ 2633880062 10000;
BA_ "GenMsgSendType" BO_ 2633880062 0;
BA_ "VFrameFormat" BO_ 2633880062 3;
BA_ "GenMsgCycleTime" BO_ 2566806526 100;
BA_ "GenMsgSendType" BO_ 2566806526 0;
BA_ "VFrameFormat" BO_ 2566806526 3;
BA_ "GenMsgCycleTime" BO_ 2431649790 50;
BA_ "GenMsgSendType" BO_ 2431649790 2;
BA_ "VFrameFormat" BO_ 2431649790 3;
BA_ "GenMsgCycleTime" BO_ 2633929214 1000;
BA_ "GenMsgSendType" BO_ 2633929214 0;
BA_ "VFrameFormat" BO_ 2633929214 3;
BA_ "GenMsgCycleTime" BO_ 2566831614 1000;
BA_ "GenMsgSendType" BO_ 2566831614 0;
BA_ "VFrameFormat" BO_ 2566831614 3;
BA_ "GenMsgSendType" BO_ 2566820094 8;
BA_ "VFrameFormat" BO_ 2566820094 3;
BA_ "GenMsgCycleTime" BO_ 2364542206 20;
BA_ "GenMsgSendType" BO_ 2364542206 0;
BA_ "VFrameFormat" BO_ 2364542206 3;
BA_ "GenMsgCycleTime" BO_ 2566802174 100;
BA_ "GenMsgSendType" BO_ 2566802174 0;
BA_ "VFrameFormat" BO_ 2566802174 3;
BA_ "GenMsgSendType" BO_ 2633935870 8;
BA_ "VFrameFormat" BO_ 2633935870 3;
BA_ "GenMsgSendType" BO_ 2633942014 8;
BA_ "VFrameFormat" BO_ 2633942014 3;
BA_ "GenMsgSendType" BO_ 2633942526 8;
BA_ "VFrameFormat" BO_ 2633942526 3;
BA_ "GenMsgSendType" BO_ 2633943038 8;
BA_ "VFrameFormat" BO_ 2633943038 3;
BA_ "GenMsgCycleTime" BO_ 2565867006 100;
BA_ "GenMsgSendType" BO_ 2565867006 0;
BA_ "VFrameFormat" BO_ 2565867006 3;
BA_ "GenMsgCycleTime" BO_ 2364539646 10;
BA_ "GenMsgSendType" BO_ 2364539646 0;
BA_ "VFrameFormat" BO_ 2364539646 3;
BA_ "GenMsgCycleTime" BO_ 2566810110 1000;
BA_ "GenMsgSendType" BO_ 2566810110 0;
BA_ "VFrameFormat" BO_ 2566810110 3;
BA_ "GenMsgCycleTime" BO_ 2566825214 1000;
BA_ "GenMsgSendType" BO_ 2566825214 0;
BA_ "VFrameFormat" BO_ 2566825214 3;
BA_ "GenMsgCycleTime" BO_ 2566844158 1000;
BA_ "GenMsgSendType" BO_ 2566844158 0;
BA_ "VFrameFormat" BO_ 2566844158 3;
BA_ "GenMsgCycleTime" BO_ 2566785022 500;
BA_ "GenMsgSendType" BO_ 2566785022 0;
BA_ "VFrameFormat" BO_ 2566785022 3;
BA_ "GenMsgCycleTime" BO_ 2565868542 20;
BA_ "GenMsgSendType" BO_ 2565868542 0;
BA_ "VFrameFormat" BO_ 2565868542 3;
BA_ "GenMsgCycleTime" BO_ 2633941758 1000;
BA_ "GenMsgSendType" BO_ 2633941758 2;
BA_ "VFrameFormat" BO_ 2633941758 3;
BA_ "GenMsgCycleTime" BO_ 2565865726 100;
BA_ "GenMsgSendType" BO_ 2565865726 0;
BA_ "VFrameFormat" BO_ 2565865726 3;
BA_ "SystemSignalLongSymbol" SG_ 2565865726 SrcAddrssOfCtrllngDvcFrRtrdrCntr "SrcAddrssOfCtrllngDvcFrRtrdrCntr";
BA_ "GenMsgCycleTime" BO_ 2633932798 1000;
BA_ "GenMsgSendType" BO_ 2633932798 0;
BA_ "VFrameFormat" BO_ 2633932798 3;
BA_ "GenMsgCycleTime" BO_ 2566824190 1000;
BA_ "GenMsgSendType" BO_ 2566824190 0;
BA_ "VFrameFormat" BO_ 2566824190 3;
BA_ "GenMsgCycleTime" BO_ 2633933310 1000;
BA_ "GenMsgSendType" BO_ 2633933310 0;
BA_ "VFrameFormat" BO_ 2633933310 3;
BA_ "GenMsgCycleTime" BO_ 2633933566 1000;
BA_ "GenMsgSendType" BO_ 2633933566 0;
BA_ "VFrameFormat" BO_ 2633933566 3;
BA_ "GenMsgCycleTime" BO_ 2633933822 1000;
BA_ "GenMsgSendType" BO_ 2633933822 0;
BA_ "VFrameFormat" BO_ 2633933822 3;
BA_ "GenMsgCycleTime" BO_ 2566776062 500;
BA_ "GenMsgSendType" BO_ 2566776062 0;
BA_ "VFrameFormat" BO_ 2566776062 3;
BA_ "GenMsgSendType" BO_ 2566771454 8;
BA_ "VFrameFormat" BO_ 2566771454 3;
BA_ "GenMsgCycleTime" BO_ 2566775806 250;
BA_ "GenMsgSendType" BO_ 2566775806 0;
BA_ "VFrameFormat" BO_ 2566775806 3;
BA_ "GenMsgSendType" BO_ 2633935358 8;
BA_ "VFrameFormat" BO_ 2633935358 3;
BA_ "GenMsgCycleTime" BO_ 2365447166 100;
BA_ "GenMsgSendType" BO_ 2365447166 0;
BA_ "VFrameFormat" BO_ 2365447166 3;
BA_ "SystemSignalLongSymbol" SG_ 2365447166 Jystck3ThtAxsCntrClckwsNgtvPsStt "Jystck3ThtAxsCntrClckwsNgtvPsStt";
BA_ "GenMsgCycleTime" BO_ 2365446654 100;
BA_ "GenMsgSendType" BO_ 2365446654 0;
BA_ "VFrameFormat" BO_ 2365446654 3;
BA_ "SystemSignalLongSymbol" SG_ 2365446654 Jystck2ThtAxsCntrClckwsNgtvPsStt "Jystck2ThtAxsCntrClckwsNgtvPsStt";
BA_ "GenMsgCycleTime" BO_ 2365446142 100;
BA_ "GenMsgSendType" BO_ 2365446142 0;
BA_ "VFrameFormat" BO_ 2365446142 3;
BA_ "SystemSignalLongSymbol" SG_ 2365446142 Jystck1ThtAxsCntrClckwsNgtvPsStt "Jystck1ThtAxsCntrClckwsNgtvPsStt";
BA_ "GenMsgCycleTime" BO_ 2633929470 100;
BA_ "GenMsgSendType" BO_ 2633929470 0;
BA_ "VFrameFormat" BO_ 2633929470 3;
BA_ "GenMsgSendType" BO_ 2633937406 8;
BA_ "VFrameFormat" BO_ 2633937406 3;
BA_ "GenMsgCycleTime" BO_ 2364541694 50;
BA_ "GenMsgSendType" BO_ 2364541694 0;
BA_ "VFrameFormat" BO_ 2364541694 3;
BA_ "GenMsgCycleTime" BO_ 2566810366 500;
BA_ "GenMsgSendType" BO_ 2566810366 0;
BA_ "VFrameFormat" BO_ 2566810366 3;
BA_ "GenMsgCycleTime" BO_ 2566767102 500;
BA_ "GenMsgSendType" BO_ 2566767102 0;
BA_ "VFrameFormat" BO_ 2566767102 3;
BA_ "GenMsgCycleTime" BO_ 2566839294 500;
BA_ "GenMsgSendType" BO_ 2566839294 0;
BA_ "VFrameFormat" BO_ 2566839294 3;
BA_ "GenMsgCycleTime" BO_ 2566844414 500;
BA_ "GenMsgSendType" BO_ 2566844414 0;
BA_ "VFrameFormat" BO_ 2566844414 3;
BA_ "GenMsgCycleTime" BO_ 2633929726 100;
BA_ "GenMsgSendType" BO_ 2633929726 0;
BA_ "VFrameFormat" BO_ 2633929726 3;
BA_ "GenMsgSendType" BO_ 2566772222 8;
BA_ "VFrameFormat" BO_ 2566772222 3;
BA_ "GenMsgSendType" BO_ 2633940734 8;
BA_ "VFrameFormat" BO_ 2633940734 3;
BA_ "GenMsgCycleTime" BO_ 2566840318 250;
BA_ "GenMsgSendType" BO_ 2566840318 0;
BA_ "VFrameFormat" BO_ 2566840318 3;
BA_ "SystemSignalLongSymbol" SG_ 2566840318 EngsDsrdOprtngSpdAsymmtryAdjstmn "EngsDsrdOprtngSpdAsymmtryAdjstmn";
BA_ "GenMsgCycleTime" BO_ 2364539902 50;
BA_ "GenMsgSendType" BO_ 2364539902 0;
BA_ "VFrameFormat" BO_ 2364539902 3;
BA_ "GenMsgCycleTime" BO_ 2364540158 100;
BA_ "GenMsgSendType" BO_ 2364540158 0;
BA_ "VFrameFormat" BO_ 2364540158 3;
BA_ "GenMsgSendType" BO_ 2566768126 8;
BA_ "VFrameFormat" BO_ 2566768126 3;
BA_ "GenMsgCycleTime" BO_ 2566804734 5000;
BA_ "GenMsgSendType" BO_ 2566804734 0;
BA_ "VFrameFormat" BO_ 2566804734 3;
BA_ "SystemSignalLongSymbol" SG_ 2566804734 EngHghLmtThrshldFrMnCntnsTrqFrmE "EngHghLmtThrshldFrMnCntnsTrqFrmE";
BA_ "GenMsgSendType" BO_ 2566841342 8;
BA_ "VFrameFormat" BO_ 2566841342 3;
BA_ "GenMsgCycleTime" BO_ 2566767870 100;
BA_ "GenMsgSendType" BO_ 2566767870 0;
BA_ "VFrameFormat" BO_ 2566767870 3;
BA_ "GenMsgSendType" BO_ 2633936126 8;
BA_ "VFrameFormat" BO_ 2633936126 3;
BA_ "GenMsgCycleTime" BO_ 2566827518 100;
BA_ "GenMsgSendType" BO_ 2566827518 0;
BA_ "VFrameFormat" BO_ 2566827518 3;
BA_ "GenMsgCycleTime" BO_ 2566832126 100;
BA_ "GenMsgSendType" BO_ 2566832126 0;
BA_ "VFrameFormat" BO_ 2566832126 3;
BA_ "GenMsgCycleTime" BO_ 2565865982 100;
BA_ "GenMsgSendType" BO_ 2565865982 0;
BA_ "VFrameFormat" BO_ 2565865982 3;
BA_ "GenMsgCycleTime" BO_ 2565867262 500;
BA_ "GenMsgSendType" BO_ 2565867262 0;
BA_ "VFrameFormat" BO_ 2565867262 3;
BA_ "GenMsgCycleTime" BO_ 2566821118 500;
BA_ "GenMsgSendType" BO_ 2566821118 0;
BA_ "VFrameFormat" BO_ 2566821118 3;
BA_ "GenMsgSendType" BO_ 2566810622 8;
BA_ "VFrameFormat" BO_ 2566810622 3;
BA_ "GenMsgCycleTime" BO_ 2566847742 1000;
BA_ "GenMsgSendType" BO_ 2566847742 0;
BA_ "VFrameFormat" BO_ 2566847742 3;
VAL_ 2565144318 StopLevelChangeReq 3 "Take no action" 1 "Stop request" 0 "No stop request";
VAL_ 2565144318 RampLevelStorageReq 3 "Take no action" 1 "Store ramp level 2" 0 "Store ramp level 1";
VAL_ 2565144318 LevelControlReq 3 "Take no action" 1 "Enable level control" 0 "Disable level control";
VAL_ 2565144318 RampLevelReq 3 "Take no action" 1 "Ramp level 2" 0 "Ramp level 1";
VAL_ 2565144318 SteeringAxleLockingReq 3 "Take no action" 1 "Lock steering axle" 0 "Unlock steering axle";
VAL_ 2565144318 LiftAxle2PositionReq 3 "Take no action" 1 "Position up / tag axle unladen" 0 "Position down / tag axle laden";
VAL_ 2565144318 LiftAxle1PositionReq 3 "Don't care/take no action" 2 "Reserved" 1 "Position up / tag axle unladen" 0 "Position down / tag axle laden";
VAL_ 2565144318 TractionHelpReq 3 "Take no action" 1 "Traction help request" 0 "No traction help request";
VAL_ 2565144318 LevelChangeReqRearAxle 2 "Take no action" 1 "Vehicle body down (lowering)" 0 "Vehicle body up (lifting)";
VAL_ 2565144318 LevelChangeReqFrontAxle 2 "Take no action" 1 "Vehicle body down (lowering)" 0 "Vehicle body up (lifting)";
VAL_ 2565144318 RideHeightRequest 2 "Take no action" 1 "Normal level 2" 0 "Normal level 1";
VAL_ 2565209854 LevelControl 1 "Level control enabled" 0 "Level control disabled";
VAL_ 2565209854 RampLevel 1 "Body at requested ramp level" 0 "Body not at requested ramp level";
VAL_ 2565209854 NormalLevel 3 "Not available" 1 "Normal level 2" 0 "Normal level 1";
VAL_ 2565209854 StopLevelChangeAcknowledge 1 "Level change stopped" 0 "No stop request";
VAL_ 2565209854 LevelChangeRearAxle 1 "Body lifting/lowering active" 0 "Body lifting/lowering not active";
VAL_ 2565209854 LevelChangeFrontAxle 1 "Body lifting/lowering active" 0 "Body lifting/lowering not active";
VAL_ 2565209854 RampLevelStorage 1 "New ramp level stored" 0 "No new storage request";
VAL_ 2565209854 SteeringAxleLocking 1 "Steering axle locked" 0 "Steering axle unlocked";
VAL_ 2565209854 LiftAxle2Pos 3 "NotAvailable" 2 "Error" 1 "LiftAxlePosUp_TagAxleUnladen" 0 "LiftAxlePosDown_TagAxleLaden";
VAL_ 2565209854 LiftAxle1Pos 3 "NotAvailable" 2 "Error" 1 "LiftAxlePosUp_TagAxleUnladen" 0 "LiftAxlePosDown_TagAxleLaden";
VAL_ 2565209854 RampLevelPosition 3 "Not available" 1 "Ramp level 2" 0 "Ramp level 1";
VAL_ 2565209854 TractionHelp 1 "Traction help active" 0 "Traction help inactive";
VAL_ 2565209854 LevelCtrlSysRideHeightLevel 1 "Vehicle body at requested level" 0 "Vehicle body not at req. level";
VAL_ 2566807294 TyrePressThresholdDetect 7 "Not available" 6 "Error indicator" 5 "Not defined" 4 "Extreme under pressure" 3 "Under pressure" 2 "No warning pressure" 1 "Over pressure" 0 "Extreme over pressure";
VAL_ 2566807294 TyreModulePowerSupply 1 "Sufficient power supply" 0 "Insufficient power supply";
VAL_ 2566807294 TyreWheelIdentification2 15 "Axle position 15" 14 "Axle position 14" 13 "Axle position 13" 12 "Axle position 12" 11 "Axle position 11" 10 "Axle position 10" 9 "Axle position 9" 8 "Axle position 8" 7 "Axle position 7" 6 "Axle position 6" 5 "Axle position 5" 4 "Axle position 4" 3 "Axle position 3" 2 "Axle position 2" 1 "Axle position 1" 0 "Axle position not identified";
VAL_ 2566807294 TyreWheelIdentification1 15 "Wheel position 15" 14 "Wheel position 14" 13 "Wheel position 13" 12 "Wheel position 12" 11 "Wheel position 11" 10 "Wheel position 10" 9 "Wheel position 9" 8 "Wheel position 8" 7 "Wheel position 7" 6 "Wheel position 6" 5 "Wheel position 5" 4 "Wheel position 4" 3 "Wheel position 3" 2 "Wheel position 2" 1 "Wheel position 1" 0 "Wheel position not identified";
VAL_ 2566764798 NMHCConvertingCatalystCompleted 1 "NotCompleteCycle" 0 "CompleteCycleOrNotSupported";
VAL_ 2566764798 NMHCConvertingCatalystEnabled 1 "EnabledForCycle" 0 "DisabledForRestOfCycle";
VAL_ 2566764798 NOxConvertingCatalystAdsorberCom 1 "NotCompleteCycle" 0 "CompleteCycleOrNotSupported";
VAL_ 2566764798 NOxConvertingCatalystAdsorberEna 1 "EnabledForCycle" 0 "DisabledForRestOfCycle";
VAL_ 2566764798 DieselParticulateFilterCompleted 1 "NotCompleteCycle" 0 "CompleteCycleOrNotSupported";
VAL_ 2566764798 DieselParticulateFilterEnabled 1 "EnabledForCycle" 0 "DisabledForRestOfCycle";
VAL_ 2566764798 BoostPressureControlSystemComple 1 "NotCompleteCycle" 0 "CompleteCycleOrNotSupported";
VAL_ 2566764798 BoostPressureCtrlSystemEnabled 1 "EnabledForCycle" 0 "DisabledForRestOfCycle";
VAL_ 2566764798 MisfireMonitoringComplete 1 "EnabledForCycle" 0 "DisabledForRestOfCycle";
VAL_ 2566764798 MisfireMonitoringEnabled 1 "EnabledForCycle" 0 "DisabledForRestOfCycle";
VAL_ 2566764798 FuelSystemMonitoringEnabled 1 "NotCompleteCycle" 0 "CompleteCycleOrNotSupported";
VAL_ 2566764798 ComprehensiveComptMonComplete 1 "NotCompleteCycle" 0 "CompleteCycleOrNotSupported";
VAL_ 2566764798 ComprehensiveCompMonEnabled 1 "NotCompleteCycle" 0 "CompleteCycleOrNotSupported";
VAL_ 2566764798 SecondAirSystemMonComplete 1 "EnabledForCycle" 0 "DisabledForRestOfCycle";
VAL_ 2566764798 SecondAirSystemMonEnabled 1 "EnabledForCycle" 0 "DisabledForRestOfCycle";
VAL_ 2566764798 OxygenSensorMonComplete 1 "EnabledForCycle" 0 "DisabledForRestOfCycle";
VAL_ 2566764798 OxygenSensorMonEnabled 1 "NotCompleteCycle" 0 "CompleteCycleOrNotSupported";
VAL_ 2566764798 OxygenSensorHeaterMonComplete 1 "EnabledForCycle" 0 "DisabledForRestOfCycle";
VAL_ 2566764798 OxygenSensorHeaterMonEnabled 1 "NotCompleteCycle" 0 "CompleteCycleOrNotSupported";
VAL_ 2566764798 HeatedCatalystMonComplete 1 "EnabledForCycle" 0 "DisabledForRestOfCycle";
VAL_ 2566764798 HeatedCatalystMonEnabled 1 "EnabledForCycle" 0 "DisabledForRestOfCycle";
VAL_ 2566764798 EvaporativeSystemMonComplete 1 "NotCompleteCycle" 0 "CompleteCycleOrNotSupported";
VAL_ 2566764798 EvaporativeSystemMonEnabled 1 "NotCompleteCycle" 0 "CompleteCycleOrNotSupported";
VAL_ 2566764798 EGRSystemMonitoringComplete 1 "NotCompleteCycle" 0 "CompleteCycleOrNotSupported";
VAL_ 2566764798 EGRSystemMonitoringEnabled 1 "EnabledForCycle" 0 "DisabledForRestOfCycle";
VAL_ 2566764798 ColdStartAidSystemMonComplete 1 "NotCompleteCycle" 0 "CompleteCycleOrNotSupported";
VAL_ 2566764798 ColdStartAidSystemMonEnabled 1 "EnabledForCycle" 0 "DisabledForRestOfCycle";
VAL_ 2566764798 CatalystMonComplete 1 "NotCompleteCycle" 0 "CompleteCycleOrNotSupported";
VAL_ 2566764798 CatalystMonEnabled 1 "NotCompleteCycle" 0 "CompleteCycleOrNotSupported";
VAL_ 2566764798 ACSystemRefrigerantMonComplete 1 "NotCompleteCycle" 0 "CompleteCycleOrNotSupported";
VAL_ 2566764798 ACSystemRefrigerantMonEnabled 1 "NotCompleteCycle" 0 "CompleteCycleOrNotSupported";
VAL_ 2566764798 FuelSystemMonitoringComplete 1 "NotCompleteCycle" 0 "CompleteCycleOrNotSupported";
VAL_ 2564095742 SecurityEntityType 3 "Data is Certificate" 2 "Data is Session Key" 1 "Data is Long Key" 0 "Data is Long Seed";
VAL_ 2349137662 XBRCtrlMode 3 "NotDefined" 2 "AccelerationControlWithMaxMode" 1 "AccelerationControlWithAddMode" 0 "OverrideDisabled";
VAL_ 2349137662 XBRPriority 3 "LwPrrtyUsdInOvrrdDsbldXBRCtrlMd" 2 "MdmPrrtyUsdFrACCSystmsThsMdDsNt" 1 "HighPriorityNotDefined" 0 "HghstPrrtyUsdFrEmrgncySttnsEgFr";
VAL_ 2349137662 XBREBIMode 3 "NotDefined" 2 "EndranceBrakeIntegrationAllowed" 1 "OnlyEnduranceBrakesAllowed" 0 "NEndrnceBrakeIntegrationAllowed";
VAL_ 2349137662 XBRUrgency 4 "LwRtrdrDynmcsShllBFllyCmpnstdBy" 0 "SttnNtCrtclLwRtrdrDynmcsArTlrtd";
VAL_ 2566848510 WaterInFuelIndicator 3 "NotAvailable" 2 "Error" 1 "Yes" 0 "No";
VAL_ 2566843134 AxleLocation 48 "Axle3_Position0" 32 "Axle2_Position0" 16 "Axle1_Position0" 0 "Axle0_Position0";
VAL_ 2566809854 WinchOilPressSwitch 3 "NotAvailable" 2 "ErrrSwtchStteCannotBeDetermined" 1 "OKOilPressIsAboveMin" 0 "NOTOKOilPressIsTooLow";
VAL_ 2566809854 HydOilFilterRestrictionSwitch 3 "NotAvailable" 2 "Error" 1 "RestrictionExistsOnOilFilter" 0 "NoRestriction";
VAL_ 2565868030 SteerWheelAngleSensorType 3 "NotAvailable" 2 "Reserved" 1 "AbsMeasuringPrinciple" 0 "RelativeMeasuringPrinciple";
VAL_ 2566803454 YCBrakeCtrlActive 3 "DontCare_TakeNoAction" 2 "Reserved" 1 "YCBrakeCtrlActive" 0 "YCBrakeCtrlPassiveButInstalled";
VAL_ 2566803454 YCEngCtrlActive 3 "DontCare_TakeNoAction" 2 "Reserved" 1 "YCEngCtrlActive" 0 "YCEngCtrlPassiveButInstalled";
VAL_ 2566803454 ROPBrakeCtrlActive 3 "DontCare_TakeNoAction" 2 "Reserved" 1 "ROPBrakeCtrlActive" 0 "ROPBrakeCtrlPassiveButInstalled";
VAL_ 2566803454 ROPEngCtrlActive 3 "DontCare_TakeNoAction" 2 "Reserved" 1 "ROPEngCtrlActive" 0 "ROPEngCtrlPassiveButInstalled";
VAL_ 2566803454 VDCBrakeLightRq 3 "DontCare_TakeNoAction" 2 "Reserved" 1 "TurnBrakeLightOn" 0 "TurnBrakeLightNotOn";
VAL_ 2566803454 VDCFullyOperational 3 "DontCare_TakeNoAction" 2 "Reserved" 1 "FullyOperational" 0 "NotFullyOperational";
VAL_ 2566803454 VDCInformationSignal 3 "DontCare_TakeNoAction" 2 "Reserved" 1 "On" 0 "Off";
VAL_ 2348875518 MessageCounter 14 "Reserved" 13 "Reserved" 12 "Reserved" 11 "Reserved" 10 "Reserved" 9 "Reserved" 8 "Reserved" 15 "Not Available";
VAL_ 2348875518 ControlPurpose 5 "TemporaryPowerTrainControl" 4 "EngineProtection" 3 "RoadSpeedGovernor" 2 "PTOGovernor" 1 "CruiseControl" 0 "AcceleratorPedal";
VAL_ 2348875518 TransmissionRate 7 "UseStandardRate" 6 "25ms" 5 "50ms" 4 "100ms" 3 "250ms" 2 "500ms" 1 "750ms" 0 "1000ms";
VAL_ 2348875518 OverrideCtrlModePriority 3 "LowPriority" 2 "MdmPrrtyUsdFrPwrtrnCtrlOprtnsWh" 1 "HighPriority" 0 "HghstPrrtyUsdFrSttnsThtRqrImmdt";
VAL_ 2348875518 EngRqedSpeedCtrlConditions 2 "ThsCtrlCndtnHsBnOptmzdTMnmzRpmO" 3 "StbltyOptmzdFrDrvlnEnggdAnd_OrI" 1 "StbltyOptmzdFrDrvlnDsnggdAndNnl" 0 "ThsSpdGvrnrGnSlctnIsAdjstdTPrvd";
VAL_ 2348875518 EngOverrideCtrlMode 3 "Spd_TrqLmtCtrlLmtSpdAnd_OrTrqBs" 2 "TrqCtrlCntrlTrqTInclddDsrdTrqVl" 1 "SpdCtrlGvrnSpdTInclddDsrdSpdVle" 0 "OvrrdDsbldDsblAnyExstngCtrlCmdd";
VAL_ 2348875518 MessageChecksum 15 "Not Available";
VAL_ 2348875518 EngineRequestedTorqueHiRes 15 "Not Available" 14 "Not Available" 13 "Not Available" 12 "Not Available" 11 "Not Available" 10 "Not Available" 9 "Not Available" 8 "Not Available";
VAL_ 2566766846 TransitRunStatus 3 "NotAvailable" 2 "ErrorCondition" 1 "On" 0 "Off";
VAL_ 2566766846 VehicleUseStatus 3 "NotAvailable" 2 "ErrorCondition" 1 "UnauthorizedUse" 0 "NormalUse";
VAL_ 2566766846 SilentAlarmStatus 3 "NotAvailable" 2 "ErrorCondition" 1 "On" 0 "Off";
VAL_ 2566766846 TypeOfPassengerCount 1 "BoardingPassenger" 0 "AbsPassengerCount" 4 "Exiting Passenger (second passenger stream)" 3 "Boarding Passenger (second passenger stream)" 2 "Exiting Passenger";
VAL_ 2566765310 FareboxAlarmIdentifier 97 "1111111AgencyDefined" 26 "1100000ReservedToBeAssigned" 25 "MaintenanceAccessOutOfService" 24 "MntnncAccssInSrvcCnsdrdAnAlrmCn" 23 "PaperCurrencyJamCleared" 22 "PaperCurrencyJam" 21 "Pass_TransferJamCleared" 20 "Pass_TransferJam" 19 "FareboxResetToAutomaticMode" 18 "FareboxSetInManualBypass" 17 "CoinDejamOperated" 16 "Card_PassBoxFull" 15 "Card_PassBoxLessThan75Full" 14 "Card_PassBox75Full" 13 "CurrencyBoxFull" 12 "CurrencyBoxLessThan75Full" 11 "CurrencyBox75Full" 10 "CoinboxFull" 9 "Coinbox75Full" 8 "InsufficientFareAccepted" 7 "CshbxOpndInSrvcCnsdrdAnAlrmCndt" 6 "CashboxDoorTimeout" 5 "CashboxRestored" 4 "CashboxRemoved" 3 "ProbeCompleted" 2 "ProbeStarted" 1 "VoltageRestored" 0 "VoltageDropout";
VAL_ 2566765310 FareboxEmergencyStatus 3 "NotAvailable" 2 "ErrorCondition" 1 "EmergencyCondition" 0 "NonemergencyCondition";
VAL_ 2566765566 TransferType 6 "11111AgencyDefined" 5 "Out" 4 "In" 3 "West" 2 "East" 1 "South" 0 "North";
VAL_ 2566765566 TypeOfService 2 "111AgencyDefined" 1 "ExpressService" 0 "LocalService";
VAL_ 2566765566 PaymentDetails 11 "1111AgencyDefined" 6 "1010ReservedForAssignment" 5 "Card" 4 "Pass" 3 "Ticket" 2 "Token" 1 "Cash" 0 "NotAnUpgrade";
VAL_ 2566765566 TypeOfFare 11 "1111AgencyDefined" 7 "1010ReservedForAssignment" 6 "PassB" 5 "PassA" 4 "TicketB" 3 "TicketA" 2 "TokenB" 1 "TokenA" 0 "Cash_NoDetail";
VAL_ 2566765566 TransactionType 12 "1111AgencyDefined" 8 "1011ReservedForAssignment" 7 "Free" 6 "Transfer" 5 "Permit" 4 "Card" 3 "Pass" 2 "Ticket" 1 "Token" 0 "Cash";
VAL_ 2566765822 DriversFareboxSecurityCode 1 "SecurityCode" 0 "Farebox is in reporting status";
VAL_ 2566765822 FarePresets 16 "to11111111ReservedForAssignment" 0 "to00001111AgencyDefined";
VAL_ 2566765822 TripDirection 6 "1111AgencyDefined" 5 "Out" 4 "In" 3 "West" 2 "East" 1 "South" 0 "North";
VAL_ 2566765822 TripStatus 6 "LayoverEnd" 5 "LayoverStart" 2 "TripEnd" 1 "TripStart" 7 "Undefined";
VAL_ 2566765822 FareboxServiceStatus 3 "NotAvailable" 2 "ErrorCondition" 1 "FareboxInService" 0 "FareboxOutOfService";
VAL_ 2566766078 StrobeActivationCtrlStatus 3 "NotAvailable" 2 "ErrorCondition" 1 "ActivateStrobe" 0 "DeactivateStrobe";
VAL_ 2566766078 TransitDoorEnable 3 "NotAvailable" 2 "ErrorCondition" 1 "TrnstDrSttsWllOvrrdStrbActvtion" 0 "IgnoreTransitDoorStatus";
VAL_ 2566766078 PriorityOfRespSentByEmitter 15 "NotAvailable" 14 "ErrorCondition" 12 "to1101Reserved" 11 "PrrtyStByHardwareToHighPriority" 10 "PrrtyStByHrdwareToProbePriority" 9 "PrrtySetByHardwareToLowPriority" 4 "to1000Reserved" 3 "HighPriority" 2 "ProbePriority" 1 "LowPriority" 0 "Reserved";
VAL_ 2566766078 IntersectionPreemptionRq_Resp 3 "NotAvailable" 2 "ErrorCondition" 1 "MessageIsARespFromEmitter" 0 "MessageIsARqDirectedToEmitter";
VAL_ 2566766078 TransitRouteIDUsage 3 "NotAvailable" 2 "ErrorCondition" 1 "TrnstRtIDUsedForInterleavedData" 0 "TrnstRtIDNtUsdFrInterleavedData";
VAL_ 2566766078 RangeCodeEnable 3 "NotAvailable" 2 "ErrorCondition" 1 "RangeCodeUsedForInterleavedData" 0 "RngCdeNotUsedForInterleavedData";
VAL_ 2561605374 TireLocation 51 "Axle3_Position3" 50 "Axle3_Position2" 49 "Axle3_Position1" 35 "Axle2_Position3" 34 "Axle2_Position2" 33 "Axle2_Position1" 19 "Axle1_Position3" 18 "Axle1_Position2" 17 "Axle1_Position1" 1 "Axle0_Position1" 48 "Axle3_Position0" 32 "Axle2_Position0" 16 "Axle1_Position0" 0 "Axle0_Position0";
VAL_ 2566765054 TireLocation 51 "Axle3_Position3" 50 "Axle3_Position2" 49 "Axle3_Position1" 35 "Axle2_Position3" 34 "Axle2_Position2" 33 "Axle2_Position1" 19 "Axle1_Position3" 18 "Axle1_Position2" 17 "Axle1_Position1" 1 "Axle0_Position1" 48 "Axle3_Position0" 32 "Axle2_Position0" 16 "Axle1_Position0" 0 "Axle0_Position0";
VAL_ 2633922814 PCUSupplySolenoidStatus 3 "NotAvailable" 2 "Error" 1 "On" 0 "Off";
VAL_ 2633922814 PCUCtrlSolenoidStatus 3 "NotAvailable" 2 "Error" 1 "On" 0 "Off";
VAL_ 2633922814 PCUDeflateSolenoidStatus 3 "NotAvailable" 2 "Error" 1 "On" 0 "Off";
VAL_ 2633922814 TirePressSupplySwitchStatus 3 "NotAvailable" 2 "Error" 1 "On" 0 "Off";
VAL_ 2633922814 PCUSteerSolenoidStatus 3 "NotAvailable" 2 "Error" 1 "On" 0 "Off";
VAL_ 2633922814 PCUDriveSolenoidStatus 3 "NotAvailable" 2 "Error" 1 "On" 0 "Off";
VAL_ 2633922814 DriveChannelMode 15 "NotAvailable" 14 "ErrorCondition" 7 "1101Reserved" 6 "PressCheck" 5 "DfltWtSystmWllDfltWhnCndtnsAllw" 4 "InfltWtSystmWllInfltWhnCndtnsAl" 3 "Confirm" 2 "Deflate" 1 "Inflate" 0 "Maintain";
VAL_ 2633922814 Trailer_TagChannelMode 15 "NotAvailable" 14 "ErrorCondition" 7 "1101Reserved" 6 "PressCheck" 5 "DfltWtSystmWllDfltWhnCndtnsAllw" 4 "InfltWtSystmWllInfltWhnCndtnsAl" 3 "Confirm" 2 "Deflate" 1 "Inflate" 0 "Maintain";
VAL_ 2633922814 SteerChannelMode 15 "NotAvailable" 14 "ErrorCondition" 7 "1101Reserved" 6 "PressCheck" 5 "DfltWtSystmWllDfltWhnCndtnsAllw" 4 "InfltWtSystmWllInfltWhnCndtnsAl" 3 "Confirm" 2 "Deflate" 1 "Inflate" 0 "Maintain";
VAL_ 2633922814 PCUTrailerTagPushSolenoidStatus 3 "NotAvailable" 2 "Error" 1 "On" 0 "Off";
VAL_ 2566845694 TirePressThresholdDetection_13 7 "NotAvailable" 6 "ErrorIndicator" 5 "NotDefined" 4 "ExtrmUndrPrssTrPrssrIsAtALvlWhr" 3 "UndrPrssTrPrssrIsLwrThnThPrssrD" 2 "NWrnngPrssTrPrssrIsWthnThThrshl" 1 "OvrPrssTrPrssrIsHghrThnThPrssrD" 0 "ExtrmOvrPrssTrPrssrIsAtALvlWhrT";
VAL_ 2566845694 TirePressThresholdDetection_12 7 "NotAvailable" 6 "ErrorIndicator" 5 "NotDefined" 4 "ExtrmUndrPrssTrPrssrIsAtALvlWhr" 3 "UndrPrssTrPrssrIsLwrThnThPrssrD" 2 "NWrnngPrssTrPrssrIsWthnThThrshl" 1 "OvrPrssTrPrssrIsHghrThnThPrssrD" 0 "ExtrmOvrPrssTrPrssrIsAtALvlWhrT";
VAL_ 2566845694 TirePressThresholdDetection_11 7 "NotAvailable" 6 "ErrorIndicator" 5 "NotDefined" 4 "ExtrmUndrPrssTrPrssrIsAtALvlWhr" 3 "UndrPrssTrPrssrIsLwrThnThPrssrD" 2 "NWrnngPrssTrPrssrIsWthnThThrshl" 1 "OvrPrssTrPrssrIsHghrThnThPrssrD" 0 "ExtrmOvrPrssTrPrssrIsAtALvlWhrT";
VAL_ 2566845694 TirePressThresholdDetection_10 7 "NotAvailable" 6 "ErrorIndicator" 5 "NotDefined" 4 "ExtrmUndrPrssTrPrssrIsAtALvlWhr" 3 "UndrPrssTrPrssrIsLwrThnThPrssrD" 2 "NWrnngPrssTrPrssrIsWthnThThrshl" 1 "OvrPrssTrPrssrIsHghrThnThPrssrD" 0 "ExtrmOvrPrssTrPrssrIsAtALvlWhrT";
VAL_ 2566845694 TirePressThresholdDetection_01 7 "NotAvailable" 6 "ErrorIndicator" 5 "NotDefined" 4 "ExtrmUndrPrssTrPrssrIsAtALvlWhr" 3 "UndrPrssTrPrssrIsLwrThnThPrssrD" 2 "NWrnngPrssTrPrssrIsWthnThThrshl" 1 "OvrPrssTrPrssrIsHghrThnThPrssrD" 0 "ExtrmOvrPrssTrPrssrIsAtALvlWhrT";
VAL_ 2566845694 CTIWheelSensorStatus_33 3 "NotSupported" 2 "NotDefined" 1 "On" 0 "Off_IsolatedFromCTIPressCtrl";
VAL_ 2566845694 CTIWheelSensorStatus_32 3 "NotSupported" 2 "NotDefined" 1 "On" 0 "Off_IsolatedFromCTIPressCtrl";
VAL_ 2566845694 CTIWheelSensorStatus_31 3 "NotSupported" 2 "NotDefined" 1 "On" 0 "Off_IsolatedFromCTIPressCtrl";
VAL_ 2566845694 CTIWheelSensorStatus_30 3 "NotSupported" 2 "NotDefined" 1 "On" 0 "Off_IsolatedFromCTIPressCtrl";
VAL_ 2566845694 CTIWheelSensorStatus_23 3 "NotSupported" 2 "NotDefined" 1 "On" 0 "Off_IsolatedFromCTIPressCtrl";
VAL_ 2566845694 CTIWheelSensorStatus_22 3 "NotSupported" 2 "NotDefined" 1 "On" 0 "Off_IsolatedFromCTIPressCtrl";
VAL_ 2566845694 CTIWheelSensorStatus_21 3 "NotSupported" 2 "NotDefined" 1 "On" 0 "Off_IsolatedFromCTIPressCtrl";
VAL_ 2566845694 CTIWheelSensorStatus_20 3 "NotSupported" 2 "NotDefined" 1 "On" 0 "Off_IsolatedFromCTIPressCtrl";
VAL_ 2566845694 CTIWheelSensorStatus_13 3 "NotSupported" 2 "NotDefined" 1 "On" 0 "Off_IsolatedFromCTIPressCtrl";
VAL_ 2566845694 CTIWheelSensorStatus_12 3 "NotSupported" 2 "NotDefined" 1 "On" 0 "Off_IsolatedFromCTIPressCtrl";
VAL_ 2566845694 CTIWheelSensorStatus_11 3 "NotSupported" 2 "NotDefined" 1 "On" 0 "Off_IsolatedFromCTIPressCtrl";
VAL_ 2566845694 CTIWheelSensorStatus_10 3 "NotSupported" 2 "NotDefined" 1 "On" 0 "Off_IsolatedFromCTIPressCtrl";
VAL_ 2566845694 CTIWheelSensorStatus_01 3 "NotSupported" 2 "NotDefined" 1 "On" 0 "Off_IsolatedFromCTIPressCtrl";
VAL_ 2566845694 CTIWheelEndElectricalFault_33 3 "NotSupported" 2 "Error" 1 "NotDefined" 0 "Ok";
VAL_ 2566845694 CTIWheelEndElectricalFault_32 3 "NotSupported" 2 "Error" 1 "NotDefined" 0 "Ok";
VAL_ 2566845694 CTIWheelEndElectricalFault_31 3 "NotSupported" 2 "Error" 1 "NotDefined" 0 "Ok";
VAL_ 2566845694 CTIWheelEndElectricalFault_30 3 "NotSupported" 2 "Error" 1 "NotDefined" 0 "Ok";
VAL_ 2566845694 CTIWheelEndElectricalFault_23 3 "NotSupported" 2 "Error" 1 "NotDefined" 0 "Ok";
VAL_ 2566845694 CTIWheelEndElectricalFault_22 3 "NotSupported" 2 "Error" 1 "NotDefined" 0 "Ok";
VAL_ 2566845694 CTIWheelEndElectricalFault_21 3 "NotSupported" 2 "Error" 1 "NotDefined" 0 "Ok";
VAL_ 2566845694 CTIWheelEndElectricalFault_20 3 "NotSupported" 2 "Error" 1 "NotDefined" 0 "Ok";
VAL_ 2566845694 CTIWheelEndElectricalFault_13 3 "NotSupported" 2 "Error" 1 "NotDefined" 0 "Ok";
VAL_ 2566845694 CTIWheelEndElectricalFault_12 3 "NotSupported" 2 "Error" 1 "NotDefined" 0 "Ok";
VAL_ 2566845694 CTIWheelEndElectricalFault_11 3 "NotSupported" 2 "Error" 1 "NotDefined" 0 "Ok";
VAL_ 2566845694 CTIWheelEndElectricalFault_10 3 "NotSupported" 2 "Error" 1 "NotDefined" 0 "Ok";
VAL_ 2566845694 CTIWheelEndElectricalFault_01 3 "NotSupported" 2 "Error" 1 "NotDefined" 0 "Ok";
VAL_ 2566845694 CTITireStatus_33 3 "NotSupported" 2 "Error" 1 "TireLeakDetected" 0 "Ok";
VAL_ 2566845694 CTITireStatus_32 3 "NotSupported" 2 "Error" 1 "TireLeakDetected" 0 "Ok";
VAL_ 2566845694 CTITireStatus_31 3 "NotSupported" 2 "Error" 1 "TireLeakDetected" 0 "Ok";
VAL_ 2566845694 CTITireStatus_30 3 "NotSupported" 2 "Error" 1 "TireLeakDetected" 0 "Ok";
VAL_ 2566845694 CTITireStatus_23 3 "NotSupported" 2 "Error" 1 "TireLeakDetected" 0 "Ok";
VAL_ 2566845694 CTITireStatus_22 3 "NotSupported" 2 "Error" 1 "TireLeakDetected" 0 "Ok";
VAL_ 2566845694 CTITireStatus_21 3 "NotSupported" 2 "Error" 1 "TireLeakDetected" 0 "Ok";
VAL_ 2566845694 CTITireStatus_20 3 "NotSupported" 2 "Error" 1 "TireLeakDetected" 0 "Ok";
VAL_ 2566845694 CTITireStatus_13 3 "NotSupported" 2 "Error" 1 "TireLeakDetected" 0 "Ok";
VAL_ 2566845694 CTITireStatus_12 3 "NotSupported" 2 "Error" 1 "TireLeakDetected" 0 "Ok";
VAL_ 2566845694 CTITireStatus_11 3 "NotSupported" 2 "Error" 1 "TireLeakDetected" 0 "Ok";
VAL_ 2566845694 CTITireStatus_10 3 "NotSupported" 2 "Error" 1 "TireLeakDetected" 0 "Ok";
VAL_ 2566845694 CTITireStatus_01 3 "NotSupported" 2 "Error" 1 "TireLeakDetected" 0 "Ok";
VAL_ 2566845694 TirePressThresholdDetection_33 7 "NotAvailable" 6 "ErrorIndicator" 5 "NotDefined" 4 "ExtrmUndrPrssTrPrssrIsAtALvlWhr" 3 "UndrPrssTrPrssrIsLwrThnThPrssrD" 2 "NWrnngPrssTrPrssrIsWthnThThrshl" 1 "OvrPrssTrPrssrIsHghrThnThPrssrD" 0 "ExtrmOvrPrssTrPrssrIsAtALvlWhrT";
VAL_ 2566845694 TirePressThresholdDetection_32 7 "NotAvailable" 6 "ErrorIndicator" 5 "NotDefined" 4 "ExtrmUndrPrssTrPrssrIsAtALvlWhr" 3 "UndrPrssTrPrssrIsLwrThnThPrssrD" 2 "NWrnngPrssTrPrssrIsWthnThThrshl" 1 "OvrPrssTrPrssrIsHghrThnThPrssrD" 0 "ExtrmOvrPrssTrPrssrIsAtALvlWhrT";
VAL_ 2566845694 TirePressThresholdDetection_31 7 "NotAvailable" 6 "ErrorIndicator" 5 "NotDefined" 4 "ExtrmUndrPrssTrPrssrIsAtALvlWhr" 3 "UndrPrssTrPrssrIsLwrThnThPrssrD" 2 "NWrnngPrssTrPrssrIsWthnThThrshl" 1 "OvrPrssTrPrssrIsHghrThnThPrssrD" 0 "ExtrmOvrPrssTrPrssrIsAtALvlWhrT";
VAL_ 2566845694 TirePressThresholdDetection_30 7 "NotAvailable" 6 "ErrorIndicator" 5 "NotDefined" 4 "ExtrmUndrPrssTrPrssrIsAtALvlWhr" 3 "UndrPrssTrPrssrIsLwrThnThPrssrD" 2 "NWrnngPrssTrPrssrIsWthnThThrshl" 1 "OvrPrssTrPrssrIsHghrThnThPrssrD" 0 "ExtrmOvrPrssTrPrssrIsAtALvlWhrT";
VAL_ 2566845694 TirePressThresholdDetection_23 7 "NotAvailable" 6 "ErrorIndicator" 5 "NotDefined" 4 "ExtrmUndrPrssTrPrssrIsAtALvlWhr" 3 "UndrPrssTrPrssrIsLwrThnThPrssrD" 2 "NWrnngPrssTrPrssrIsWthnThThrshl" 1 "OvrPrssTrPrssrIsHghrThnThPrssrD" 0 "ExtrmOvrPrssTrPrssrIsAtALvlWhrT";
VAL_ 2566845694 TirePressThresholdDetection_22 7 "NotAvailable" 6 "ErrorIndicator" 5 "NotDefined" 4 "ExtrmUndrPrssTrPrssrIsAtALvlWhr" 3 "UndrPrssTrPrssrIsLwrThnThPrssrD" 2 "NWrnngPrssTrPrssrIsWthnThThrshl" 1 "OvrPrssTrPrssrIsHghrThnThPrssrD" 0 "ExtrmOvrPrssTrPrssrIsAtALvlWhrT";
VAL_ 2566845694 TirePressThresholdDetection_21 7 "NotAvailable" 6 "ErrorIndicator" 5 "NotDefined" 4 "ExtrmUndrPrssTrPrssrIsAtALvlWhr" 3 "UndrPrssTrPrssrIsLwrThnThPrssrD" 2 "NWrnngPrssTrPrssrIsWthnThThrshl" 1 "OvrPrssTrPrssrIsHghrThnThPrssrD" 0 "ExtrmOvrPrssTrPrssrIsAtALvlWhrT";
VAL_ 2566845694 TirePressThresholdDetection_20 7 "NotAvailable" 6 "ErrorIndicator" 5 "NotDefined" 4 "ExtrmUndrPrssTrPrssrIsAtALvlWhr" 3 "UndrPrssTrPrssrIsLwrThnThPrssrD" 2 "NWrnngPrssTrPrssrIsWthnThThrshl" 1 "OvrPrssTrPrssrIsHghrThnThPrssrD" 0 "ExtrmOvrPrssTrPrssrIsAtALvlWhrT";
VAL_ 2566845694 TirePressThresholdDetection_00 7 "NotAvailable" 6 "ErrorIndicator" 5 "NotDefined" 4 "ExtrmUndrPrssTrPrssrIsAtALvlWhr" 3 "UndrPrssTrPrssrIsLwrThnThPrssrD" 2 "NWrnngPrssTrPrssrIsWthnThThrshl" 1 "OvrPrssTrPrssrIsHghrThnThPrssrD" 0 "ExtrmOvrPrssTrPrssrIsAtALvlWhrT";
VAL_ 2566845694 CTIWheelSensorStatus_00 3 "NotSupported" 2 "NotDefined" 1 "On" 0 "Off_IsolatedFromCTIPressCtrl";
VAL_ 2566845694 CTIWheelEndElectricalFault_00 3 "NotSupported" 2 "Error" 1 "NotDefined" 0 "Ok";
VAL_ 2566845694 CTITireStatus_00 3 "NotSupported" 2 "Error" 1 "TireLeakDetected" 0 "Ok";
VAL_ 2566821630 EngTrbWstgteActuator1TempStatus 7 "NotAvailable" 6 "Error" 5 "NotDefined" 4 "LowMostSevere" 3 "LowLeastSevere" 2 "InRange" 1 "HighLeastSevere" 0 "HighMostSevere";
VAL_ 2365484286 VehicleOverspeed 3 "NotAvailable" 2 "Error" 1 "Overspeed" 0 "NoOverspeed";
VAL_ 2365484286 VehicleMotion 3 "NotAvailable" 2 "Error" 1 "VehicleMotionDetected" 0 "VehicleMotionNotDetected";
VAL_ 2365484286 DirectionIndicator 3 "NotAvailable" 2 "Error" 1 "Reverse" 0 "Forward";
VAL_ 2365484286 TachographPerformance 3 "NotAvailable" 2 "Error" 1 "PerformanceAnalysis" 0 "NormalPerformance";
VAL_ 2365484286 HandlingInformation 3 "NotAvailable" 2 "Error" 1 "HandlingInformation" 0 "NoHandlingInformation";
VAL_ 2365484286 SystemEvent 3 "NotAvailable" 2 "Error" 1 "TachographEvent" 0 "NoTachographEvent";
VAL_ 2365484286 DriverCardDriver2 3 "NotAvailable" 2 "Error" 1 "DriverCardPresent" 0 "DriverCardNotPresent";
VAL_ 2365484286 Driver2TimeRelatedStates 15 "NotAvailable" 14 "Error" 13 "Other" 7 "1100Reserved" 6 "Limit616HReached" 5 "Limit515MinBefore16H" 4 "Limit49HReached" 3 "Limit315MinBefore9H" 2 "Limit24HReached" 1 "Limit115MinBefore4H" 0 "Normal_NoLimitsReached";
VAL_ 2365484286 DriverCardDriver1 3 "NotAvailable" 2 "Error" 1 "DriverCardPresent" 0 "DriverCardNotPresent";
VAL_ 2365484286 Driver1TimeRelatedStates 15 "NotAvailable" 14 "Error" 13 "Other" 7 "1100Reserved" 6 "Limit616HReached" 5 "Limit515MinBefore16H" 4 "Limit49HReached" 3 "Limit315MinBefore9H" 2 "Limit24HReached" 1 "Limit115MinBefore4H" 0 "Normal_NoLimitsReached";
VAL_ 2365484286 Driver2WorkingState 7 "NotAvailable" 6 "Error" 4 "101Reserved" 3 "DriveBehindWheel" 2 "WrkLdngUnldingWorkingInAnOffice" 1 "DriverAvailableShortBreak" 0 "RestSleeping";
VAL_ 2365484286 Driver1WorkingState 7 "NotAvailable" 6 "Error" 4 "101Reserved" 3 "DriveBehindWheel" 2 "WrkLdngUnldingWorkingInAnOffice" 1 "DriverAvailableShortBreak" 0 "RestSleeping";
VAL_ 2348941054 TrnsShftSlctorDisplayModeSwitch 3 "NotAvailable" 2 "Error" 1 "On" 0 "Off";
VAL_ 2348941054 TransMode4 3 "TakeNoAction" 2 "Reserved" 1 "Enable" 0 "Disable";
VAL_ 2348941054 TransMode3 3 "TakeNoAction" 2 "Reserved" 1 "Enable" 0 "Disable";
VAL_ 2348941054 TransMode2 3 "TakeNoAction" 2 "Reserved" 1 "Enable" 0 "Disable";
VAL_ 2348941054 TransMode1 3 "TakeNoAction" 2 "Reserved" 1 "Enable" 0 "Disable";
VAL_ 2348941054 DisengageDiffLockRqCentralRear 3 "TakeNoAction" 2 "Reserved" 1 "DisengageDiffLock" 0 "EngageDiffLock";
VAL_ 2348941054 DisengageDiffLockRqCentralFront 3 "TakeNoAction" 2 "Reserved" 1 "DisengageDiffLock" 0 "EngageDiffLock";
VAL_ 2348941054 DisengageDiffLockRqCentral 3 "TakeNoAction" 2 "Reserved" 1 "DisengageDiffLock" 0 "EngageDiffLock";
VAL_ 2348941054 DisengageDiffLockRqRearAxle2 3 "TakeNoAction" 2 "Reserved" 1 "DisengageDiffLock" 0 "EngageDiffLock";
VAL_ 2348941054 DisengageDiffLockRqRearAxle1 3 "TakeNoAction" 2 "Reserved" 1 "DisengageDiffLock" 0 "EngageDiffLock";
VAL_ 2348941054 DisengageDiffLockRqFrontAxle2 3 "TakeNoAction" 2 "Reserved" 1 "DisengageDiffLock" 0 "EngageDiffLock";
VAL_ 2348941054 DisengageDiffLockRqFrontAxle1 3 "TakeNoAction" 2 "Reserved" 1 "DisengageDiffLock" 0 "EngageDiffLock";
VAL_ 2348941054 TransRqedGear 60 "Reserved" 61 "Reserved" 222 "NeutralSelectorPos" 223 "ReverseSelectorPos" 224 "PsUnknownAnd_OrNoButtonsPressed" 225 "PrssOfMmntryBttnTRslctCrrentPos" 226 "BtwnRvrsAndPrkShiftSelectorPoss" 227 "BtwnNtrlAndRvrsShftSelectorPoss" 228 "BtwnDrvAndNtrlShiftSelectorPoss" 229 "BtwnD1AndDriveShiftSelectorPoss" 230 "BetweenD2AndD1ShiftSelectorPoss" 231 "BetweenD3AndD2ShiftSelectorPoss" 232 "BetweenD4AndD3ShiftSelectorPoss" 233 "BetweenD5AndD4ShiftSelectorPoss" 234 "BetweenD6AndD5ShiftSelectorPoss" 235 "BetweenD7AndD6ShiftSelectorPoss" 236 "BtwnTwoForwardShiftSelectorPoss" 237 "BtwnTwoReverseShiftSelectorPoss" 238 "BetweenTwoShiftSelectorPoss" 239 "D77thFrwrdSlctrPsRfrncdFrmDrive" 240 "D66thFrwrdSlctrPsRfrncdFrmDrive" 241 "D55thFrwrdSlctrPsRfrncdFrmDrive" 242 "D44thFrwrdSlctrPsRfrncdFrmDrive" 243 "D33rdFrwrdSlctrPsRfrncdFrmDrive" 244 "D22ndFrwrdSlctrPsRfrncdFrmDrive" 245 "D11stFrwrdSlctrPsRfrncdFrmDrive" 246 "Downshift2GearsFromCurrentPos" 247 "Downshift1GearFromCurrentPos" 248 "Upshift2GearsFromCurrentPos" 249 "Upshift1GearFromCurrentPos" 250 "ForwardLowPos" 251 "ParkPos" 252 "ForwardDrivePos" 253 "HoldCurrentGear";
VAL_ 2348941054 DisengageDrivelineRq 2 "Reserved" 3 "TakeNoAction" 1 "DisengageDriveline" 0 "AllowDrivelineEngagement";
VAL_ 2348941054 TransGearShiftInhibitRq 2 "Reserved" 3 "TakeNoAction" 1 "GearShiftsAreInhibited" 0 "GearShiftsAreAllowed";
VAL_ 2348941054 TrnsTrqConverterLockupDisableRq 3 "TakeNoAction" 2 "Reserved" 1 "DisableTorqueConverterLockup" 0 "AllowTorqueConverterLockup";
VAL_ 2348941054 TransRqedLaunchGear 15 "NotAvailable" 14 "Error" 13 "Reserved" 12 "LaunchVehicleInReverse4" 11 "LaunchVehicleInReverse3" 10 "LaunchVehicleInReverse2" 9 "LaunchVehicleInReverse1" 8 "LaunchVehicleIn8thGear" 7 "LaunchVehicleIn7thGear" 6 "LaunchVehicleIn6thGear" 5 "LaunchVehicleIn5thGear" 4 "LaunchVehicleIn4thGear" 3 "LaunchVehicleIn3rdGear" 2 "LaunchVehicleIn2ndGear" 1 "LaunchVehicleIn1stGear" 0 "NSpcfcLnchGrRqdUsDfltLaunchGear";
VAL_ 2348941054 TransReverseGearShiftInhibitRq 3 "TakeNoAction" 2 "Reserved" 1 "InhbtShftsIntRvrsGrAndShftTrnsT" 0 "AllowShiftsIntoReverseGear";
VAL_ 2348941054 TransMode8 3 "TakeNoAction" 2 "Reserved" 1 "Enable" 0 "Disable";
VAL_ 2348941054 TransMode7 3 "TakeNoAction" 2 "Reserved" 1 "Enable" 0 "Disable";
VAL_ 2348941054 TransMode6 3 "TakeNoAction" 2 "Reserved" 1 "Enable" 0 "Disable";
VAL_ 2348941054 TransMode5 3 "TakeNoAction" 2 "Reserved" 1 "Enable" 0 "Disable";
VAL_ 2566839806 EngTurboOilLevelSwitch 3 "NotAvailable" 2 "Error" 1 "OilPresentAtTurbo" 0 "NoOilPresentAtTurbo";
VAL_ 2566841598 EngOverspeedTest 3 "NotAvailable" 2 "Reserved" 1 "EngOverspeedTestActive" 0 "EngOverspeedTestNotActive";
VAL_ 2566841598 EngAirShutoffCmdStatus 0 "ArShtffDsbldNtAttmptngTShtffEng" 3 "NotAvailable" 2 "Reserved" 1 "ArShtffEnbldAttmptngTShtffEngAr";
VAL_ 2566841598 EngAlarmOutputCmdStatus 3 "NotAvailable" 2 "Reserved" 1 "EngAlarmOutputCmdActive" 0 "EngAlarmOutputCmdNotActive";
VAL_ 2566841598 EngAlarmAcknowledge 3 "NotAvailable" 2 "Error" 1 "EngAlarmAcknowledgeActive" 0 "EngAlarmAcknowledgeNotActive";
VAL_ 2566841598 EngProtectionSystemConfig 3 "NotAvailable" 2 "Error" 1 "EnabledInCalib" 0 "DisabledInCalib";
VAL_ 2566841598 EngProtectionSystemTimerState 3 "NotAvailable" 2 "Error" 1 "Active" 0 "Inactive";
VAL_ 2566841598 EngPrtectionSystemTimerOverride 3 "NotAvailable" 2 "Error" 1 "Active" 0 "Inactive";
VAL_ 2566841598 EngPrtctnSystmApprchingShutdown 3 "NotAvailable" 2 "Error" 1 "Approaching" 0 "NotApproaching";
VAL_ 2566841598 EngWaitToStartLamp 3 "NotAvailable" 2 "Error" 1 "On" 0 "Off";
VAL_ 2566841598 RefrigerantHighPressSwitch 3 "NotAvailable" 2 "Error" 1 "PrssTHghCmprssrCltchMyBDsngaged" 0 "PressNormal";
VAL_ 2566841598 RefrigerantLowPressSwitch 3 "NotAvailable" 2 "Error" 1 "PrssTLwCmprssrCltchMyBDsengaged" 0 "PressNormal";
VAL_ 2566841598 A_CHighPressFanSwitch 3 "NotAvailable" 2 "Error" 1 "PressHighFanMayBeEngaged" 0 "PressNormal";
VAL_ 2566841598 EngIdleShutdownTimerFunction 3 "NotAvailable" 2 "Error" 1 "EnabledInCalib" 0 "DisabledInCalib";
VAL_ 2566841598 EngIdleShutdownTimerState 3 "NotAvailable" 2 "Error" 1 "Active" 0 "Inactive";
VAL_ 2566841598 EngIdleShutdownTimerOverride 3 "NotAvailable" 2 "Error" 1 "Active" 0 "Inactive";
VAL_ 2566841598 EngIdleShutdownDriverAlertMode 3 "NotAvailable" 2 "Error" 1 "Active" 0 "Inactive";
VAL_ 2566841598 PTOShutdownHasShutdownEng 3 "NotAvailable" 2 "Error" 1 "Yes" 0 "No";
VAL_ 2566841598 EngPrtctnSystmHasShutdownEngine 3 "NotAvailable" 2 "Error" 1 "Yes" 0 "No";
VAL_ 2566841598 EngIdlShutdownHasShutdownEngine 3 "NotAvailable" 2 "Error" 1 "Yes" 0 "No";
VAL_ 2566841598 EngAirShutoffStatus 3 "NotAvailable" 2 "Error" 1 "AirFlowRestricted" 0 "AirFlowAllowedToEng";
VAL_ 2566847486 DrvlneRetarderOverheatIndicator 3 "NotAvailable" 2 "DrvlnRtrdrOvrhtIndctrIsFlashing" 1 "DrvlnRtrdrOvrhtIndctrIsOnCntnsl" 0 "DrvlnRtrdrOvrheatIndicatorIsOff";
VAL_ 2631859966 EngBuildHoursReset 2 "Reserved" 3 "TakeNoAction" 1 "Reset" 0 "DoNotReset";
VAL_ 2631859966 TripGroup2Proprietary 2 "Reserved" 3 "NotApplicable" 1 "Reset" 0 "TakeNoAction";
VAL_ 2631859966 TripGroup1 2 "Reserved" 3 "NotApplicable" 1 "Reset" 0 "TakeNoAction";
VAL_ 2631859966 SteerStraightAheadPosReset 3 "NotApplicable" 2 "ReservedTakeNoAction" 1 "Reset" 0 "TakeNoActionDoNotReset";
VAL_ 2566840830 RetarderLocation 15 "NotAvailable" 14 "Other" 6 "1101NotDefined" 5 "Trailer" 4 "Driveline" 3 "TransOutput" 2 "TransInput" 1 "EngExhaustBrake" 0 "EngCompressionReleaseBrake";
VAL_ 2566840830 RetarderType 15 "NotAvailable" 14 "Other" 5 "1101NotDefined" 4 "Exhaust" 3 "CompressionRelease" 2 "CooledFriction" 1 "Hyd" 0 "Electric_Magnetic";
VAL_ 2566844670 OprtrEngPTOGvrnrMmrySlectSwitch 3 "notAvailable" 2 "error" 1 "PTOSetSpeedMemory2Selected" 0 "PTOSetSpeedMemory1Selected";
VAL_ 2566844670 EngRmtPTOGvrnrVrblSpdCtrlSwitch 3 "NotAvailable" 2 "Error" 1 "On" 0 "Off";
VAL_ 2566844670 EngRmtPTOGvrnrPrprgrmmdSpdCtrlSw 3 "NotAvailable" 2 "Error" 1 "On" 0 "Off";
VAL_ 2566844670 EngPTOGvrnrCst_DecelerateSwitch 3 "NotAvailable" 2 "Error" 1 "On" 0 "Off";
VAL_ 2566844670 EngPTOGovernorSetSwitch 3 "NotAvailable" 2 "Error" 1 "On" 0 "Off";
VAL_ 2566844670 EngPTOGovernorResumeSwitch 3 "NotAvailable" 2 "Error" 1 "On" 0 "Off";
VAL_ 2566844670 EngPTOGovernorEnableSwitch 3 "NotAvailable" 2 "Error" 1 "On" 0 "Off";
VAL_ 2566844670 EngPTOGovernorAccelerateSwitch 3 "NotAvailable" 2 "Error" 1 "On" 0 "Off";
VAL_ 2566844670 RmtPTOPrprgrmmdSpeedCtrlSwitch2 3 "NotAvailable" 2 "Error" 1 "On" 0 "Off";
VAL_ 2566844670 AuxInputIgnoreSwitch 3 "NotAvailable" 2 "Error" 1 "On" 0 "Off";
VAL_ 2566770174 RearWasherFunction 7 "NotAvailable" 4 "110Reserved" 3 "High" 2 "Medium" 1 "Low" 0 "Off";
VAL_ 2566770174 FrontOperatorWasherSwitch 7 "NotAvailable" 4 "110Reserved" 3 "High" 2 "Medium" 1 "Low" 0 "Off";
VAL_ 2566770174 FrontNonoperatorWasherSwitch 7 "NotAvailable" 4 "110Reserved" 3 "High" 2 "Medium" 1 "Low" 0 "Off";
VAL_ 2566770174 RearWiperSwitch 7 "1110Reserved" 6 "Mist" 5 "Delayed2" 4 "Delayed1" 2 "Medium" 15 "NotAvailable" 3 "High" 1 "Low" 0 "Off";
VAL_ 2566770174 FrontOperatorWiperSwitch 7 "1110Reserved" 6 "Mist" 5 "Delayed2" 4 "Delayed1" 2 "Medium" 15 "NotAvailable" 3 "High" 1 "Low" 0 "Off";
VAL_ 2566770174 FrontNonoperatorWiperSwitch 15 "NotAvailable" 7 "1110Reserved" 6 "Mist" 5 "Delayed2" 4 "Delayed1" 3 "High" 2 "Medium" 1 "Low" 0 "Off";
VAL_ 2566769662 EngAltDroopAuxInputSelect 15 "NotAvailable" 14 "ErrorCondition" 1 "thr1101OnOfAltDrpSttng1Thrgh13I" 0 "NormalDroopSettingIsSelected";
VAL_ 2566769662 EngAltDroopRemoteAccelSelect 15 "NotAvailable" 14 "ErrorCondition" 1 "thr1101OnOfAltDrpSttng1Thrgh13I" 0 "NormalDroopSettingIsSelected";
VAL_ 2566769662 EngAltDroopAccel2Select 15 "NotAvailable" 14 "ErrorCondition" 1 "thr1101OnOfAltDrpSttng1Thrgh13I" 0 "NormalDroopSettingIsSelected";
VAL_ 2566769662 EngAltDroopAccel1Select 15 "NotAvailable" 14 "ErrorCondition" 1 "thr1101OnOfAltDrpSttng1Thrgh13I" 0 "NormalDroopSettingIsSelected";
VAL_ 2566769662 EngAltRatingSelect 1 "IndctsThtAltPwrFling1IsSelected" 0 "IndctsThtMxPwrFuelingIsSelected";
VAL_ 2566769662 EngAltLowIdleSwitch 3 "NotAvailableUnused" 2 "Error" 1 "AltLowIdlePointIsSelected" 0 "DefaultLowIdlePointIsSelected";
VAL_ 2566769662 EngSynchronizationSwitch 3 "NotAvailableUnused" 2 "Error" 1 "FunctionalityIsEnabled" 0 "FunctionalityIsDisabled";
VAL_ 2566769662 EngAuxGovernorSwitch 2 "ErrorCondition" 1 "AuxGovernorIsEnabled" 0 "AuxGovernorIsDisabled" 3 "NotAvailable";
VAL_ 2566768638 EngAltDroopAuxInputSelectState 15 "NotAvailable" 14 "SAEReserved" 1 "thr1101CtrlSttIsOnOfAltDrpSttng" 0 "CtrlStateIsNormalDroopSetting";
VAL_ 2566768638 EngAltDrpRemoteAccelSelectState 15 "NotAvailable" 14 "SAEReserved" 1 "thr1101CtrlSttIsOnOfAltDrpSttng" 0 "CtrlStateIsNormalDroopSetting";
VAL_ 2566768638 EngAltDroopAccel2SelectState 15 "NotAvailable" 14 "SAEReserved" 1 "thr1101CtrlsSttIsOnOfAltDrpSttn" 0 "CtrlsStateIsNormalDroopSetting";
VAL_ 2566768638 EngAltDroopAccel1SelectState 15 "NotAvailable" 14 "SAEReserved" 1 "thr1101CtrlSttIsOnOfAltDrpSttng" 0 "CtrlStateIsNormalDroopSetting";
VAL_ 2566768638 EngAltRatingSelectState 1 "CtrlStateIsAltPowerFueling1" 0 "CtrlStateIsMaxPowerFueling";
VAL_ 2566768638 EngAltLowIdleSelectState 3 "NotAvailable" 2 "SAEReserved" 1 "AltIdleState" 0 "NormalIdleState";
VAL_ 2566768638 EngMultiUnitSyncState 3 "NotAvailable" 2 "SAEReserved" 1 "CtrlStateIsFunctionalityEnabled" 0 "CtrlStteIsFunctionalityDisabled";
VAL_ 2566768638 EngAuxGovernorState 3 "NotAvailable" 2 "SAEReserved" 1 "CtrlStateIsAuxGovernorEnabled" 0 "CtrlStateIsAuxGovernorDisabled";
VAL_ 2365443326 HighLowBeamSwitch 3 "NotAvailable" 2 "Error" 1 "HighBeamSelected" 0 "LowBeamSelected";
VAL_ 2365443326 HazardLightSwitch 3 "NotAvailable" 2 "Error" 1 "HazardLampsToBeFlashing" 0 "HazardLampsToBeOff";
VAL_ 2365443326 TurnSignalSwitch 2 "RightTurnToBeFlashing" 15 "NotAvailable" 14 "Error" 3 "1101Reserved" 1 "LeftTurnToBeFlashing" 0 "NoTurnBeingSignaled";
VAL_ 2365443326 MainLightSwitch 9 "1101Reserved" 8 "DlydOffPsByWhchThOprtrSlctsThtA" 4 "0111Reserved" 2 "HdlghtOnPsByWhchThOprtrSlctsTht" 15 "NotAvailable" 14 "Error" 3 "HdlghtAndPrkOnPsByWhchThOprtrSl" 1 "PrkOnPsByWhchThOprtrSlctsThtThP" 0 "OffPsByWhchThOprtrSlctsThtNnOfT";
VAL_ 2365443326 WorkLightSwitch 5 "1101Reserved" 4 "WrkLghtCmbntn4OnPsByWhchThOprtr" 2 "WrkLghtCmbntn2OnPsByWhchThOprtr" 15 "NotAvailable" 14 "Error" 3 "WrkLghtCmbntn3OnPsByWhchThOprtr" 1 "WrkLghtCmbntn1OnPsByWhchThOprtr" 0 "OffPsByWhchThOprtrSlctsThtNnOfT";
VAL_ 2566802686 BlackOutWorkLampSelect 3 "NotSupported" 2 "Reserved" 1 "On" 0 "Off";
VAL_ 2566802686 NightVisionIlluminatorSelect 3 "NotSupported" 2 "Reserved" 1 "On" 0 "Off";
VAL_ 2566802686 BlackOutBrake_StopLampSelect 3 "NotSupported" 2 "Reserved" 1 "On" 0 "Off";
VAL_ 2566802686 ConvoyDrivingLampSelect 3 "NotSupported" 2 "Reserved" 1 "On" 0 "Off";
VAL_ 2566802686 ConvoyLampSelect 3 "NotSupported" 2 "Reserved" 1 "On" 0 "Off";
VAL_ 2566802686 FrontBlackOutMarkerLampSelect 3 "NotSupported" 2 "Reserved" 1 "On" 0 "Off";
VAL_ 2566802686 RearBlackOutMarkerSelect 3 "NotSupported" 2 "Reserved" 1 "On" 0 "Off";
VAL_ 2566774014 SlowVesselModeStatus 3 "TakeNoAction" 2 "Reserved" 1 "SlowVesselModeIsACTIVE" 0 "SlowVesselModeIsOFF";
VAL_ 2566774014 TrollingModeStatus 3 "TakeNoAction" 2 "Reserved" 1 "TrollingModeIsACTIVE" 0 "TrollingModeIsOFF";
VAL_ 2566774014 EngThrttlSynchrnztionModeStatus 15 "TakeNoAction" 5 "1110Reserved" 4 "SynchronizedMaster" 3 "SynchronizedStarboard" 2 "SynchronizedPort" 1 "SynchronizedCenter" 0 "NotSynchronized";
VAL_ 2432595710 DisplayDeadbands 15 "NotAvailable" 3 "1110Reserved" 2 "Wide_24mm" 1 "Standard_12mm" 0 "Narrow_45mm";
VAL_ 2432595710 LEDPatternCtrl 15 "NotAvailable" 3 "1110Reserved" 2 "7Channel" 1 "Offset" 0 "5Channel";
VAL_ 2432595710 LEDDisplayDeadbandCtrl 15 "NotAvailableNotApplicable" 5 "1110Reserved" 4 "_1Mm" 3 "_5Mm" 2 "_24Mm" 1 "_12Mm" 0 "_45Mm";
VAL_ 2432595710 LEDDisplayModeCtrl 15 "NotAvailableNotApplicable" 3 "1110Reserved" 2 "CenterOnGradeDisplayMode2" 1 "OffsetOnGradeDisplayMode" 0 "CenterOnGradeDisplayMode1";
VAL_ 2432595710 LEDDisplayData1 511 "NotAvailable" 254 "Error" 159 "NoData" 149 "HighCoarse" 148 "HighMedium_Coarse" 147 "HighMedium" 146 "HighMedium_Fine" 145 "HighFine" 144 "OnGrade" 132 "LowFine" 131 "LowMedium_Fine" 130 "LowMedium" 129 "LowMedium_Coarse" 128 "LowCoarse" 32 "LowCoarseLEDOn" 16 "LowFineLEDOn" 8 "OngradeLEDOn" 4 "HighFineLEDOn" 2 "HighCoarseLEDOn";
VAL_ 2365486590 LaserReceiverType 1 "LinearLaserReceiver" 0 "Reserved";
VAL_ 2365485566 LaserTracerInformation 32 "Curb" 16 "Stringline" 8 "PreviousPass" 4 "ValidTarget" 2 "LaserIsReady" 1 "LaserPowerIsOn";
VAL_ 2365485566 LEDDisplayData2 511 "NotAvailable" 254 "Error" 159 "NoData" 149 "HighCoarse" 148 "HighMedium_Coarse" 147 "HighMedium" 146 "HighMedium_Fine" 145 "HighFine" 144 "OnGrade" 132 "LowFine" 131 "LowMedium_Fine" 130 "LowMedium" 129 "LowMedium_Coarse" 128 "LowCoarse" 64 "RightLEDOn" 32 "LeftLEDOn" 16 "DownLEDOn" 8 "UpLEDOn" 4 "OngradeCLEDOn" 2 "OngradeBLEDOn" 1 "OngradeALEDOn";
VAL_ 2364542462 SdshftDsrdBldOffsetOperatorCtrl 15 "NotInstalled" 14 "ErrorIndicator" 4 "1101Reserved" 3 "AutomaticOperatorCtrlRq" 2 "ManualOperatorCtrlRq" 0 "NoOperatorCtrlRq" 1 "MomentaryOperatorCtrlRq";
VAL_ 2364542462 SdshftBldCtrlMdeOperatorControl 15 "NotInstalled" 14 "ErrorIndicator" 3 "1101Reserved" 2 "DecrementOperatorCtrlRq" 0 "NoOperatorCtrlRq" 1 "IncrementOperatorCtrlRq";
VAL_ 2364542462 RghtDsrdBladeOffsetOperatorCtrl 15 "NotInstalled" 14 "ErrorIndicator" 3 "1101Reserved" 2 "DecrementOperatorCtrlRq" 0 "NoOperatorCtrlRq" 1 "OprtrCtrlSttCnBRdInTwWysOnMthdU";
VAL_ 2364542462 RghtBldeCtrlModeOperatorControl 15 "NotInstalled" 14 "ErrorIndicator" 3 "AutomaticOperatorCtrlRq" 2 "ManualOperatorCtrlRq" 0 "NoChange" 1 "MomentaryOperatorCtrlRq";
VAL_ 2364542462 LftDsredBladeOffsetOperatorCtrl 15 "NotInstalled" 14 "ErrorIndicator" 3 "1101Reserved" 2 "DecrementOperatorCtrlRq" 0 "NoOperatorCtrlRq" 1 "OprtrCtrlSttCnBRdInTwWysOnMthdU";
VAL_ 2364542462 LftBladeCtrlModeOperatorControl 15 "NotInstalled" 14 "ErrorIndicator" 12 "1101Reserved" 3 "AutomaticOperatorCtrlRq" 2 "ManualOperatorCtrlRq" 0 "NoChange" 1 "OprtrCtrlSttCnBRdInTwWysOnMthdU";
VAL_ 2364542462 BladeAutoModeCmd 15 "NotSupported" 14 "ErrorIndicator" 4 "AutoNotAllowed" 3 "SrvcMdAtAllwdOnlyDrngSrvceModes" 2 "SspndAtTmprarilySuspendAutoMode" 1 "ActvtyAllwsAtMstDtctOprtrBfrAtA" 0 "AutoAllowed";
VAL_ 2364542462 DesiredGradeOffsetSwitch 15 "NotInstalled" 14 "ErrorIndicator" 2 "DecrementButtonPressed" 0 "NoButtonPressed" 1 "SwtchSttCnBRdInTwWysOnMthdUssTh";
VAL_ 2364542462 BladeCtrlModeSwitch 15 "NotInstalled" 14 "ErrorIndicator" 3 "AutomaticButtonPressed" 2 "ManualButtonPressed" 0 "NoButtonPressed" 1 "SwtchSttCnBRdInTwWysOnMthdUssTh";
VAL_ 2364542462 StElvtnSnsor2ReferenceElevation 3 "DontCare_TakeNoAction" 2 "Reserved" 1 "SetReferenceElevation" 0 "DoNotSetReferenceElevation";
VAL_ 2364542462 StElvtnSnsor1ReferenceElevation 3 "DontCare_TakeNoAction" 2 "Reserved" 1 "SetReferenceElevation" 0 "DoNotSetReferenceElevation";
VAL_ 2633937918 FlexibleFuelPercentage 4 "MansAlcoholAsFuelAndNothingElse";
VAL_ 2633883646 FrontWheelDriveActuatorStatus 3 "NotAvailable" 2 "Error" 1 "FrontWheelDriveActuatorEngaged" 0 "FrntWhelDriveActuatorNotEngaged";
VAL_ 2633880062 FMSstandardRqsSupported 3 "DontCare" 2 "Reserved" 1 "OnRqModeIsSupported" 0 "OnRqModeIsNotSupported";
VAL_ 2633880062 FMSstandardDiagnosticsSupported 3 "DontCare" 2 "Reserved" 1 "DiagnosticsIsSupported" 0 "DiagnosticsIsNotSupported";
VAL_ 2566806526 LnDprtureIndicationEnableStatus 3 "NotUsed" 2 "Reserved" 1 "LaneDepartureIndicationEnabled" 0 "LaneDepartureIndicationDisabled";
VAL_ 2566806526 LaneTrackingStatusLeftSide 3 "DontCare_TakeNoAction" 2 "Reserved" 1 "TrackingLeftSide" 0 "NotTrackingLeftSide";
VAL_ 2566806526 LaneTrackingStatusRightSide 3 "DontCare_TakeNoAction" 2 "Reserved" 1 "TrackingRightSide" 0 "NotTrackingRightSide";
VAL_ 2431649790 LaneDepartureImminentLeftSide 3 "NotUsed" 2 "Reserved" 1 "Imminent" 0 "NotImminent";
VAL_ 2431649790 LaneDepartureImminentRightSide 3 "NotUsed" 2 "Reserved" 1 "Imminent" 0 "NotImminent";
VAL_ 2431649790 LaneDepartureRight 3 "TakeNoAction" 2 "Reserved" 1 "MddlOfVhclDprtsThLnTThRightSide" 0 "MddlOfVhclDsNtDprtThLnTThRghtSd";
VAL_ 2431649790 LaneDepartureLeft 3 "TakeNoAction" 2 "Reserved" 1 "MddlOfVhclDprtsThLnTTheLeftSide" 0 "MddlOfVhclDsNtDprtThLnTThLftSde";
VAL_ 2633929214 EngFuelLeakage2 3 "NotAvailable" 2 "Error" 1 "LeakageDetected" 0 "NoLeakageDetected";
VAL_ 2633929214 EngFuelLeakage1 3 "NotAvailable" 2 "Error" 1 "LeakageDetected" 0 "NoLeakageDetected";
VAL_ 2566831614 FanDriveState 15 "NotAvailable" 14 "Other" 13 "EngBrake" 12 "Timer" 11 "A_CSystem" 10 "TransRetarder" 9 "ManualCtrl" 8 "ReverseOperation" 7 "DefaultOperation" 6 "ExcessiveHydOilTemp" 5 "ExcessiveTransOilTemp" 4 "ExcessiveEngCoolantTemp" 3 "ExcessiveEngOilTemp" 2 "ExcessiveEngAirTemp" 1 "EngSystemGeneral" 0 "FanOff";
VAL_ 2566820094 EngTorqueLimitFeature 7 "NotAvailable" 5 "110Reserved" 4 "CurrentTorqueRating" 3 "PreviousTorqueRating" 2 "FirstTorqueRating" 1 "HighestTorqueRating" 0 "Reserved";
VAL_ 2566820094 TorqueLimitingFeatureStatus 3 "NotAvailable" 2 "Error" 1 "Enabled" 0 "Disabled";
VAL_ 2364542206 TransTorqueConverterRatio 64256 "RatioCannotBeProperlyDetermined";
VAL_ 2566802174 TrnsRvrseGearShiftInhibitStatus 3 "NotAvailable" 2 "Error" 1 "RvrsGrShftsArCurrentlyInhibited" 0 "RvrsGrShiftsAreCurrentlyAllowed";
VAL_ 2566802174 TrnsCrrntRangeDisplayBlankState 3 "NotSupported" 2 "Error" 1 "Blanked" 0 "NotBlanked";
VAL_ 2566802174 TransWarningIndicator 3 "NotAvailable" 2 "TransWarningIndicatorIsFlashing" 1 "TrnsWrnngIndctrIsOnContinuously" 0 "TransWarningIndicatorIsOff";
VAL_ 2566802174 TransMode8Indicator 3 "TakeNoAction" 2 "Reserved" 1 "Enable" 0 "Disable";
VAL_ 2566802174 TransMode7Indicator 3 "TakeNoAction" 2 "Reserved" 1 "Enable" 0 "Disable";
VAL_ 2566802174 TransMode6Indicator 3 "TakeNoAction" 2 "Reserved" 1 "Enable" 0 "Disable";
VAL_ 2566802174 TransMode5Indicator 3 "TakeNoAction" 2 "Reserved" 1 "Enable" 0 "Disable";
VAL_ 2566802174 TransMode1Indicator 3 "NotAvailable" 2 "Error" 1 "TransMode1Active" 0 "TransMode1NotActive";
VAL_ 2566802174 TransMode2Indicator 3 "NotAvailable" 2 "Error" 1 "TransMode2Active" 0 "TransMode2NotActive";
VAL_ 2566802174 TransMode3Indicator 3 "NotAvailable" 2 "Error" 1 "TransMode3Active" 0 "TransMode3NotActive";
VAL_ 2566802174 TransMode4Indicator 3 "NotAvailable" 2 "Error" 1 "TransMode4Active" 0 "TransMode4NotActive";
VAL_ 2566802174 TransShiftInhibitIndicator 3 "TakeNoAction" 2 "Reserved" 1 "ActiveShiftIsInhibited" 0 "InactiveShiftIsNotInhibited";
VAL_ 2566802174 TransEngCrankEnable 3 "NotAvailable" 2 "Error" 1 "CrnkngEnbldEngCrnkngIsAllwdByTr" 0 "CrnkngDsbldEngCrnkngIsPrhbtdByT";
VAL_ 2566802174 ActiveShiftConsoleIndicator 3 "NotAvailable" 2 "Reserved" 1 "SecondShiftConsoleIsActive" 0 "PrimaryShiftConsoleIsActive";
VAL_ 2566802174 TransReadyForBrakeRelease 3 "NotAvailable" 2 "Error" 1 "TransReadyForBrakeRelease" 0 "TransNotReadyForBrakeRelease";
VAL_ 2566802174 TransRqedRangeDisplayFlashState 3 "TakeNoAction" 2 "Reserved" 1 "ActvTrnsRqdRngDsplyShldBFlshing" 0 "InctvTrnsRqdRngDsplyShldNtBFlsh";
VAL_ 2566802174 TransRqedRangeDisplayBlankState 3 "TakeNoAction" 2 "Reserved" 1 "ActvTrnsRqdRngDsplyShldBBlanked" 0 "InctvTrnsRqdRngDsplyShldNtBBlnk";
VAL_ 2566802174 TransServiceIndicator 3 "NotAvailable" 2 "ServiceIndicatorFlashing" 1 "ServiceIndicatorOn" 0 "SeviceIndicatorOff";
VAL_ 2633935870 LowestPossibleGear 251 "Park";
VAL_ 2633935870 HighestPossibleGear 251 "Park";
VAL_ 2633935870 RecommendedGear 251 "Park";
VAL_ 2633942014 TransForwardDirectionSwitch 3 "NotAvailable" 2 "Error" 1 "On" 0 "Off";
VAL_ 2633942014 TransNeutralSwitch 3 "NotAvailable" 2 "Error" 1 "On" 0 "Off";
VAL_ 2633942014 TransReverseDirectionSwitch 3 "NotAvailable" 2 "Error" 1 "On" 0 "Off";
VAL_ 2633942014 TransLowRangeSenseSwitch 3 "NotAvailable" 2 "Error" 1 "On" 0 "Off";
VAL_ 2633942014 TransHighRangeSenseSwitch 3 "NotAvailable" 2 "Error" 1 "On" 0 "Off";
VAL_ 2633943038 TransInertiaBrakeActuator 3 "NotAvailable" 2 "Error" 1 "On" 0 "Off";
VAL_ 2633943038 TransDefuelActuator 3 "NotAvailable" 2 "Error" 1 "On" 0 "Off";
VAL_ 2633943038 TransLockupClutchActuator 3 "NotAvailable" 2 "Error" 1 "On" 0 "Off";
VAL_ 2633943038 TransClutchActuator 3 "NotAvailable" 2 "Error" 1 "On" 0 "Off";
VAL_ 2633943038 TransSplitterIndirectActuator 3 "NotAvailable" 2 "Error" 1 "On" 0 "Off";
VAL_ 2633943038 TransSplitterDirectActuator 3 "NotAvailable" 2 "Error" 1 "On" 0 "Off";
VAL_ 2633943038 TransRangeLowActuator 3 "NotAvailable" 2 "Error" 1 "On" 0 "Off";
VAL_ 2633943038 TransRangeHighActuator 3 "NotAvailable" 2 "Error" 1 "On" 0 "Off";
VAL_ 2633943038 TransShiftFingerGearActuator2 3 "NotAvailable" 2 "Error" 1 "On" 0 "Off";
VAL_ 2633943038 TransShiftFingerRailActuator2 3 "NotAvailable" 2 "Error" 1 "On" 0 "Off";
VAL_ 2633943038 TransShiftFingerGearActuator1 3 "NotAvailable" 2 "Error" 1 "On" 0 "Off";
VAL_ 2633943038 TransShiftFingerRailActuator1 3 "NotAvailable" 2 "Error" 1 "On" 0 "Off";
VAL_ 2633943038 TrnsShftFngrCenterRailIndicator 3 "NotAvailable" 2 "Error" 1 "On" 0 "Off";
VAL_ 2633943038 TrnsShftFngrEngagementIndicator 3 "NotAvailable" 2 "Error" 1 "On" 0 "Off";
VAL_ 2633943038 TrnsShiftFingerNeutralIndicator 3 "NotAvailable" 2 "Error" 1 "On" 0 "Off";
VAL_ 2565867006 TransCurrentGear 251 "Park";
VAL_ 2565867006 TransSelectedGear 251 "Park";
VAL_ 2364539646 TrnsTrqueConverterLockupEngaged 3 "NotAvailable" 2 "Error" 1 "TorqueConverterLockupEngaged" 0 "TorqueConverterLockupDisengaged";
VAL_ 2364539646 TrnsTrqCnvrtrLckpTrnstnInPrcess 3 "NotAvailable" 2 "Error" 1 "TransitionIsInProcess" 0 "TransitionIsNotInProcess";
VAL_ 2364539646 MomentaryEngMaxPowerEnable 3 "notAvailable" 2 "fault" 1 "mmntarilyRqingMaxPowerAvailable" 0 "notRqingMaxPowerAvailable";
VAL_ 2364539646 ProgressiveShiftDisable 2 "Reserved" 3 "TakeNoAction" 1 "ProgressiveShiftIsDisabled" 0 "ProgressiveShiftIsNotDisabled";
VAL_ 2364539646 EngMomentaryOverspeedEnable 3 "TakeNoAction" 2 "Reserved" 1 "MomentaryEngOverspeedIsEnabled" 0 "MomentaryEngOverspeedIsDisabled";
VAL_ 2364539646 TransShiftInProcess 3 "NotAvailable" 2 "Error" 1 "ShiftInProcess" 0 "ShiftIsNotInProcess";
VAL_ 2364539646 TransDrivelineEngaged 3 "NotAvailable" 2 "Error" 1 "DrivelineEngaged" 0 "DrivelineDisengaged";
VAL_ 2565868542 SterableLiftAxleLoweringInhibit 3 "NotAvailable" 2 "Reserved" 1 "LoweringInhibited" 0 "LoweringAllowed";
VAL_ 2565868542 TypeOfSteerTrans 15 "NotAvailable" 4 "1110ReservedForSAEAssignment" 3 "HybrdStrTrnsAStrngTrnsmssnInWhc" 2 "PrlyElctrcStrTrnsAStrngTrnsmssn" 1 "PrlyHydStrTrnsAStrngTrnsmssnInW" 0 "PrlyMchStrTrnsAStrngTrnsmssnInW";
VAL_ 2565868542 TypeOfSteerForces 15 "NotAvailable" 4 "1110ReservedForSAEAssignment" 3 "SlfTrckngStrEqpmntASystmDsgndTC" 2 "FllPwrStrEqpmntStrngFrcsArPrvdd" 1 "PwrAssstdStrEqpmntStrngFrcsRslt" 0 "MnlStrEqpmntStrngFrcsRsltSllyFr";
VAL_ 2565868542 SteerType 15 "NotAvailable" 2 "1110ReservedForAssignmentBySAE" 1 "AxStrEqpmntASystmInWhchWhlsOnAx" 0 "MnStrSystmStrngEqpmntOfAVhclWhc";
VAL_ 2565868542 StatusOfSteerAxle 15 "NotAvailable" 6 "1110ReservedForSAEAssignment" 5 "AxleSteerInSpecialMode" 4 "AxleNotActiveBecauseOfAnError" 3 "AxleCenteredBecauseOfAnError" 2 "AxleCentered" 1 "AxleSteerActive" 0 "AxleSteerNotActive";
VAL_ 2633941758 TransOutputRetarder 3 "NotAvailable" 2 "Error" 1 "On" 0 "Off";
VAL_ 2565865726 RetarderRoadSpeedLimitSwitch 3 "NotAvailable" 2 "ErrorIndicator" 1 "RdSpdLmtngByRtrdrIsEnbldRdSpdTh" 0 "RdSpdLmtingByRetarderIsDisabled";
VAL_ 2565865726 RetarderRoadSpeedExceededStatus 3 "DontCare_TakeNoAction" 2 "Reserved" 1 "RdSpdIsAbvThrshldAndRtrdrIsAllw" 0 "RoadSpeedIsBelowThreshold";
VAL_ 2565865726 RetarderRqingBrakeLight 3 "NotAvailable_TakeNoAction" 2 "Reserved" 1 "RtrdrIsRqngThtBrkLghtsArIllmntd" 0 "RtrdrIsNtRqngThtBrkLghtsArIllmn";
VAL_ 2565865726 EngCoolantLoadIncrease 3 "NotAvailable" 2 "Error" 1 "CoolantLoadIncreasePossible" 0 "NoCoolantLoadIncrease";
VAL_ 2565865726 RetarderEnableShiftAssistSwitch 3 "NotAvailable" 2 "Error" 1 "RetarderShiftAssistEnabled" 0 "RetarderShiftAssistDisabled";
VAL_ 2565865726 RetarderEnableBrakeAssistSwitch 3 "NotAvailable" 2 "Error" 1 "RetarderBrakeAssistEnabled" 0 "RetarderBrakeAssistDisabled";
VAL_ 2633935358 EngExhstGsOxygnSnsrClsdLpOprton 3 "DontCare_TakeNoAction" 2 "Reserved" 1 "EngUsngExhstGsOxygnSnsrFrAClsdL" 0 "EngNtUsngExhaustGasOxygenSensor";
VAL_ 2365447166 Jystck3GripXAxisDetentPosStatus 3 "NotAvailable" 2 "ErrorIndicator" 1 "InDetentPos" 0 "NotInDetentPos";
VAL_ 2365447166 Jystck3GripYAxisDetentPosStatus 3 "NotAvailable" 2 "ErrorIndicator" 1 "InDetentPos" 0 "NotInDetentPos";
VAL_ 2365447166 Jystck3ThetaAxisDetentPosStatus 3 "NotAvailable" 2 "ErrorIndicator" 1 "InDetentPos" 0 "NotInDetentPos";
VAL_ 2365447166 Jystck3ThtAxsClckwsPstvPsStatus 3 "NotAvailable" 2 "ErrorIndicator" 1 "OnPositiveSideOfNeutral" 0 "NotOnPositiveSideOfNeutral";
VAL_ 2365447166 Jystck3ThtaAxisNeutralPosStatus 3 "NotAvailable" 2 "ErrorIndicator" 1 "InNeutralPos" 0 "NotInNeutralPos";
VAL_ 2365447166 Jystck3GrpYAxsLvrFrwrdPstvPsStts 3 "NotAvailable" 2 "ErrorIndicator" 1 "OnPositiveSideOfNeutral" 0 "NotOnPositiveSideOfNeutral";
VAL_ 2365447166 Jystck3GrpYAxsLvrBckNgtvPsSttus 3 "NotAvailable" 2 "ErrorIndicator" 1 "OnNegativeSideOfNeutral" 0 "NotOnNegativeSideOfNeutral";
VAL_ 2365447166 Jystck3GrpYAxisNeutralPosStatus 3 "NotAvailable" 2 "ErrorIndicator" 1 "InNeutralPos" 0 "NotInNeutralPos";
VAL_ 2365447166 Jystck3GrpXAxsLvrRghtPstvPsStts 3 "NotAvailable" 2 "ErrorIndicator" 1 "OnPositiveSideOfNeutral" 0 "NotOnPositiveSideOfNeutral";
VAL_ 2365447166 Jystck3GrpXAxsLvrLftNgtvPsSttus 3 "NotAvailable" 2 "ErrorIndicator" 1 "OnNegativeSideOfNeutral" 0 "NotOnNegativeSideOfNeutral";
VAL_ 2365447166 Jystck3GrpXAxisNeutralPosStatus 3 "NotAvailable" 2 "ErrorIndicator" 1 "OnNegativeSideOfNeutral" 0 "NotOnNegativeSideOfNeutral";
VAL_ 2365447166 Jystck3ThtAxsCntrClckwsNgtvPsStt 3 "NotAvailable" 2 "ErrorIndicator" 1 "OnNegativeSideOfNeutral" 0 "NotOnNegativeSideOfNeutral";
VAL_ 2365446654 Jystck2GripXAxisDetentPosStatus 3 "NotAvailable" 2 "ErrorIndicator" 1 "InDetentPos" 0 "NotInDetentPos";
VAL_ 2365446654 Jystck2GripYAxisDetentPosStatus 3 "NotAvailable" 2 "ErrorIndicator" 1 "InDetentPos" 0 "NotInDetentPos";
VAL_ 2365446654 Jystck2ThetaAxisDetentPosStatus 3 "NotAvailable" 2 "ErrorIndicator" 1 "InDetentPos" 0 "NotInDetentPos";
VAL_ 2365446654 Jystck2ThtAxsClckwsPstvPsStatus 3 "NotAvailable" 2 "ErrorIndicator" 1 "OnPositiveSideOfNeutral" 0 "NotOnPositiveSideOfNeutral";
VAL_ 2365446654 Jystck2ThtaAxisNeutralPosStatus 3 "NotAvailable" 2 "ErrorIndicator" 1 "InNeutralPos" 0 "NotInNeutralPos";
VAL_ 2365446654 Jystck2GrpYAxsLvrFrwrdPstvPsStts 3 "NotAvailable" 2 "ErrorIndicator" 1 "OnPositiveSideOfNeutral" 0 "NotOnPositiveSideOfNeutral";
VAL_ 2365446654 Jystck2GrpYAxsLvrBckNgtvPsSttus 3 "NotAvailable" 2 "ErrorIndicator" 1 "OnNegativeSideOfNeutral" 0 "NotOnNegativeSideOfNeutral";
VAL_ 2365446654 Jystck2GrpYAxisNeutralPosStatus 3 "NotAvailable" 2 "ErrorIndicator" 1 "InNeutralPos" 0 "NotInNeutralPos";
VAL_ 2365446654 Jystck2GrpXAxsLvrRghtPstvPsStts 3 "NotAvailable" 2 "ErrorIndicator" 1 "OnPositiveSideOfNeutral" 0 "NotOnPositiveSideOfNeutral";
VAL_ 2365446654 Jystck2GrpXAxsLvrLftNgtvPsSttus 3 "NotAvailable" 2 "ErrorIndicator" 1 "OnNegativeSideOfNeutral" 0 "NotOnNegativeSideOfNeutral";
VAL_ 2365446654 Jystck2GrpXAxisNeutralPosStatus 3 "NotAvailable" 2 "ErrorIndicator" 1 "OnNegativeSideOfNeutral" 0 "NotOnNegativeSideOfNeutral";
VAL_ 2365446654 Jystck2ThtAxsCntrClckwsNgtvPsStt 3 "NotAvailable" 2 "ErrorIndicator" 1 "OnNegativeSideOfNeutral" 0 "NotOnNegativeSideOfNeutral";
VAL_ 2365446142 Jystck1GripXAxisDetentPosStatus 3 "NotAvailable" 2 "ErrorIndicator" 1 "InDetentPos" 0 "NotInDetentPos";
VAL_ 2365446142 Jystck1GripYAxisDetentPosStatus 3 "NotAvailable" 2 "ErrorIndicator" 1 "InDetentPos" 0 "NotInDetentPos";
VAL_ 2365446142 Jystck1ThetaAxisDetentPosStatus 3 "NotAvailable" 2 "ErrorIndicator" 1 "InDetentPos" 0 "NotInDetentPos";
VAL_ 2365446142 Jystck1ThtAxsClckwsPstvPsStatus 3 "NotAvailable" 2 "ErrorIndicator" 1 "OnPositiveSideOfNeutral" 0 "NotOnPositiveSideOfNeutral";
VAL_ 2365446142 Jystck1ThtaAxisNeutralPosStatus 3 "NotAvailable" 2 "ErrorIndicator" 1 "InNeutralPos" 0 "NotInNeutralPos";
VAL_ 2365446142 Jystck1GrpYAxsLvrFrwrdPstvPsStts 3 "NotAvailable" 2 "ErrorIndicator" 1 "OnPositiveSideOfNeutral" 0 "NotOnPositiveSideOfNeutral";
VAL_ 2365446142 Jystck1GrpYAxsLvrBckNgtvPsSttus 3 "NotAvailable" 2 "ErrorIndicator" 1 "OnNegativeSideOfNeutral" 0 "NotOnNegativeSideOfNeutral";
VAL_ 2365446142 Jystck1GrpYAxisNeutralPosStatus 3 "NotAvailable" 2 "ErrorIndicator" 1 "InNeutralPos" 0 "NotInNeutralPos";
VAL_ 2365446142 Jystck1GrpXAxsLvrRghtPstvPsStts 3 "NotAvailable" 2 "ErrorIndicator" 1 "OnPositiveSideOfNeutral" 0 "NotOnPositiveSideOfNeutral";
VAL_ 2365446142 Jystck1GrpXAxsLvrLftNgtvPsSttus 3 "NotAvailable" 2 "ErrorIndicator" 1 "OnNegativeSideOfNeutral" 0 "NotOnNegativeSideOfNeutral";
VAL_ 2365446142 Jystck1GrpXAxisNeutralPosStatus 3 "NotAvailable" 2 "ErrorIndicator" 1 "InNeutralPos" 0 "NotInNeutralPos";
VAL_ 2365446142 Jystck1ThtAxsCntrClckwsNgtvPsStt 3 "NotAvailable" 2 "ErrorIndicator" 1 "OnNegativeSideOfNeutral" 0 "NotOnNegativeSideOfNeutral";
VAL_ 2566810366 FuelPumpPrimerStatus 3 "Unavailable" 2 "Error" 1 "On" 0 "Off";
VAL_ 2566810366 EngWasteOilReservoirLevel 4 "RepresentsCompletelyFull";
VAL_ 2566810366 EngVentilationStatus 7 "NotAvailableNotInstalle" 6 "NtAblTDtrmnIfSufficientlyVented" 5 "ReservedForSAEAssignment" 3 "CurrentlyVenting" 2 "VentilationDelay" 1 "VentilationNeeded" 0 "SufficientlyVented";
VAL_ 2566810366 EngOilPrimingState 3 "NotAvailableNotInstalled" 2 "UnblTDtrmnIfSffcentlyLubricated" 1 "SufficientlyLubricated" 0 "NotSufficientlyLubricated";
VAL_ 2566810366 EngOilPrimingPumpSwitch 3 "NotAvailableNotInstalled" 2 "Error" 1 "On" 0 "Off";
VAL_ 2566810366 EngOilPreHeatedState 3 "NotAvailableNotInstalled" 2 "UnblTDtrmnIfEngOlIsPrhtdSffcntl" 1 "SufficientlyPreheated" 0 "NotSufficientlyPreheated";
VAL_ 2566810366 EngCoolantPreheatedState 3 "NotAvailableNotInstalled" 2 "UnblTDtrmnEngClntPrhtdSffcently" 1 "SufficientlyPreheated" 0 "NotSufficientlyPreheated";
VAL_ 2633929726 TurningGearEngaged 1 "TurningGearIsEngaged" 0 "TurningGearIsNotEngaged" 3 "NotAvailable" 2 "Error";
VAL_ 2633929726 SafetyWireStatus 3 "NotAvailable" 2 "Error" 1 "SafetyWireHasBeenActivated" 0 "SafetyWireHasNotBeenActivated";
VAL_ 2566772222 EngVrableGeometryTurbo1CtrlMode 3 "notAvailable" 2 "SAEReserved" 1 "closedLoop" 0 "openLoop";
VAL_ 2566772222 EngVrblGmtryTrbArCtrlShtffValve 3 "NotAvailable" 2 "Reserved" 1 "VGTAirCtrlShutoffValveIsOn" 0 "VGTAirCtrlShutoffValveIsOff";
VAL_ 2633940734 EngRotationDirection 3 "NotAvailable" 2 "Reserved" 1 "ClockWise" 0 "CounterClockWise";
VAL_ 2633940734 EngIntakeManifoldPressCtrlMode 3 "NotAvailable" 2 "SAEReserved" 1 "ClosedLoop" 0 "OpenLoop";
VAL_ 2566840318 Aftertreatment2IntakeDewPoint 3 "NotAvailable" 2 "Error" 1 "ExceededDewPoint" 0 "NotExceededDewPoint";
VAL_ 2566840318 Aftertreatment2ExhaustDewPoint 3 "NotAvailable" 2 "Error" 1 "ExceededDewPoint" 0 "NotExceededDewPoint";
VAL_ 2566840318 Aftertreatment1IntakeDewPoint 3 "NotAvailable" 2 "Error" 1 "ExceededDewPoint" 0 "NotExceededDewPoint";
VAL_ 2566840318 Aftertreatment1ExhaustDewPoint 3 "NotAvailable" 2 "Error" 1 "ExceededDewPoint" 0 "NotExceededDewPoint";
VAL_ 2566840318 EstEngPrsticLossesPercentTorque 251 "LossesAreIncludedInSPN514";
VAL_ 2364539902 SCRThermalManagementActive 3 "DontCare" 2 "Reserved" 1 "SCRThermalManagementIsActive" 0 "SCRThermalManagementIsNotActive";
VAL_ 2364539902 MmntryEngMaxPowerEnableFeedback 3 "dontCare" 2 "reserved" 1 "supported" 0 "disabled";
VAL_ 2364539902 DPFThermalManagementActive 3 "DontCare" 2 "Reserved" 1 "DPFThermalManagementIsActive" 0 "DPFThermalManagementIsNotActive";
VAL_ 2364539902 VhclAccelerationRateLimitStatus 3 "NotAvailable" 2 "Reserved" 1 "LimitActive" 0 "LimitNotActive";
VAL_ 2364539902 AccelPedal2LowIdleSwitch 3 "NotAvailable" 2 "Error" 1 "AccelPedal2InLowIdleCondition" 0 "AcclPedal2NotInLowIdleCondition";
VAL_ 2364539902 RoadSpeedLimitStatus 3 "NotAvailable" 2 "Error" 1 "NotActive" 0 "Active";
VAL_ 2364539902 AccelPedalKickdownSwitch 3 "NotAvailable" 2 "Error" 1 "KickdownActive" 0 "KickdownPassive";
VAL_ 2364539902 AccelPedal1LowIdleSwitch 3 "NotAvailable" 2 "Error" 1 "AccelPedal1InLowIdleCondition" 0 "AcclPedal1NotInLowIdleCondition";
VAL_ 2364540158 ActlEngPrcntTrqueHighResolution 8 "1111NotAvailable" 7 "0875" 1 "0125" 0 "0000";
VAL_ 2364540158 EngStarterMode 15 "notAvailable" 14 "error" 12 "starterInhibitedReasonUnknown" 9 "1011Reserved" 8 "strtrInhbtdDueToStarterOvertemp" 7 "strtrInhbtdDToActiveImmobilizer" 6 "strtrInhbtdDTDrvlnEnggdOthrTrns" 5 "strtrInhbtdDTEngNtReadyForStart" 4 "strtrInhbtdDToEngAlreadyRunning" 3 "strtFnshdStrtrNtActvAftrHvngBnA" 2 "starterActiveGearEngaged" 1 "starterActiveGearNotEngaged" 0 "startNotRqed";
VAL_ 2364540158 EngTorqueMode 15 "Not available" 11 "Remote accelerator" 10 "Braking system" 9 "High speed governor" 8 "Torque limiting" 7 "ABS control" 6 "Transmission control" 5 "ASR control" 4 "Road speed governor" 3 "PTO governor" 2 "Cruise control" 1 "Accelerator pedal/operator selec" 0 "Low idle governor/no request (de";
VAL_ 2566841342 SupportTSC1CtrlPurposeGroup4 1 "P25ReservedForAssignmentBySAE";
VAL_ 2566841342 SupportTSC1CtrlPurposeGroup3 1 "P17ReservedForAssignmentBySAE";
VAL_ 2566841342 SupportTSC1CtrlPurposeGroup2 1 "P9ReservedForAssignmentBySAE";
VAL_ 2566841342 SupportTSC1CtrlPurposeGroup1 1 "P1AccelPedal_OperatorSelection";
VAL_ 2566841342 SupportVariableRateTSC1Message 1 "MsTransRate";
VAL_ 2566767870 BrakeTempWarning 3 "notAvailable" 2 "Reserved" 1 "Active" 0 "NotActive";
VAL_ 2566767870 PrkngBrkeActuatorFullyActivated 3 "NotAvailable" 2 "Error" 1 "PrkngBrkeActuatorFullyActivated" 0 "PrkngBrkActtorNotFullyActivated";
VAL_ 2566767870 XBRActiveCtrlMode 15 "NotAvailable" 4 "1110ReservedForSAEAssignment" 3 "MxMdOfXBRAcclrtnCtrlBngExecuted" 2 "AddtnMdOfXBRAcclrtnCtrlBngExctd" 1 "DrvrsBrkDmndBngExctdNExtlBrkDmn" 0 "NoBrakeDemandBeingExecuted";
VAL_ 2566767870 XBRSystemState 3 "NotAvailable" 2 "NoExtlBrakeDemandWillBeAccepted" 1 "OnlyExtlBrkDmndOfHghstXBRPrrtyW" 0 "AnyExtlBrkeDemandWillBeAccepted";
VAL_ 2566767870 FoundationBrakeUse 3 "NotAvailable" 2 "Reserved" 1 "FoundationBrakesInUse" 0 "FoundationBrakesNotInUse";
VAL_ 2566767870 HillHolderMode 7 "NotAvailable" 6 "HillHolderNotFunctional" 3 "101Reserved" 2 "ActvBtWllChngTInctvInAShortTime" 1 "Active" 0 "Inactive";
VAL_ 2566767870 HaltBrakeMode 7 "NotAvailable" 6 "Reserved" 3 "101NotDefined" 2 "ActiveButNotFunctioningProperly" 1 "Active" 0 "Inactive";
VAL_ 2565865982 EngAuxShutdownSwitch 3 "NotAvailable" 2 "Error" 1 "On" 0 "Off";
VAL_ 2565865982 TrctrMntdTrilerABSWarningSignal 3 "TakeNoAction" 2 "Reserved" 1 "On" 0 "Off";
VAL_ 2565865982 TrailerABSStatus 3 "NotAvailableOrNotSupported" 2 "Reserved" 1 "TrailerABSActive" 0 "InformationAvailableButNotActive";
VAL_ 2565865982 HaltBrakeSwitch 3 "NotAvailable" 2 "Error" 1 "HaltBrakeSwitchActive" 0 "HaltBrakeSwitchPassive";
VAL_ 2565865982 ATC_ASRInformationSignal 3 "TakeNoAction" 2 "Reserved" 1 "On" 0 "Off";
VAL_ 2565865982 ABS_EBSAmberWarningSignal 3 "TakeNoAction" 2 "Reserved" 1 "On" 0 "Off";
VAL_ 2565865982 EBSRedWarningSignal 3 "TakeNoAction" 2 "Reserved" 1 "On" 0 "Off";
VAL_ 2565865982 ABSFullyOperational 3 "NotAvailable" 2 "Reserved" 1 "FullyOperational" 0 "NotFullyOperational";
VAL_ 2565865982 RemoteAccelEnableSwitch 3 "NotAvailable" 2 "Error" 1 "On" 0 "Off";
VAL_ 2565865982 EngDerateSwitch 3 "NotAvailable" 2 "Error" 1 "On" 0 "Off";
VAL_ 2565865982 AccelInterlockSwitch 3 "NotAvailable" 2 "Error" 1 "On" 0 "Off";
VAL_ 2565865982 TractionCtrlOverrideSwitch 3 "NotAvailableNotInstalled" 2 "Error" 1 "On" 0 "Off";
VAL_ 2565865982 ASRHillHolderSwitch 3 "NotAvailable" 2 "Error" 1 "ASRHillHolderSwitchActive" 0 "ASRHillHolderSwitchPassive";
VAL_ 2565865982 ASROffroadSwitch 2 "Error" 1 "ASROffroadSwitchActive" 0 "ASROffroadSwitchPassive" 3 "NotAvailable";
VAL_ 2565865982 ABSOffroadSwitch 3 "NotAvailable" 2 "Error" 1 "ABSOffroadSwitchActive" 0 "ABSOffroadSwitchPassive";
VAL_ 2565865982 EBSBrakeSwitch 3 "NotAvailable" 2 "Error" 1 "BrakePedalIsBeingPressed" 0 "BrakePedalIsNotBeingPressed";
VAL_ 2565865982 AntiLockBrakingActive 3 "NotAvailable" 2 "Reserved" 1 "ABSActive" 0 "ABSPassiveButInstalled";
VAL_ 2565865982 ASRBrakeCtrlActive 3 "NotAvailable" 2 "Reserved" 1 "ASRBrakeCtrlActive" 0 "ASRBrakeCtrlPassiveButInstalled";
VAL_ 2565865982 ASREngCtrlActive 3 "NotAvailable" 2 "Reserved" 1 "ASREngCtrlActive" 0 "ASREngCtrlPassiveButInstalled";
VAL_ 2565867262 RearAxleGroupEngagementStatus 3 "notAvailable" 2 "error" 1 "rearAxleGroupEngaged" 0 "rearAxleGroupDisengaged";
VAL_ 2565867262 FrontAxleGroupEngagementStatus 3 "notAvailable" 2 "error" 1 "frontAxleGroupEngaged" 0 "frontAxleGroupDisengaged";
VAL_ 2565867262 DiffLockStateCentralRear 3 "NotAvailable" 2 "Error" 1 "DiffLockEngaged" 0 "DiffLockDisengaged";
VAL_ 2565867262 DiffLockStateCentralFront 3 "NotAvailable" 2 "Error" 1 "DiffLockEngaged" 0 "DiffLockDisengaged";
VAL_ 2565867262 DiffLockStateCentral 3 "NotAvailable" 2 "Error" 1 "DiffLockEngaged" 0 "DiffLockDisengaged";
VAL_ 2565867262 DiffLockStateRearAxle2 3 "NotAvailable" 2 "Error" 1 "DiffLockEngaged" 0 "DiffLockDisengaged";
VAL_ 2565867262 DiffLockStateRearAxle1 3 "NotAvailable" 2 "Error" 1 "DiffLockEngaged" 0 "DiffLockDisengaged";
VAL_ 2565867262 DiffLockStateFrontAxle2 3 "NotAvailable" 2 "Error" 1 "DiffLockEngaged" 0 "DiffLockDisengaged";
VAL_ 2565867262 DiffLockStateFrontAxle1 3 "NotAvailable" 2 "Error" 1 "DiffLockEngaged" 0 "DiffLockDisengaged";
